VERSION ""

NS_ :

BS_:

BU_: PowertrainControlModule AtmosphericSensor SafetyRestraintSystem2 Aftertreatment_2_GasOutlet Aftertreatment_2_GasIntake DieselPartFilterControl Turbocharger SafetyRestraintSystem1 CabDisplay2 Aftertreatment_1_GasOutlet Aftertreatment_1_GasIntake OnBoardDataLogger OffBoardDiagnosticTool2 OffBoardDiagnosticTool1 FileServer ParkingBrakeController SeatController2 FanDriveController SteeringColumnUnit CommunicationUnitRadio CommunicationUnitSatellite CommunicationUnitCellular PropulsionBatteryCharger ChassisController2 ChassisController1 EngineValveControl AuxiliaryHeater2 AuxiliaryHeater1 ClutchUnit RampControl InformationSystem1 SuspensionSystemController2 OilSensor VehicleDynamicStability ExhaustEmissionController TransmissionDisplay2 TransmissionDisplay1 ClimateControl2 WaterPumpController RearAxleSteeringController LightingOperatorControl SeatController1 IgnitionController2 IgnitionController1 TirePressureController CabController2 CabController1 PneumaticSystemController SuspensionSystemController1 HydraulicPumpController EnduranceBrakingSystem RetarderExhaustEngine2 OnBoardDiagnosticUnit HeadwayController RetarderExhaustEngine1 CabDisplay1 ManagementComputer VirtualTerminal OffVehicleGateway PowerTakeOffFront HitchControl AuxiliaryValveControl BodyController TractorTrailerBridge1 StarterSystem ElectricalSystem VehicleSecurity VehicleNavigation AerodynamicControl ElectricalChargingSystem ClimateControl1 TripRecorder InstrumentCluster SuspensionDriveAxle2 SuspensionDriveAxle1 SuspensionSteerAxle SteeringController FuelSystem CruiseControl RetarderDriveline RetarderEngine BrakesDriveAxle2 BrakesDriveAxle1 BrakesSystemController BrakesSteerAxle AxleDrive2 AxleDrive1 AxleSteering PowerTakeOff ShiftConsoleSecondary ShiftConsolePrimary Transmission2 Transmission1 Engine2 Engine1

BO_ 2566842878 LFC1: 8 Vector__XXX
 SG_ EngTotalFuelUsed : 32|32@1+ (0.5,0) [0|2105540607.5] "L" Vector__XXX
 SG_ EngTripFuel : 0|32@1+ (0.5,0) [0|2105540607.5] "L" Vector__XXX

BO_ 2633883646 FWD: 8 Vector__XXX
 SG_ FrontWheelDriveActuatorStatus : 0|2@1+ (1,0) [0|3] "" Vector__XXX

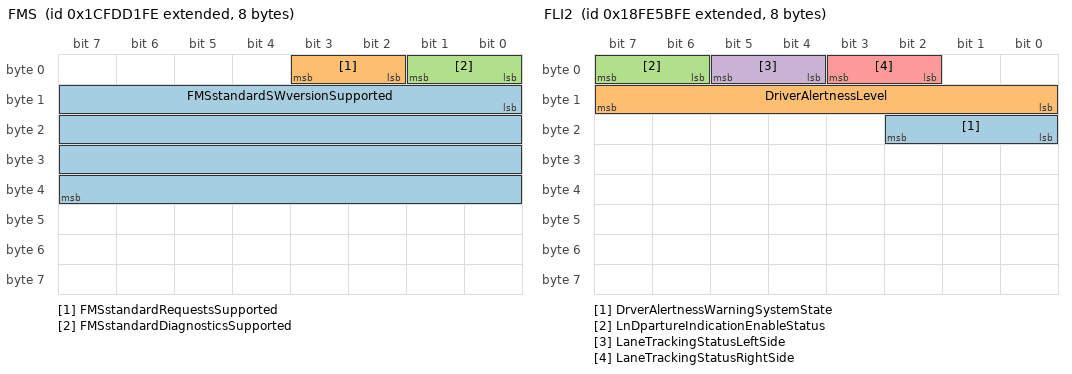
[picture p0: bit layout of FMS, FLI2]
BO_ 2633880062 FMS: 8 Vector__XXX
 SG_ FMSstandardSWversionSupported : 8|32@1+ (1,0) [0|255] "" Vector__XXX
 SG_ FMSstandardRequestsSupported : 2|2@1+ (1,0) [0|3] "" Vector__XXX
 SG_ FMSstandardDiagnosticsSupported : 0|2@1+ (1,0) [0|3] "" Vector__XXX

BO_ 2566806526 FLI2: 8 Vector__XXX
 SG_ DrverAlertnessWarningSystemState : 16|3@1+ (1,0) [0|7] "" Vector__XXX
 SG_ DriverAlertnessLevel : 8|8@1+ (0.4,0) [0|100] "%" Vector__XXX
 SG_ LnDpartureIndicationEnableStatus : 6|2@1+ (1,0) [0|3] "" Vector__XXX
 SG_ LaneTrackingStatusLeftSide : 4|2@1+ (1,0) [0|3] "" Vector__XXX
 SG_ LaneTrackingStatusRightSide : 2|2@1+ (1,0) [0|3] "" Vector__XXX

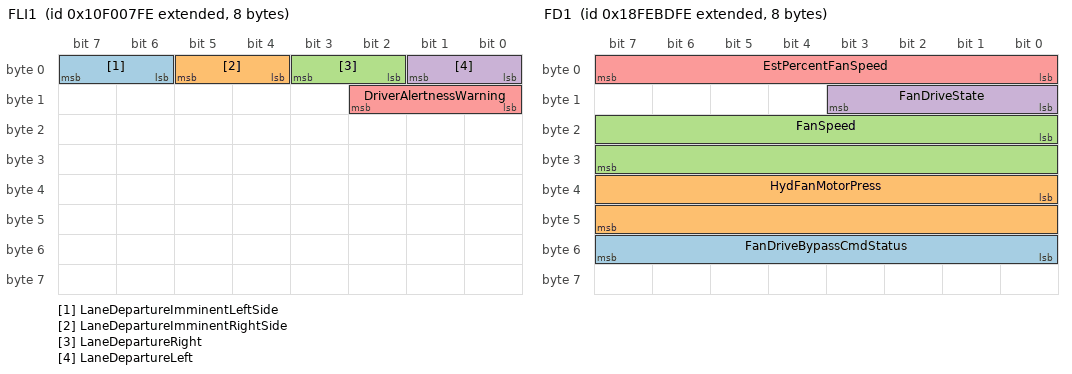
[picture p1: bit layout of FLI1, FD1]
BO_ 2431649790 FLI1: 8 Vector__XXX
 SG_ LaneDepartureImminentLeftSide : 6|2@1+ (1,0) [0|3] "" Vector__XXX
 SG_ LaneDepartureImminentRightSide : 4|2@1+ (1,0) [0|3] "" Vector__XXX
 SG_ LaneDepartureRight : 2|2@1+ (1,0) [0|3] "" Vector__XXX
 SG_ LaneDepartureLeft : 0|2@1+ (1,0) [0|3] "" Vector__XXX
 SG_ DriverAlertnessWarning : 8|3@1+ (1,0) [0|7] "" Vector__XXX

BO_ 2633929214 FL: 8 Vector__XXX
 SG_ EngFuelLeakage2 : 2|2@1+ (1,0) [0|3] "" Vector__XXX
 SG_ EngFuelLeakage1 : 0|2@1+ (1,0) [0|3] "" Vector__XXX

BO_ 2566831614 FD1: 8 Vector__XXX
 SG_ FanDriveBypassCmdStatus : 48|8@1+ (0.4,0) [0|100] "%" Vector__XXX
 SG_ HydFanMotorPress : 32|16@1+ (0.5,0) [0|32127.5] "kPa" Vector__XXX
 SG_ FanSpeed : 16|16@1+ (0.125,0) [0|8031.875] "rpm" Vector__XXX
 SG_ FanDriveState : 8|4@1+ (1,0) [0|15] "" Vector__XXX
 SG_ EstPercentFanSpeed : 0|8@1+ (0.4,0) [0|100] "%" Vector__XXX

BO_ 2566820094 ETH: 8 Vector__XXX
 SG_ EngTorqueLimit6AxleInput : 248|16@1+ (2,0) [0|128510] "Nm" Vector__XXX
 SG_ EngTorqueLimit5Switch : 232|16@1+ (1,0) [0|64255] "Nm" Vector__XXX
 SG_ EngTorqueLimit4Trans : 216|16@1+ (1,0) [0|64255] "Nm" Vector__XXX
 SG_ EngTorqueLimit3Trans : 200|16@1+ (1,0) [0|64255] "Nm" Vector__XXX
 SG_ TransGearRatio3 : 184|16@1+ (0.01,0) [0|642.55] "" Vector__XXX
 SG_ EngTorqueLimit2Trans : 168|16@1+ (1,0) [0|64255] "Nm" Vector__XXX
 SG_ TransGearRatio2 : 152|16@1+ (0.01,0) [0|642.55] "" Vector__XXX
 SG_ EngTorqueLimit1Trans : 136|16@1+ (1,0) [0|64255] "Nm" Vector__XXX
 SG_ TransGearRatio1 : 120|16@1+ (0.01,0) [0|642.55] "" Vector__XXX
 SG_ EngTorqueLimitFeature : 114|3@1+ (1,0) [0|7] "" Vector__XXX
 SG_ TorqueLimitingFeatureStatus : 112|2@1+ (1,0) [0|3] "" Vector__XXX
 SG_ CalibRecordDurationTime : 80|32@1+ (0.05,0) [0|210554060.75] "h" Vector__XXX
 SG_ CalibRecordStartYear : 72|8@1+ (1,1985) [1985|2235] "years" Vector__XXX
 SG_ CalibRecordStartDay : 64|8@1+ (0.25,0) [0.25|31.75] "days" Vector__XXX
 SG_ CalibRecordStartMonth : 56|8@1+ (1,0) [1|12] "months" Vector__XXX
 SG_ EngPeakTorque2 : 40|16@1+ (1,0) [0|64255] "Nm" Vector__XXX
 SG_ EngPeakTorque1 : 24|16@1+ (1,0) [0|64255] "Nm" Vector__XXX
 SG_ EngPower : 8|16@1+ (0.5,0) [0|32127.5] "kW" Vector__XXX
 SG_ NumberOfEngTorqueHistoryRecords : 0|8@1+ (1,0) [0|250] "records" Vector__XXX

BO_ 2364542206 ETC8: 8 Vector__XXX
 SG_ TransClutch_ConverterInputSpeed : 16|16@1+ (0.125,0) [0|8031.875] "rpm" Vector__XXX
 SG_ TransTorqueConverterRatio : 0|16@1+ (0.001,0) [0|64.255] "" Vector__XXX

BO_ 2566802174 ETC7: 8 Vector__XXX
 SG_ TransAutoNeutralSt : 50|2@1+ (1,0) [0|3] "" Vector__XXX
 SG_ TransWarningIndicator : 42|2@1+ (1,0) [0|3] "" Vector__XXX
 SG_ TrnsRverseGearShiftInhibitStatus : 40|2@1+ (1,0) [0|3] "" Vector__XXX
 SG_ TransMode8Indicator : 38|2@1+ (1,0) [0|3] "" Vector__XXX
 SG_ TransMode7Indicator : 36|2@1+ (1,0) [0|3] "" Vector__XXX
 SG_ TransMode6Indicator : 34|2@1+ (1,0) [0|3] "" Vector__XXX
 SG_ TransMode5Indicator : 32|2@1+ (1,0) [0|3] "" Vector__XXX
 SG_ TransRequestedGearFeedback : 24|8@1+ (1,-125) [-125|125] "" Vector__XXX
 SG_ TransMode1Indicator : 22|2@1+ (1,0) [0|3] "" Vector__XXX
 SG_ TransMode2Indicator : 20|2@1+ (1,0) [0|3] "" Vector__XXX
 SG_ TransMode3Indicator : 18|2@1+ (1,0) [0|3] "" Vector__XXX
 SG_ TransMode4Indicator : 16|2@1+ (1,0) [0|3] "" Vector__XXX
 SG_ TransShiftInhibitIndicator : 14|2@1+ (1,0) [0|3] "" Vector__XXX
 SG_ TransEngCrankEnable : 12|2@1+ (1,0) [0|3] "" Vector__XXX
 SG_ ActiveShiftConsoleIndicator : 10|2@1+ (1,0) [0|3] "" Vector__XXX
 SG_ TransReadyForBrakeRelease : 8|2@1+ (1,0) [0|3] "" Vector__XXX
 SG_ TrnsRqstedRangeDisplayFlashState : 6|2@1+ (1,0) [0|3] "" Vector__XXX
 SG_ TrnsRqstedRangeDisplayBlankState : 4|2@1+ (1,0) [0|3] "" Vector__XXX
 SG_ TransServiceIndicator : 2|2@1+ (1,0) [0|3] "" Vector__XXX
 SG_ TransAirSupplyPressIndicator : 48|2@1+ (1,0) [0|3] "" Vector__XXX
 SG_ TransMode10Indicator : 46|2@1+ (1,0) [0|3] "" Vector__XXX
 SG_ TransMode9Indicator : 44|2@1+ (1,0) [0|3] "" Vector__XXX
 SG_ TrnsCrrentRangeDisplayBlankState : 0|2@1+ (1,0) [0|3] "" Vector__XXX

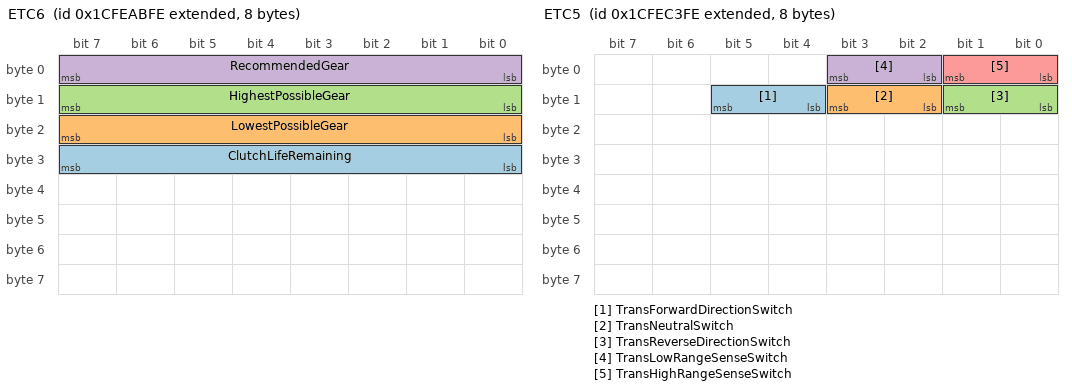
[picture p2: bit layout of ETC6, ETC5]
BO_ 2633935870 ETC6: 8 Vector__XXX
 SG_ ClutchLifeRemaining : 24|8@1+ (0.4,0) [0|100] "%" Vector__XXX
 SG_ LowestPossibleGear : 16|8@1+ (1,-125) [-125|125] "" Vector__XXX
 SG_ HighestPossibleGear : 8|8@1+ (1,-125) [-125|125] "" Vector__XXX
 SG_ RecommendedGear : 0|8@1+ (1,-125) [-125|125] "" Vector__XXX

BO_ 2633942014 ETC5: 8 Vector__XXX
 SG_ TransForwardDirectionSwitch : 12|2@1+ (1,0) [0|3] "" Vector__XXX
 SG_ TransNeutralSwitch : 10|2@1+ (1,0) [0|3] "" Vector__XXX
 SG_ TransReverseDirectionSwitch : 8|2@1+ (1,0) [0|3] "" Vector__XXX
 SG_ TransLowRangeSenseSwitch : 2|2@1+ (1,0) [0|3] "" Vector__XXX
 SG_ TransHighRangeSenseSwitch : 0|2@1+ (1,0) [0|3] "" Vector__XXX

BO_ 2633942526 ETC4: 8 Vector__XXX
 SG_ TransSynchronizerBrakeValue : 8|8@1+ (0.4,0) [0|100] "%" Vector__XXX
 SG_ TransSynchronizerClutchValue : 0|8@1+ (0.4,0) [0|100] "%" Vector__XXX

BO_ 2633943038 ETC3: 8 Vector__XXX
 SG_ TransInertiaBrakeActuator : 46|2@1+ (1,0) [0|3] "" Vector__XXX
 SG_ TransDefuelActuator : 44|2@1+ (1,0) [0|3] "" Vector__XXX
 SG_ TransLockupClutchActuator : 42|2@1+ (1,0) [0|3] "" Vector__XXX
 SG_ TransClutchActuator : 40|2@1+ (1,0) [0|3] "" Vector__XXX
 SG_ TransSplitterIndirectActuator : 38|2@1+ (1,0) [0|3] "" Vector__XXX
 SG_ TransSplitterDirectActuator : 36|2@1+ (1,0) [0|3] "" Vector__XXX
 SG_ TransRangeLowActuator : 34|2@1+ (1,0) [0|3] "" Vector__XXX
 SG_ TransRangeHighActuator : 32|2@1+ (1,0) [0|3] "" Vector__XXX
 SG_ TransShiftFingerGearActuator2 : 30|2@1+ (1,0) [0|3] "" Vector__XXX
 SG_ TransShiftFingerRailActuator2 : 28|2@1+ (1,0) [0|3] "" Vector__XXX
 SG_ TransShiftFingerGearActuator1 : 26|2@1+ (1,0) [0|3] "" Vector__XXX
 SG_ TransShiftFingerRailActuator1 : 24|2@1+ (1,0) [0|3] "" Vector__XXX
 SG_ TrnsShftFngerCenterRailIndicator : 20|2@1+ (1,0) [0|3] "" Vector__XXX
 SG_ TrnsShftFngerEngagementIndicator : 18|2@1+ (1,0) [0|3] "" Vector__XXX
 SG_ TransShiftFingerNeutralIndicator : 16|2@1+ (1,0) [0|3] "" Vector__XXX
 SG_ TransShiftFingerRailPos : 8|8@1+ (0.4,0) [0|100] "%" Vector__XXX
 SG_ TransShiftFingerGearPos : 0|8@1+ (0.4,0) [0|100] "%" Vector__XXX

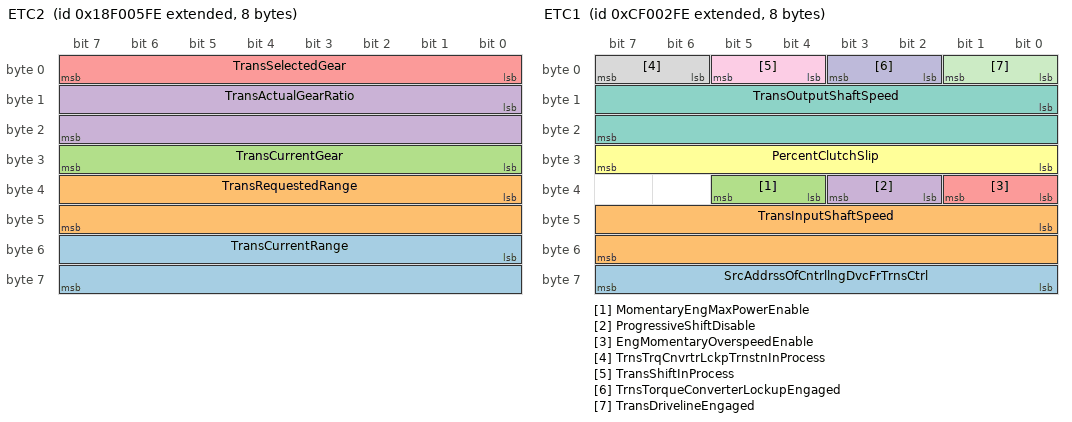
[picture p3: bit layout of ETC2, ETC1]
BO_ 2565867006 ETC2: 8 Vector__XXX
 SG_ TransCurrentRange : 48|16@1+ (1,0) [0|255] "" Vector__XXX
 SG_ TransRequestedRange : 32|16@1+ (1,0) [0|255] "" Vector__XXX
 SG_ TransCurrentGear : 24|8@1+ (1,-125) [-125|125] "" Vector__XXX
 SG_ TransActualGearRatio : 8|16@1+ (0.001,0) [0|64.255] "" Vector__XXX
 SG_ TransSelectedGear : 0|8@1+ (1,-125) [-125|125] "" Vector__XXX

BO_ 2364539646 ETC1: 8 Vector__XXX
 SG_ SrcAddrssOfCntrllngDvcFrTrnsCtrl : 56|8@1+ (1,0) [0|253] "" Vector__XXX
 SG_ TransInputShaftSpeed : 40|16@1+ (0.125,0) [0|8031.875] "rpm" Vector__XXX
 SG_ MomentaryEngMaxPowerEnable : 36|2@1+ (1,0) [0|3] "" Vector__XXX
 SG_ ProgressiveShiftDisable : 34|2@1+ (1,0) [0|3] "" Vector__XXX
 SG_ EngMomentaryOverspeedEnable : 32|2@1+ (1,0) [0|3] "" Vector__XXX
 SG_ PercentClutchSlip : 24|8@1+ (0.4,0) [0|100] "%" Vector__XXX
 SG_ TransOutputShaftSpeed : 8|16@1+ (0.125,0) [0|8031.875] "rpm" Vector__XXX
 SG_ TrnsTrqCnvrtrLckpTrnstnInProcess : 6|2@1+ (1,0) [0|3] "" Vector__XXX
 SG_ TransShiftInProcess : 4|2@1+ (1,0) [0|3] "" Vector__XXX
 SG_ TrnsTorqueConverterLockupEngaged : 2|2@1+ (1,0) [0|3] "" Vector__XXX
 SG_ TransDrivelineEngaged : 0|2@1+ (1,0) [0|3] "" Vector__XXX

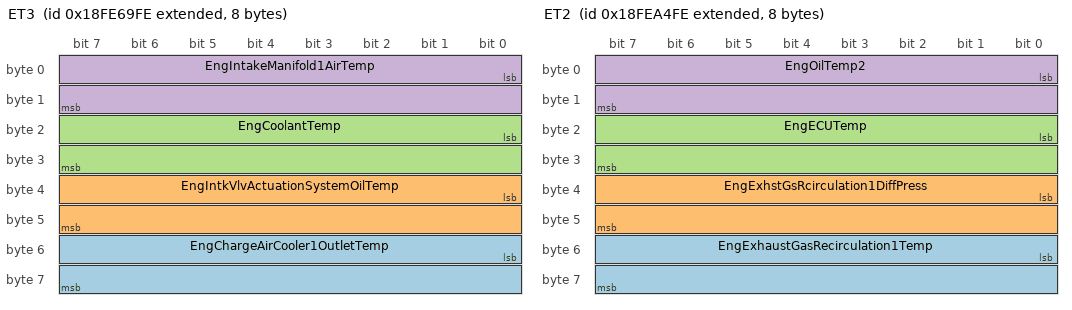
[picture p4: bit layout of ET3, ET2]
BO_ 2566810110 ET3: 8 Vector__XXX
 SG_ EngChargeAirCooler1OutletTemp : 48|16@1+ (0.03125,-273) [-273|1734.96875] "°C" Vector__XXX
 SG_ EngIntkVlvActuationSystemOilTemp : 32|16@1+ (0.03125,-273) [-273|1734.96875] "°C" Vector__XXX
 SG_ EngCoolantTemp : 16|16@1+ (0.03125,-273) [-273|1734.96875] "°C" Vector__XXX
 SG_ EngIntakeManifold1AirTemp : 0|16@1+ (0.03125,-273) [-273|1734.96875] "°C" Vector__XXX

BO_ 2566825214 ET2: 8 Vector__XXX
 SG_ EngExhaustGasRecirculation1Temp : 48|16@1+ (0.03125,-273) [-273|1734.96875] "°C" Vector__XXX
 SG_ EngExhstGsRcirculation1DiffPress : 32|16@1+ (0.0078125,-250) [-250|251.99] "kPa" Vector__XXX
 SG_ EngECUTemp : 16|16@1+ (0.03125,-273) [-273|1734.96875] "°C" Vector__XXX
 SG_ EngOilTemp2 : 0|16@1+ (0.03125,-273) [-273|1734.96875] "°C" Vector__XXX

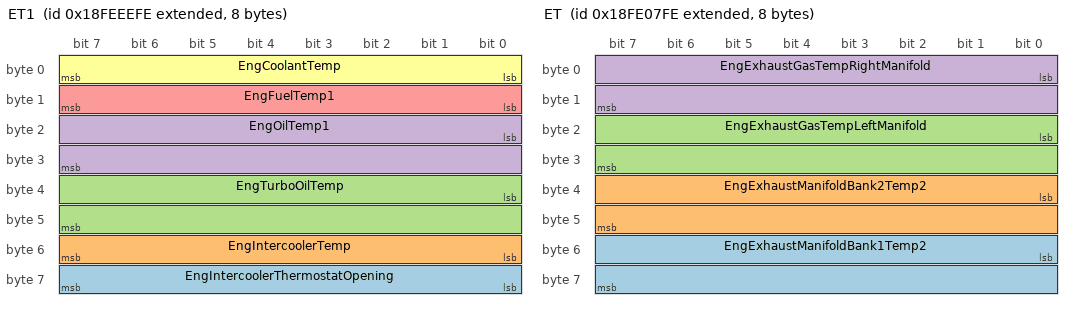
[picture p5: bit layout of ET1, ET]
BO_ 2566844158 ET1: 8 Vector__XXX
 SG_ EngIntercoolerThermostatOpening : 56|8@1+ (0.4,0) [0|100] "%" Vector__XXX
 SG_ EngIntercoolerTemp : 48|8@1+ (1,-40) [-40|210] "°C" Vector__XXX
 SG_ EngTurboOilTemp : 32|16@1+ (0.03125,-273) [-273|1734.96875] "°C" Vector__XXX
 SG_ EngOilTemp1 : 16|16@1+ (0.03125,-273) [-273|1734.96875] "°C" Vector__XXX
 SG_ EngFuelTemp1 : 8|8@1+ (1,-40) [-40|210] "°C" Vector__XXX
 SG_ EngCoolantTemp : 0|8@1+ (1,-40) [-40|210] "°C" Vector__XXX

BO_ 2566785022 ET: 8 Vector__XXX
 SG_ EngExhaustManifoldBank1Temp2 : 48|16@1+ (0.03125,-273) [-273|1734.96875] "°C" Vector__XXX
 SG_ EngExhaustManifoldBank2Temp2 : 32|16@1+ (0.03125,-273) [-273|1734.96875] "°C" Vector__XXX
 SG_ EngExhaustGasTempLeftManifold : 16|16@1+ (0.03125,-273) [-273|1734.96875] "°C" Vector__XXX
 SG_ EngExhaustGasTempRightManifold : 0|16@1+ (0.03125,-273) [-273|1734.96875] "°C" Vector__XXX

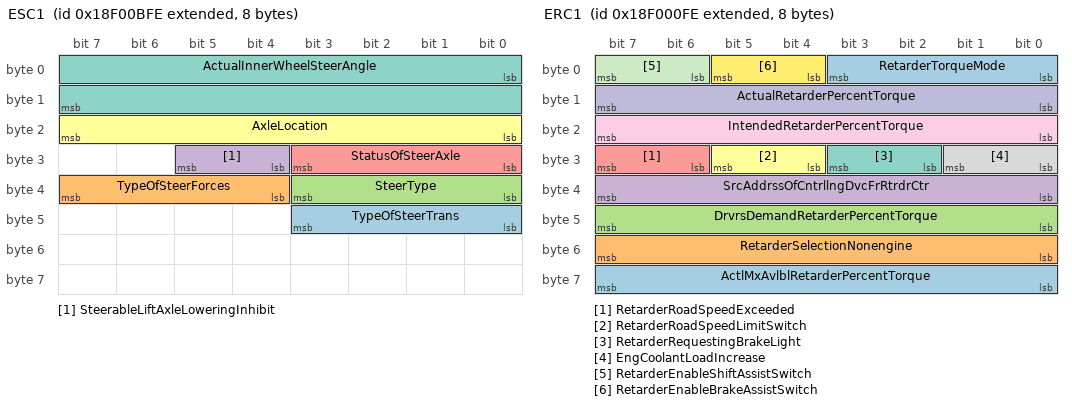
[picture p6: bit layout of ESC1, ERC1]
BO_ 2565868542 ESC1: 8 Vector__XXX
 SG_ TypeOfSteerTrans : 40|4@1+ (1,0) [0|15] "" Vector__XXX
 SG_ TypeOfSteerForces : 36|4@1+ (1,0) [0|15] "" Vector__XXX
 SG_ SteerType : 32|4@1+ (1,0) [0|15] "" Vector__XXX
 SG_ SteerableLiftAxleLoweringInhibit : 28|2@1+ (1,0) [0|3] "" Vector__XXX
 SG_ StatusOfSteerAxle : 24|4@1+ (1,0) [0|15] "" Vector__XXX
 SG_ AxleLocation : 16|8@1+ (1,0) [0|255] "" Vector__XXX
 SG_ ActualInnerWheelSteerAngle : 0|16@1+ (0.00390625,-125) [-125|125] "deg" Vector__XXX

BO_ 2633941758 ERC2: 8 Vector__XXX
 SG_ CrsCtrlRetarderActiveSpeedOffset : 8|16@1+ (0.00390625,-125) [0|125.996] "km/h" Vector__XXX
 SG_ TransOutputRetarder : 0|2@1+ (1,0) [0|3] "" Vector__XXX

BO_ 2565865726 ERC1: 8 Vector__XXX
 SG_ ActlMxAvlblRetarderPercentTorque : 56|8@1+ (1,-125) [-125|0] "%" Vector__XXX
 SG_ RetarderSelectionNonengine : 48|8@1+ (0.4,0) [0|100] "%" Vector__XXX
 SG_ DrvrsDemandRetarderPercentTorque : 40|8@1+ (1,-125) [-125|0] "%" Vector__XXX
 SG_ SrcAddrssOfCntrllngDvcFrRtrdrCtr : 32|8@1+ (1,0) [0|253] "" Vector__XXX
 SG_ RetarderRoadSpeedExceeded : 30|2@1+ (1,0) [0|3] "" Vector__XXX
 SG_ RetarderRoadSpeedLimitSwitch : 28|2@1+ (1,0) [0|3] "" Vector__XXX
 SG_ RetarderRequestingBrakeLight : 26|2@1+ (1,0) [0|3] "" Vector__XXX
 SG_ EngCoolantLoadIncrease : 24|2@1+ (1,0) [0|3] "" Vector__XXX
 SG_ IntendedRetarderPercentTorque : 16|8@1+ (1,-125) [-125|0] "%" Vector__XXX
 SG_ ActualRetarderPercentTorque : 8|8@1+ (1,-125) [-125|0] "%" Vector__XXX
 SG_ RetarderEnableShiftAssistSwitch : 6|2@1+ (1,0) [0|3] "" Vector__XXX
 SG_ RetarderEnableBrakeAssistSwitch : 4|2@1+ (1,0) [0|3] "" Vector__XXX
 SG_ RetarderTorqueMode : 0|4@1+ (1,0) [0|15] "" Vector__XXX

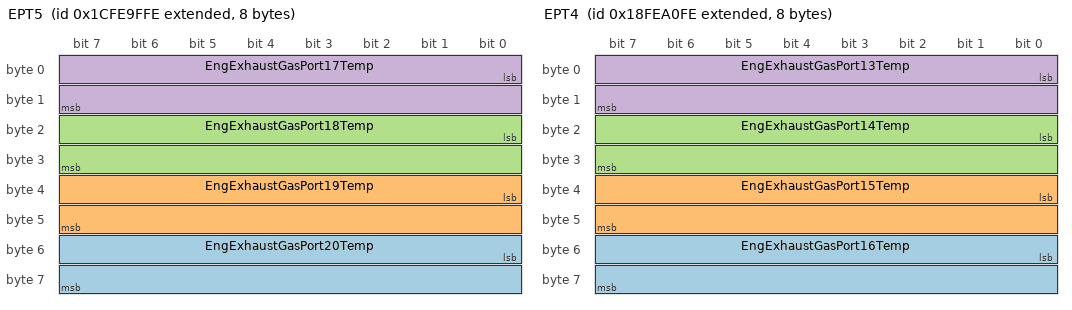
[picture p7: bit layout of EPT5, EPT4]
BO_ 2633932798 EPT5: 8 Vector__XXX
 SG_ EngExhaustGasPort20Temp : 48|16@1+ (0.03125,-273) [-273|1734.96875] "°C" Vector__XXX
 SG_ EngExhaustGasPort19Temp : 32|16@1+ (0.03125,-273) [-273|1734.96875] "°C" Vector__XXX
 SG_ EngExhaustGasPort18Temp : 16|16@1+ (0.03125,-273) [-273|1734.96875] "°C" Vector__XXX
 SG_ EngExhaustGasPort17Temp : 0|16@1+ (0.03125,-273) [-273|1734.96875] "°C" Vector__XXX

BO_ 2566824190 EPT4: 8 Vector__XXX
 SG_ EngExhaustGasPort16Temp : 48|16@1+ (0.03125,-273) [-273|1734.96875] "°C" Vector__XXX
 SG_ EngExhaustGasPort15Temp : 32|16@1+ (0.03125,-273) [-273|1734.96875] "°C" Vector__XXX
 SG_ EngExhaustGasPort14Temp : 16|16@1+ (0.03125,-273) [-273|1734.96875] "°C" Vector__XXX
 SG_ EngExhaustGasPort13Temp : 0|16@1+ (0.03125,-273) [-273|1734.96875] "°C" Vector__XXX

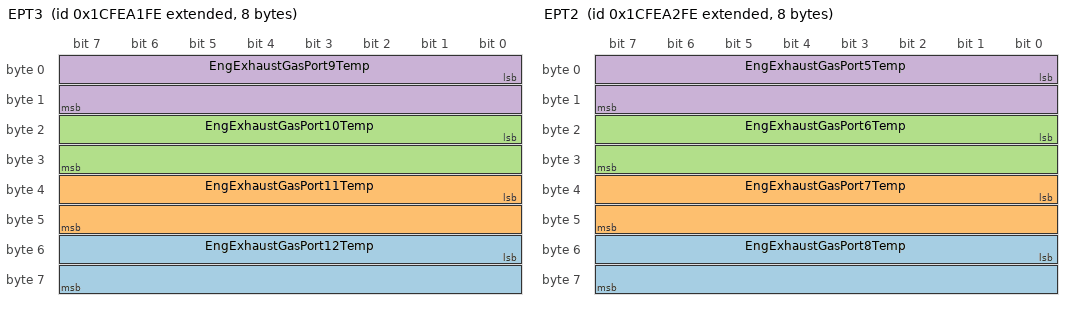
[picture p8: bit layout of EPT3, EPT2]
BO_ 2633933310 EPT3: 8 Vector__XXX
 SG_ EngExhaustGasPort12Temp : 48|16@1+ (0.03125,-273) [-273|1734.96875] "°C" Vector__XXX
 SG_ EngExhaustGasPort11Temp : 32|16@1+ (0.03125,-273) [-273|1734.96875] "°C" Vector__XXX
 SG_ EngExhaustGasPort10Temp : 16|16@1+ (0.03125,-273) [-273|1734.96875] "°C" Vector__XXX
 SG_ EngExhaustGasPort9Temp : 0|16@1+ (0.03125,-273) [-273|1734.96875] "°C" Vector__XXX

BO_ 2633933566 EPT2: 8 Vector__XXX
 SG_ EngExhaustGasPort8Temp : 48|16@1+ (0.03125,-273) [-273|1734.96875] "°C" Vector__XXX
 SG_ EngExhaustGasPort7Temp : 32|16@1+ (0.03125,-273) [-273|1734.96875] "°C" Vector__XXX
 SG_ EngExhaustGasPort6Temp : 16|16@1+ (0.03125,-273) [-273|1734.96875] "°C" Vector__XXX
 SG_ EngExhaustGasPort5Temp : 0|16@1+ (0.03125,-273) [-273|1734.96875] "°C" Vector__XXX

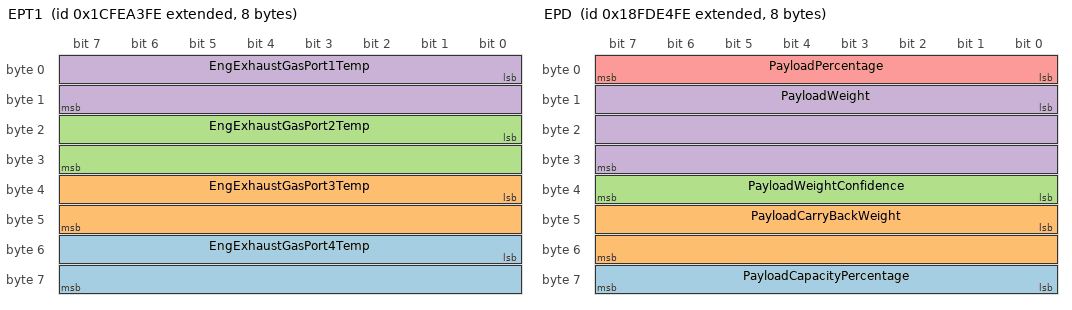
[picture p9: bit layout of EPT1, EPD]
BO_ 2633933822 EPT1: 8 Vector__XXX
 SG_ EngExhaustGasPort4Temp : 48|16@1+ (0.03125,-273) [-273|1734.96875] "°C" Vector__XXX
 SG_ EngExhaustGasPort3Temp : 32|16@1+ (0.03125,-273) [-273|1734.96875] "°C" Vector__XXX
 SG_ EngExhaustGasPort2Temp : 16|16@1+ (0.03125,-273) [-273|1734.96875] "°C" Vector__XXX
 SG_ EngExhaustGasPort1Temp : 0|16@1+ (0.03125,-273) [-273|1734.96875] "°C" Vector__XXX

BO_ 2566776062 EPD: 8 Vector__XXX
 SG_ PayloadCapacityPercentage : 56|8@1+ (1,0) [0|250] "%" Vector__XXX
 SG_ PayloadCarryBackWeight : 40|16@1+ (2,0) [0|128510] "kg" Vector__XXX
 SG_ PayloadWeightConfidence : 32|8@1+ (0.5,0) [0|100] "%" Vector__XXX
 SG_ PayloadWeight : 8|24@1+ (2,0) [0|32899070] "kg" Vector__XXX
 SG_ PayloadPercentage : 0|8@1+ (1,0) [0|250] "%" Vector__XXX

BO_ 2566771454 EP: 8 Vector__XXX
 SG_ DataMemoryUsage : 16|8@1+ (0.4,0) [0|100] "%" Vector__XXX
 SG_ KeepAliveBatteryConsumption : 0|16@1+ (1,0) [0|64255] "mAh" Vector__XXX

BO_ 2566775806 EOAC: 8 Vector__XXX
 SG_ TravelVelocityCtrlPos : 0|8@1+ (1,-125) [-125|125] "%" Vector__XXX

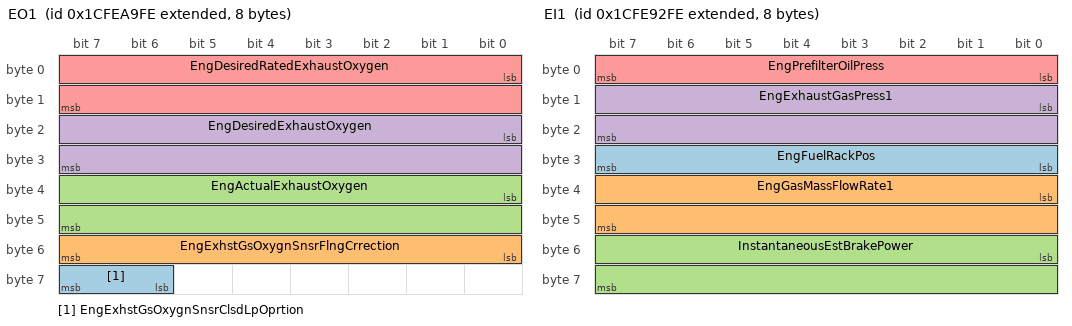
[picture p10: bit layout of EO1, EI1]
BO_ 2633935358 EO1: 8 Vector__XXX
 SG_ EngExhstGsOxygnSnsrClsdLpOprtion : 62|2@1+ (1,0) [0|3] "" Vector__XXX
 SG_ EngExhstGsOxygnSnsrFlngCrrection : 48|8@1+ (1,-125) [-125|125] "%" Vector__XXX
 SG_ EngActualExhaustOxygen : 32|16@1+ (0.0025,0) [0|160.6375] "%" Vector__XXX
 SG_ EngDesiredExhaustOxygen : 16|16@1+ (0.0025,0) [0|160.6375] "%" Vector__XXX
 SG_ EngDesiredRatedExhaustOxygen : 0|16@1+ (0.0025,0) [0|160.6375] "%" Vector__XXX

BO_ 2365447166 EJM3: 8 Vector__XXX
 SG_ Joystick3Button13PressedStatus : 62|2@1+ (1,0) [0|3] "" Vector__XXX
 SG_ Joystick3Button14PressedStatus : 60|2@1+ (1,0) [0|3] "" Vector__XXX
 SG_ Joystick3Button15PressedStatus : 58|2@1+ (1,0) [0|3] "" Vector__XXX
 SG_ Joystick3Button16PressedStatus : 56|2@1+ (1,0) [0|3] "" Vector__XXX
 SG_ Jystick3GripXAxisDetentPosStatus : 54|2@1+ (1,0) [0|3] "" Vector__XXX
 SG_ Jystick3GripYAxisDetentPosStatus : 52|2@1+ (1,0) [0|3] "" Vector__XXX
 SG_ Jystick3ThetaAxisDetentPosStatus : 50|2@1+ (1,0) [0|3] "" Vector__XXX
 SG_ Joystick3ThetaAxisPos : 38|10@1+ (0.1,0) [0|100] "%" Vector__XXX
 SG_ Jystck3ThtAxsClckwsPstvPosStatus : 36|2@1+ (1,0) [0|3] "" Vector__XXX
 SG_ Jystck3ThetaAxisNeutralPosStatus : 32|2@1+ (1,0) [0|3] "" Vector__XXX
 SG_ Joystick3GripYAxisPos : 22|10@1+ (0.1,0) [0|100] "%" Vector__XXX
 SG_ Jystck3GrpYAxsLvrFrwrdPstvPsStts : 20|2@1+ (1,0) [0|3] "" Vector__XXX
 SG_ Jystck3GrpYAxsLvrBckNgtvPsStatus : 18|2@1+ (1,0) [0|3] "" Vector__XXX
 SG_ Jystck3GripYAxisNeutralPosStatus : 16|2@1+ (1,0) [0|3] "" Vector__XXX
 SG_ Joystick3GripXAxisPos : 6|10@1+ (0.1,0) [0|100] "%" Vector__XXX
 SG_ Jystck3GrpXAxsLvrRghtPstvPsSttus : 4|2@1+ (1,0) [0|3] "" Vector__XXX
 SG_ Jystck3GrpXAxsLvrLftNgtvPsStatus : 2|2@1+ (1,0) [0|3] "" Vector__XXX
 SG_ Jystck3GripXAxisNeutralPosStatus : 0|2@1+ (1,0) [0|3] "" Vector__XXX
 SG_ Jystck3ThtAxsCntrClckwsNgtvPsStt : 34|2@1+ (1,0) [0|3] "" Vector__XXX

BO_ 2365446654 EJM2: 8 Vector__XXX
 SG_ Joystick2Button13PressedStatus : 62|2@1+ (1,0) [0|3] "" Vector__XXX
 SG_ Joystick2Button14PressedStatus : 60|2@1+ (1,0) [0|3] "" Vector__XXX
 SG_ Joystick2Button15PressedStatus : 58|2@1+ (1,0) [0|3] "" Vector__XXX
 SG_ Joystick2Button16PressedStatus : 56|2@1+ (1,0) [0|3] "" Vector__XXX
 SG_ Jystick2GripXAxisDetentPosStatus : 54|2@1+ (1,0) [0|3] "" Vector__XXX
 SG_ Jystick2GripYAxisDetentPosStatus : 52|2@1+ (1,0) [0|3] "" Vector__XXX
 SG_ Jystick2ThetaAxisDetentPosStatus : 50|2@1+ (1,0) [0|3] "" Vector__XXX
 SG_ Joystick2ThetaAxisPos : 38|10@1+ (0.1,0) [0|100] "%" Vector__XXX
 SG_ Jystck2ThtAxsClckwsPstvPosStatus : 36|2@1+ (1,0) [0|3] "" Vector__XXX
 SG_ Jystck2ThetaAxisNeutralPosStatus : 32|2@1+ (1,0) [0|3] "" Vector__XXX
 SG_ Joystick2GripYAxisPos : 22|10@1+ (0.1,0) [0|100] "%" Vector__XXX
 SG_ Jystck2GrpYAxsLvrFrwrdPstvPsStts : 20|2@1+ (1,0) [0|3] "" Vector__XXX
 SG_ Jystck2GrpYAxsLvrBckNgtvPsStatus : 18|2@1+ (1,0) [0|3] "" Vector__XXX
 SG_ Jystck2GripYAxisNeutralPosStatus : 16|2@1+ (1,0) [0|3] "" Vector__XXX
 SG_ Joystick2GripXAxisPos : 6|10@1+ (0.1,0) [0|100] "%" Vector__XXX
 SG_ Jystck2GrpXAxsLvrRghtPstvPsSttus : 4|2@1+ (1,0) [0|3] "" Vector__XXX
 SG_ Jystck2GrpXAxsLvrLftNgtvPsStatus : 2|2@1+ (1,0) [0|3] "" Vector__XXX
 SG_ Jystck2GripXAxisNeutralPosStatus : 0|2@1+ (1,0) [0|3] "" Vector__XXX
 SG_ Jystck2ThtAxsCntrClckwsNgtvPsStt : 34|2@1+ (1,0) [0|3] "" Vector__XXX

BO_ 2365446142 EJM1: 8 Vector__XXX
 SG_ Joystick1Button13PressedStatus : 62|2@1+ (1,0) [0|3] "" Vector__XXX
 SG_ Joystick1Button14PressedStatus : 60|2@1+ (1,0) [0|3] "" Vector__XXX
 SG_ Joystick1Button15PressedStatus : 58|2@1+ (1,0) [0|3] "" Vector__XXX
 SG_ Joystick1Button16PressedStatus : 56|2@1+ (1,0) [0|3] "" Vector__XXX
 SG_ Jystick1GripXAxisDetentPosStatus : 54|2@1+ (1,0) [0|3] "" Vector__XXX
 SG_ Jystick1GripYAxisDetentPosStatus : 52|2@1+ (1,0) [0|3] "" Vector__XXX
 SG_ Jystick1ThetaAxisDetentPosStatus : 50|2@1+ (1,0) [0|3] "" Vector__XXX
 SG_ Joystick1ThetaAxisPos : 38|10@1+ (0.1,0) [0|100] "%" Vector__XXX
 SG_ Jystck1ThtAxsClckwsPstvPosStatus : 36|2@1+ (1,0) [0|3] "" Vector__XXX
 SG_ Jystck1ThetaAxisNeutralPosStatus : 32|2@1+ (1,0) [0|3] "" Vector__XXX
 SG_ Joystick1GripYAxisPos : 22|10@1+ (0.1,0) [0|100] "%" Vector__XXX
 SG_ Jystck1GrpYAxsLvrFrwrdPstvPsStts : 20|2@1+ (1,0) [0|3] "" Vector__XXX
 SG_ Jystck1GrpYAxsLvrBckNgtvPsStatus : 18|2@1+ (1,0) [0|3] "" Vector__XXX
 SG_ Aftrtrtmnt1DslExhstFldPrprtsPrlm : 16|2@1+ (1,0) [0|3] "" Vector__XXX
 SG_ Joystick1GripXAxisPos : 6|10@1+ (0.1,0) [0|100] "%" Vector__XXX
 SG_ Jystck1GrpXAxsLvrRghtPstvPsSttus : 4|2@1+ (1,0) [0|3] "" Vector__XXX
 SG_ Jystck1GrpXAxsLvrLftNgtvPsStatus : 2|2@1+ (1,0) [0|3] "" Vector__XXX
 SG_ Jystck1GripXAxisNeutralPosStatus : 0|2@1+ (1,0) [0|3] "" Vector__XXX
 SG_ Jystck1ThtAxsCntrClckwsNgtvPsStt : 34|2@1+ (1,0) [0|3] "" Vector__XXX

BO_ 2633929470 EI1: 8 Vector__XXX
 SG_ EngFuelRackPos : 24|8@1+ (0.4,0) [0|100] "%" Vector__XXX
 SG_ EngGasMassFlowRate1 : 32|16@1+ (0.05,0) [0|3212.75] "kg/h" Vector__XXX
 SG_ InstantaneousEstBrakePower : 48|16@1+ (0.5,0) [0|32127.5] "kW" Vector__XXX
 SG_ EngExhaustGasPress1 : 8|16@1+ (0.0078125,-250) [-250|251.99] "kPa" Vector__XXX
 SG_ EngPrefilterOilPress : 0|8@1+ (4,0) [0|1000] "kPa" Vector__XXX

BO_ 2633937406 EH: 8 Vector__XXX
 SG_ TotalECURunTime : 32|32@1+ (0.05,0) [0|210554060.75] "h" Vector__XXX
 SG_ TotalECUDistance : 0|32@1+ (0.125,0) [0|526385151.875] "km" Vector__XXX

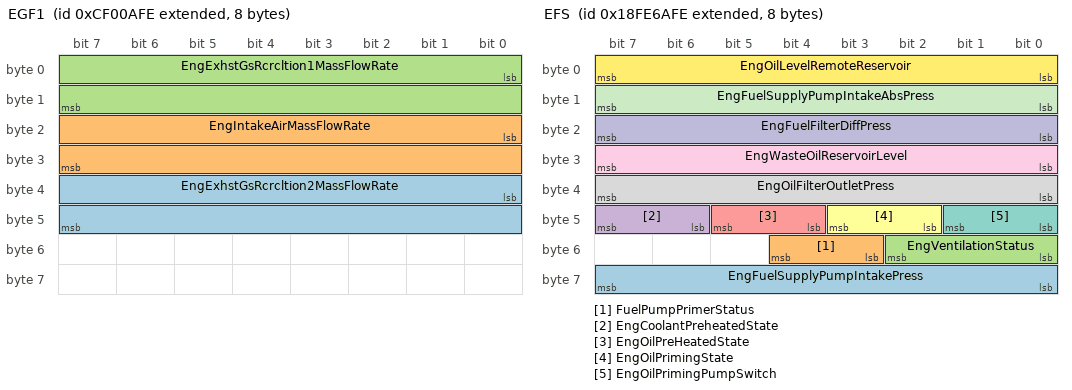
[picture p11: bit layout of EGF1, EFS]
BO_ 2364541694 EGF1: 8 Vector__XXX
 SG_ EngExhstGsRcrcltion2MassFlowRate : 32|16@1+ (0.05,0) [0|3212.75] "kg/h" Vector__XXX
 SG_ EngIntakeAirMassFlowRate : 16|16@1+ (0.05,0) [0|3212.75] "kg/h" Vector__XXX
 SG_ EngExhstGsRcrcltion1MassFlowRate : 0|16@1+ (0.05,0) [0|3212.75] "kg/h" Vector__XXX

BO_ 2566810366 EFS: 8 Vector__XXX
 SG_ EngFuelSupplyPumpIntakePress : 56|8@1+ (2,0) [0|500] "kPa" Vector__XXX
 SG_ FuelPumpPrimerStatus : 51|2@1+ (1,0) [0|3] "" Vector__XXX
 SG_ EngVentilationStatus : 48|3@1+ (1,0) [0|7] "" Vector__XXX
 SG_ EngCoolantPreheatedState : 46|2@1+ (1,0) [0|3] "" Vector__XXX
 SG_ EngOilPreHeatedState : 44|2@1+ (1,0) [0|3] "" Vector__XXX
 SG_ EngOilPrimingState : 42|2@1+ (1,0) [0|3] "" Vector__XXX
 SG_ EngOilPrimingPumpSwitch : 40|2@1+ (1,0) [0|3] "" Vector__XXX
 SG_ EngOilFilterOutletPress : 32|8@1+ (4,0) [0|1000] "kPa" Vector__XXX
 SG_ EngWasteOilReservoirLevel : 24|8@1+ (0.4,0) [0|100] "%" Vector__XXX
 SG_ EngFuelFilterDiffPress : 16|8@1+ (2,0) [0|500] "kPa" Vector__XXX
 SG_ EngFuelSupplyPumpIntakeAbsPress : 8|8@1+ (2,0) [0|500] "kPa" Vector__XXX
 SG_ EngOilLevelRemoteReservoir : 0|8@1+ (0.4,0) [0|100] "%" Vector__XXX

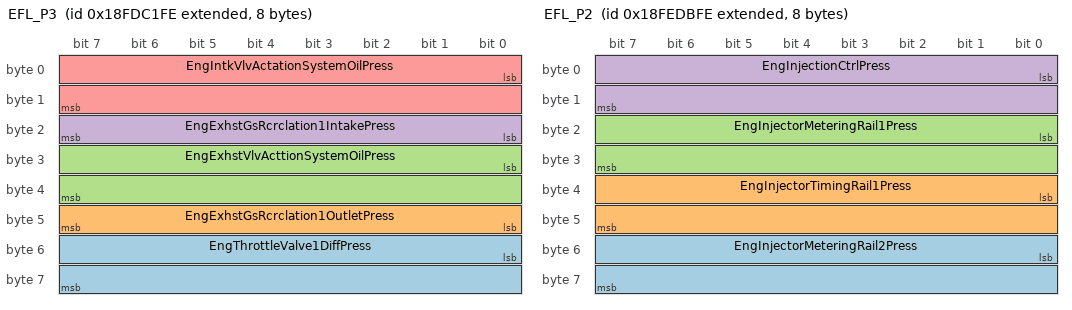
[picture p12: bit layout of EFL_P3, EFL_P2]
BO_ 2566767102 EFL_P3: 8 Vector__XXX
 SG_ EngThrottleValve1DiffPress : 48|16@1+ (0.1,0) [0|6425.5] "kPa" Vector__XXX
 SG_ EngExhstGsRcrclation1OutletPress : 40|8@1+ (2,0) [0|500] "kPa" Vector__XXX
 SG_ EngExhstVlvActtionSystemOilPress : 24|16@1+ (0.00390625,0) [0|250.996] "MPa" Vector__XXX
 SG_ EngExhstGsRcrclation1IntakePress : 16|8@1+ (2,0) [0|500] "kPa" Vector__XXX
 SG_ EngIntkVlvActationSystemOilPress : 0|16@1+ (0.00390625,0) [0|250.996] "MPa" Vector__XXX

BO_ 2566839294 EFL_P2: 8 Vector__XXX
 SG_ EngInjectorMeteringRail2Press : 48|16@1+ (0.00390625,0) [0|250.996] "MPa" Vector__XXX
 SG_ EngInjectorTimingRail1Press : 32|16@1+ (0.00390625,0) [0|250.996] "MPa" Vector__XXX
 SG_ EngInjectorMeteringRail1Press : 16|16@1+ (0.00390625,0) [0|250.996] "MPa" Vector__XXX
 SG_ EngInjectionCtrlPress : 0|16@1+ (0.00390625,0) [0|250.996] "MPa" Vector__XXX

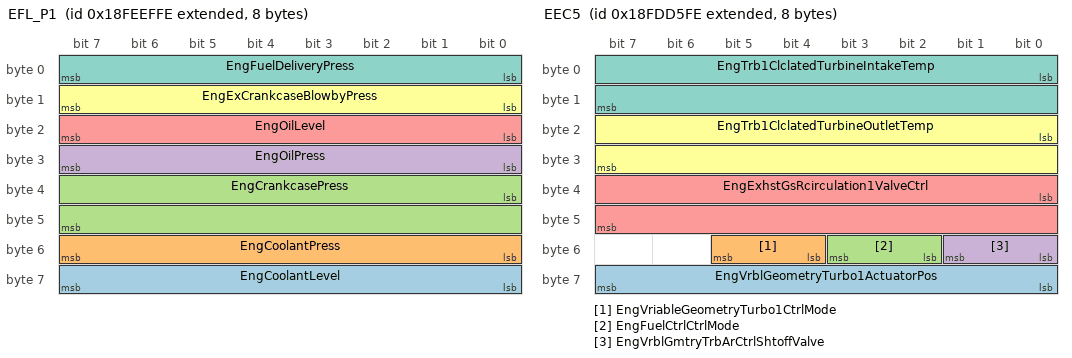
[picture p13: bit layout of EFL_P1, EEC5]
BO_ 2566844414 EFL_P1: 8 Vector__XXX
 SG_ EngCoolantLevel : 56|8@1+ (0.4,0) [0|100] "%" Vector__XXX
 SG_ EngCoolantPress : 48|8@1+ (2,0) [0|500] "kPa" Vector__XXX
 SG_ EngCrankcasePress : 32|16@1+ (0.0078125,-250) [-250|251.99] "kPa" Vector__XXX
 SG_ EngOilPress : 24|8@1+ (4,0) [0|1000] "kPa" Vector__XXX
 SG_ EngOilLevel : 16|8@1+ (0.4,0) [0|100] "%" Vector__XXX
 SG_ EngExCrankcaseBlowbyPress : 8|8@1+ (0.05,0) [0|12.5] "kPa" Vector__XXX
 SG_ EngFuelDeliveryPress : 0|8@1+ (4,0) [0|1000] "kPa" Vector__XXX

BO_ 2633929726 EES: 8 Vector__XXX
 SG_ SafetyWireStatus : 16|2@1+ (1,0) [0|3] "" Vector__XXX
 SG_ ElectricalLoad : 0|16@1+ (0.5,0) [0|32127.5] "kW" Vector__XXX

BO_ 2566772222 EEC5: 8 Vector__XXX
 SG_ EngVrblGeometryTurbo1ActuatorPos : 56|8@1+ (0.4,0) [0|100] "%" Vector__XXX
 SG_ EngVriableGeometryTurbo1CtrlMode : 52|2@1+ (1,0) [0|3] "" Vector__XXX
 SG_ EngFuelCtrlCtrlMode : 50|2@1+ (1,0) [0|3] "" Vector__XXX
 SG_ EngVrblGmtryTrbArCtrlShtoffValve : 48|2@1+ (1,0) [0|3] "" Vector__XXX
 SG_ EngExhstGsRcirculation1ValveCtrl : 32|16@1+ (0.0025,0) [0|100] "%" Vector__XXX
 SG_ EngTrb1ClclatedTurbineOutletTemp : 16|16@1+ (0.03125,-273) [-273|1734.96875] "°C" Vector__XXX
 SG_ EngTrb1ClclatedTurbineIntakeTemp : 0|16@1+ (0.03125,-273) [-273|1734.96875] "°C" Vector__XXX

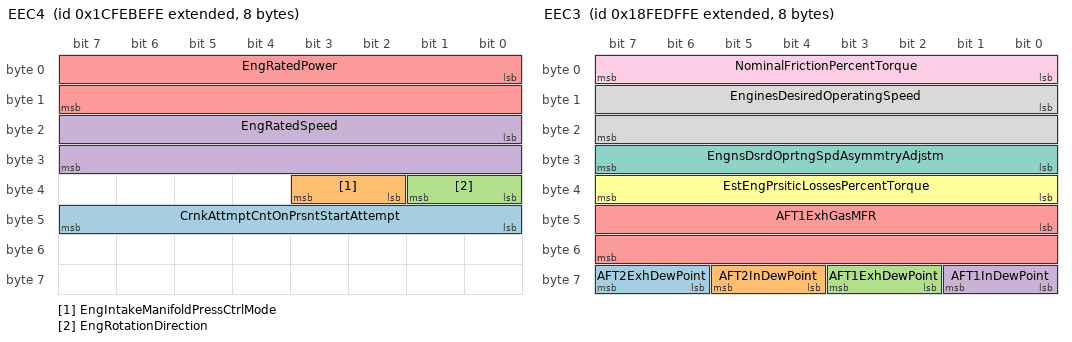
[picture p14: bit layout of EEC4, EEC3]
BO_ 2633940734 EEC4: 8 Vector__XXX
 SG_ CrnkAttmptCntOnPrsntStartAttempt : 40|8@1+ (1,0) [0|250] "" Vector__XXX
 SG_ EngIntakeManifoldPressCtrlMode : 34|2@1+ (1,0) [0|3] "" Vector__XXX
 SG_ EngRotationDirection : 32|2@1+ (1,0) [0|3] "" Vector__XXX
 SG_ EngRatedSpeed : 16|16@1+ (0.125,0) [0|8031.875] "rpm" Vector__XXX
 SG_ EngRatedPower : 0|16@1+ (0.5,0) [0|32127.5] "kW" Vector__XXX

BO_ 2566840318 EEC3: 8 Vector__XXX
 SG_ AFT2ExhDewPoint : 62|2@1+ (1,0) [0|3] "" Vector__XXX
 SG_ AFT2InDewPoint : 60|2@1+ (1,0) [0|3] "" Vector__XXX
 SG_ AFT1ExhDewPoint : 58|2@1+ (1,0) [0|3] "" Vector__XXX
 SG_ AFT1InDewPoint : 56|2@1+ (1,0) [0|3] "" Vector__XXX
 SG_ AFT1ExhGasMFR : 40|16@1+ (0.2,0) [0|12851] "kg/h" Vector__XXX
 SG_ EstEngPrsiticLossesPercentTorque : 32|8@1+ (1,-125) [0|125] "%" Vector__XXX
 SG_ EngnsDsrdOprtngSpdAsymmtryAdjstm : 24|8@1+ (1,0) [0|250] "" Vector__XXX
 SG_ EnginesDesiredOperatingSpeed : 8|16@1+ (0.125,0) [0|8031.875] "rpm" Vector__XXX
 SG_ NominalFrictionPercentTorque : 0|8@1+ (1,-125) [-125|125] "%" Vector__XXX

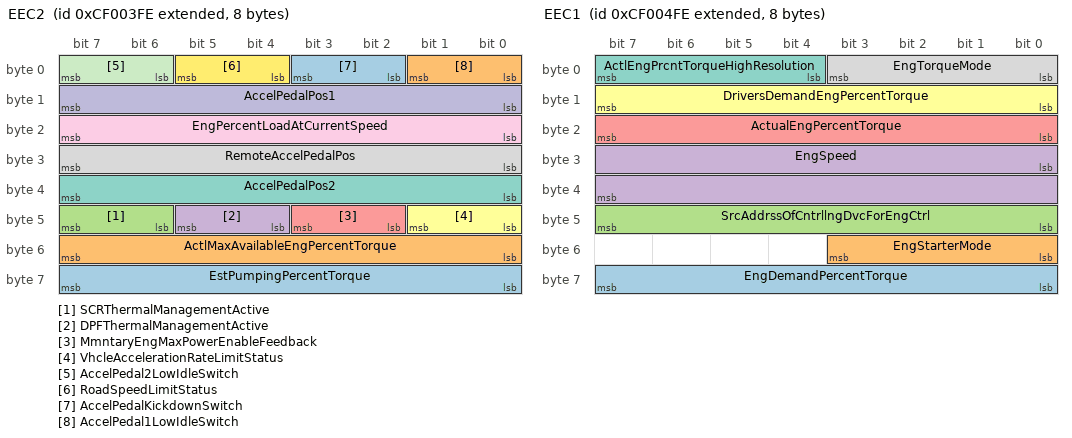
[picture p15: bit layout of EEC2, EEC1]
BO_ 2364539902 EEC2: 8 Vector__XXX
 SG_ EstPumpingPercentTorque : 56|8@1+ (1,-125) [-125|125] "%" Vector__XXX
 SG_ ActlMaxAvailableEngPercentTorque : 48|8@1+ (0.4,0) [0|100] "%" Vector__XXX
 SG_ SCRThermalManagementActive : 46|2@1+ (1,0) [0|3] "" Vector__XXX
 SG_ DPFThermalManagementActive : 44|2@1+ (1,0) [0|3] "" Vector__XXX
 SG_ MmntaryEngMaxPowerEnableFeedback : 42|2@1+ (1,0) [0|3] "" Vector__XXX
 SG_ VhcleAccelerationRateLimitStatus : 40|2@1+ (1,0) [0|3] "" Vector__XXX
 SG_ AccelPedalPos2 : 32|8@1+ (0.4,0) [0|100] "%" Vector__XXX
 SG_ RemoteAccelPedalPos : 24|8@1+ (0.4,0) [0|100] "%" Vector__XXX
 SG_ EngPercentLoadAtCurrentSpeed : 16|8@1+ (1,0) [0|125] "%" Vector__XXX
 SG_ AccelPedalPos1 : 8|8@1+ (0.4,0) [0|100] "%" Vector__XXX
 SG_ AccelPedal2LowIdleSwitch : 6|2@1+ (1,0) [0|3] "" Vector__XXX
 SG_ RoadSpeedLimitStatus : 4|2@1+ (1,0) [0|3] "" Vector__XXX
 SG_ AccelPedalKickdownSwitch : 2|2@1+ (1,0) [0|3] "" Vector__XXX
 SG_ AccelPedal1LowIdleSwitch : 0|2@1+ (1,0) [0|3] "" Vector__XXX

BO_ 2364540158 EEC1: 8 Vector__XXX
 SG_ EngDemandPercentTorque : 56|8@1+ (1,-125) [-125|125] "%" Vector__XXX
 SG_ EngStarterMode : 48|4@1+ (1,0) [0|15] "" Vector__XXX
 SG_ SrcAddrssOfCntrllngDvcForEngCtrl : 40|8@1+ (1,0) [0|253] "" Vector__XXX
 SG_ EngSpeed : 24|16@1+ (0.125,0) [0|8031.875] "rpm" Vector__XXX
 SG_ ActualEngPercentTorque : 16|8@1+ (1,-125) [0|125] "%" Vector__XXX
 SG_ DriversDemandEngPercentTorque : 8|8@1+ (1,-125) [0|125] "%" Vector__XXX
 SG_ ActlEngPrcntTorqueHighResolution : 4|4@1+ (0.125,0) [0|0.875] "%" Vector__XXX
 SG_ EngTorqueMode : 0|4@1+ (1,0) [0|15] "" Vector__XXX

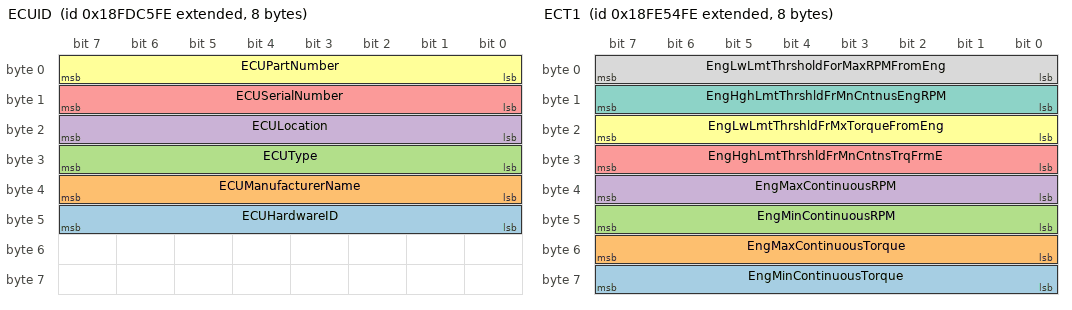
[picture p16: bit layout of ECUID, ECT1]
BO_ 2566768126 ECUID: 8 Vector__XXX
 SG_ ECUHardwareID : 40|8@1+ (1,0) [0|255] "" Vector__XXX
 SG_ ECUManufacturerName : 32|8@1+ (1,0) [0|255] "" Vector__XXX
 SG_ ECUType : 24|8@1+ (1,0) [0|255] "" Vector__XXX
 SG_ ECULocation : 16|8@1+ (1,0) [0|255] "" Vector__XXX
 SG_ ECUSerialNumber : 8|8@1+ (1,0) [0|255] "" Vector__XXX
 SG_ ECUPartNumber : 0|8@1+ (1,0) [0|255] "" Vector__XXX

BO_ 2566804734 ECT1: 8 Vector__XXX
 SG_ EngMinContinuousTorque : 56|8@1+ (1,-125) [-125|125] "%" Vector__XXX
 SG_ EngMaxContinuousTorque : 48|8@1+ (1,-125) [-125|125] "%" Vector__XXX
 SG_ EngMinContinuousRPM : 40|8@1+ (32,0) [0|8000] "rpm" Vector__XXX
 SG_ EngMaxContinuousRPM : 32|8@1+ (32,0) [0|8000] "rpm" Vector__XXX
 SG_ EngHghLmtThrshldFrMnCntnsTrqFrmE : 24|8@1+ (1,-125) [-125|125] "%" Vector__XXX
 SG_ EngLwLmtThrshldFrMxTorqueFromEng : 16|8@1+ (1,-125) [-125|125] "%" Vector__XXX
 SG_ EngHghLmtThrshldFrMnCntnusEngRPM : 8|8@1+ (32,0) [0|8000] "rpm" Vector__XXX
 SG_ EngLwLmtThrsholdForMaxRPMFromEng : 0|8@1+ (32,0) [0|8000] "rpm" Vector__XXX

BO_ 2566841342 EC1: 39 Vector__XXX
 SG_ SupportTSC1CtrlPurposeGroup4 : 304|8@1+ (1,0) [0|255] "" Vector__XXX
 SG_ SupportTSC1CtrlPurposeGroup3 : 296|8@1+ (1,0) [0|255] "" Vector__XXX
 SG_ SupportTSC1CtrlPurposeGroup2 : 288|8@1+ (1,0) [0|255] "" Vector__XXX
 SG_ SupportTSC1CtrlPurposeGroup1 : 280|8@1+ (1,0) [0|255] "" Vector__XXX
 SG_ SupportVariableRateTSC1Message : 272|8@1+ (1,0) [0|255] "" Vector__XXX
 SG_ EngDefaultTorqueLimit : 256|16@1+ (1,0) [0|64255] "Nm" Vector__XXX
 SG_ EngMomentOfInertia : 240|16@1+ (0.004,0) [0|257.02] "kg•m²" Vector__XXX
 SG_ EngExRngRqstdSpdCtrlRngUpprLimit : 224|16@1+ (0.125,0) [0|8031.875] "rpm" Vector__XXX
 SG_ EngRqstdTrqueCtrlRangeUpperLimit : 216|8@1+ (1,-125) [0|125] "%" Vector__XXX
 SG_ EngRqstdTrqueCtrlRangeLowerLimit : 208|8@1+ (1,-125) [0|125] "%" Vector__XXX
 SG_ EngRqstdSpeedCtrlRangeUpperLimit : 200|8@1+ (10,0) [0|2500] "rpm" Vector__XXX
 SG_ EngRqstdSpeedCtrlRangeLowerLimit : 192|8@1+ (10,0) [0|2500] "rpm" Vector__XXX
 SG_ EngMaxMomentaryOverrideTimeLimit : 184|8@1+ (0.1,0) [0|25] "s" Vector__XXX
 SG_ EngMxMmentaryOverrideSpeedPoint7 : 168|16@1+ (0.125,0) [0|8031.875] "rpm" Vector__XXX
 SG_ EngReferenceTorque : 152|16@1+ (1,0) [0|64255] "Nm" Vector__XXX
 SG_ EngGain : 136|16@1+ (0.00078125,0) [0|50.19] "%/rpm" Vector__XXX
 SG_ EngSpeedAtHighIdlePoint6 : 120|16@1+ (0.125,0) [0|8031.875] "rpm" Vector__XXX
 SG_ EngPercentTorqueAtPoint5 : 112|8@1+ (1,-125) [0|125] "%" Vector__XXX
 SG_ EngSpeedAtPoint5 : 96|16@1+ (0.125,0) [0|8031.875] "rpm" Vector__XXX
 SG_ EngPercentTorqueAtPoint4 : 88|8@1+ (1,-125) [0|125] "%" Vector__XXX
 SG_ EngSpeedAtPoint4 : 72|16@1+ (0.125,0) [0|8031.875] "rpm" Vector__XXX
 SG_ EngPercentTorqueAtPoint3 : 64|8@1+ (1,-125) [0|125] "%" Vector__XXX
 SG_ EngSpeedAtPoint3 : 48|16@1+ (0.125,0) [0|8031.875] "rpm" Vector__XXX
 SG_ EngPercentTorqueAtPoint2 : 40|8@1+ (1,-125) [0|125] "%" Vector__XXX
 SG_ EngSpeedAtPoint2 : 24|16@1+ (0.125,0) [0|8031.875] "rpm" Vector__XXX
 SG_ EngPercentTorqueAtIdlePoint1 : 16|8@1+ (1,-125) [0|125] "%" Vector__XXX
 SG_ EngSpeedAtIdlePoint1 : 0|16@1+ (0.125,0) [0|8031.875] "rpm" Vector__XXX

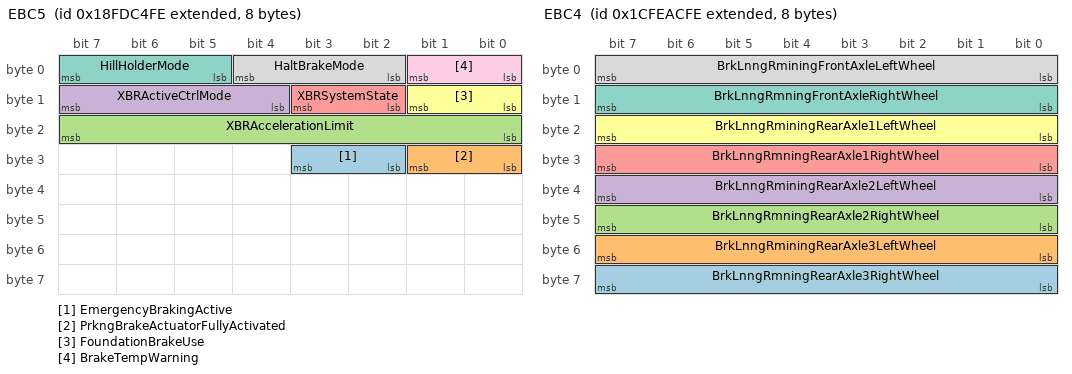
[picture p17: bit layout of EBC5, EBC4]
BO_ 2566767870 EBC5: 8 Vector__XXX
 SG_ EmergencyBrakingActive : 26|2@1+ (1,0) [0|3] "" Vector__XXX
 SG_ PrkngBrakeActuatorFullyActivated : 24|2@1+ (1,0) [0|3] "" Vector__XXX
 SG_ XBRAccelerationLimit : 16|8@1+ (0.1,-12.5) [-10|10] "m/s²" Vector__XXX
 SG_ XBRActiveCtrlMode : 12|4@1+ (1,0) [0|15] "" Vector__XXX
 SG_ XBRSystemState : 10|2@1+ (1,0) [0|3] "" Vector__XXX
 SG_ FoundationBrakeUse : 8|2@1+ (1,0) [0|3] "" Vector__XXX
 SG_ HillHolderMode : 5|3@1+ (1,0) [0|7] "" Vector__XXX
 SG_ HaltBrakeMode : 2|3@1+ (1,0) [0|7] "" Vector__XXX
 SG_ BrakeTempWarning : 0|2@1+ (1,0) [0|3] "" Vector__XXX

BO_ 2633936126 EBC4: 8 Vector__XXX
 SG_ BrkLnngRmningRearAxle3RightWheel : 56|8@1+ (0.4,0) [0|100] "%" Vector__XXX
 SG_ BrkLnngRminingRearAxle3LeftWheel : 48|8@1+ (0.4,0) [0|100] "%" Vector__XXX
 SG_ BrkLnngRmningRearAxle2RightWheel : 40|8@1+ (0.4,0) [0|100] "%" Vector__XXX
 SG_ BrkLnngRminingRearAxle2LeftWheel : 32|8@1+ (0.4,0) [0|100] "%" Vector__XXX
 SG_ BrkLnngRmningRearAxle1RightWheel : 24|8@1+ (0.4,0) [0|100] "%" Vector__XXX
 SG_ BrkLnngRminingRearAxle1LeftWheel : 16|8@1+ (0.4,0) [0|100] "%" Vector__XXX
 SG_ BrkLnngRmningFrontAxleRightWheel : 8|8@1+ (0.4,0) [0|100] "%" Vector__XXX
 SG_ BrkLnngRminingFrontAxleLeftWheel : 0|8@1+ (0.4,0) [0|100] "%" Vector__XXX

CM_ BO_ 2566842878 "Fuel Consumption (Liquid) 1
Engine fuel consumption accumulators.  See PGN 64777 for alternate resolution.";
CM_ SG_ 2566842878 EngTotalFuelUsed "Accumulated amount of fuel used during vehicle operation.  See SPN 5054 for alternate resolution.";
CM_ SG_ 2566842878 EngTripFuel "Fuel consumed during all or part of a journey.  See SPN 5053 for alternate resolution.";
CM_ BO_ 2633883646 "Front Wheel Drive Status
Front wheel drive ECU information";
CM_ SG_ 2633883646 FrontWheelDriveActuatorStatus "Feedback on the front wheel drive actuator.

00 Front Wheel Drive Actuator not engaged
01 Front Wheel Drive Actuator engaged
10 Error
11 Not Available";
CM_ BO_ 2633880062 "FMS-standard Interface Identity/Capabilities
Information which specifies the capabilities of the Fleet Management System (FMS) - standard interface device. This PGN typically is sourced from the network interconnect FMS - standard interface device.";
CM_ SG_ 2633880062 FMSstandardSWversionSupported "Information that identifies which issue level of the FMS-standard document the software included in the FMS gateway supports. Four bytes, representing xx.yy type revision level identification.
Information to be ASCII equivalent of the numeric ...";
CM_ SG_ 2633880062 FMSstandardRequestsSupported "Status signal which indicates if the FMS Vehicle Interface (FMS Gateway) will respond to requests from the FMS device for the PGNs listed in the FMS Interface Specification.
This mode is to support FMS  gateway devices that only operate in a ...";
CM_ SG_ 2633880062 FMSstandardDiagnosticsSupported "Status signal which indicates if the FMS Vehicle Interface (FMS Gateway) supports the handling of diagnostic messages from the vehicle network onto the FMS network.
The FMS gateway does NOT support the re-broadcast of diagnostics messages present ...";
CM_ BO_ 2566806526 "Forward Lane Image 2";
CM_ SG_ 2566806526 DrverAlertnessWarningSystemState "Indicates the various system state in the driver alertness warning system. This signal can be used independent of the technology and ECU used to estimate the driver alertness condition.
000 = System installed but disabled
001 = Initializing
010 = ...";
CM_ SG_ 2566806526 DriverAlertnessLevel "Indicates the alertness level of the driver measured by the driver alertness warning system. 100 % means driver is fully attentive. This signal can be used independent of the technology and ECU used to estimate the driver alertness condition.";
CM_ SG_ 2566806526 LnDpartureIndicationEnableStatus "Indicates whether lane departure indication is active.

00 Lane Departure indication disabled
01 Lane Departure Indication enabled 
10 Reserved
11 Not Used";
CM_ SG_ 2566806526 LaneTrackingStatusLeftSide "Indicates whether the left side is tracking lane.

00 Not Tracking Left side
01 Tracking Left side
10 Reserved
11 Don't care/Take no action";
CM_ SG_ 2566806526 LaneTrackingStatusRightSide "Indicates whether right side is tracking lane.

00 Not Tracking Right side
01 Tracking Right side
10 Reserved
11 Don't Care/take no action";
CM_ BO_ 2431649790 "Forward Lane Image 1";
CM_ SG_ 2431649790 LaneDepartureImminentLeftSide "Indicates departure imminent on left side of lane.

00 Not imminent
01 Imminent
10 Reserved
11 Not used";
CM_ SG_ 2431649790 LaneDepartureImminentRightSide "Indicates departure imminent on right side of lane.

00 Not imminent
01 Imminent
10 Reserved
11 Not Used";
CM_ SG_ 2431649790 LaneDepartureRight "Indicates that the middle of vehicle departs the lane on the right side. The parameter indicates that the vehicle is changing the lane to the right.
00   Middle of the vehicle does not depart the lane to the right side
01   Middle of the vehicle ...";
CM_ SG_ 2431649790 LaneDepartureLeft "Indicates that the middle of vehicle departs the lane on the left side. The parameter indicates that the vehicle is changing the lane to the left.
00   Middle of the vehicle does not depart the lane to the left side
01   Middle of the vehicle ...";
CM_ SG_ 2431649790 DriverAlertnessWarning "Indicates when a distracted driving condition is detected. This signal can be used independent of the technology and ECU used to estimate the distracted driver condition.
000 = No distracted driving condition detected
001 = Level 1 - Mild ...";
CM_ BO_ 2633929214 "Fuel Leakage";
CM_ SG_ 2633929214 EngFuelLeakage2 "Status signal which indicates fuel leakage in the fuel rail of the engine. Location can be either before or after the fuel pump.  

00 - no leakage detected
01 - leakage detected
10 - Error
11 - Not available";
CM_ SG_ 2633929214 EngFuelLeakage1 "Status signal which indicates fuel leakage in the fuel rail of the engine. Location can be either before or after the fuel pump.  

00 - no leakage detected
01 - leakage detected
10 - Error
11 - Not available";
CM_ BO_ 2566831614 "Fan Drive #1
This parameter group transfers status and measured information for an engine coolant fan.  This PGN is used for the primary fan if there are more than one fan in the syste.  PGN 64817 may be used for a second fan.";
CM_ SG_ 2566831614 FanDriveBypassCmdStatus "Status of the Fan Drive Bypass Command as being commanded by the ECU.  The fan drive bypass diverts pump pressure away from the hydraulic motor to maintain the fan drive pressure.  0% is defined as no bypass (i.e. diverting no fan drive pressure) ...";
CM_ SG_ 2566831614 HydFanMotorPress "The hydraulic pressure used to drive the fan system, sensed before the hydraulic fan motor.";
CM_ SG_ 2566831614 FanSpeed "The speed of the fan associated with engine coolant system.";
CM_ SG_ 2566831614 FanDriveState "This parameter is used to indicate the current state or mode of operation by the fan drive.
0000 Fan off
0001 Engine system-General
0010 Excessive engine air temperature
0011 Excessive engine oil temperature
0100 Excessive engine coolant ...";
CM_ SG_ 2566831614 EstPercentFanSpeed "Estimated fan speed as a ratio of the fan drive (current speed) to the fully engaged fan drive (maximum fan speed).  A two state fan (off/on) will use 0% and 100% respectively.  A three state fan (off/intermediate/on) will use 0%, 50% and 100% ...";
CM_ BO_ 2566820094 "Engine Torque History
NOTE - The torque history PGN is variable in length and may contain up to 125 torque history records.  Each torque history record MUST BE 38 bytes in length.  Any unused bytes must be 0xFF.
The last six bytes of each record ...";
CM_ SG_ 2566820094 EngTorqueLimit6AxleInput "Limit applied to the engine output torque based on the maximum allowable axle input torque.  Axle input torque is calculated as the current engine torque output multiplied by the transmission gear ratio.";
CM_ SG_ 2566820094 EngTorqueLimit5Switch "Limit applied to the engine output torque based on activation of an ECU switch input.";
CM_ SG_ 2566820094 EngTorqueLimit4Trans "Limit applied to the engine output torque during vehicle operation in transmission gear ratios numerically less than or equal to transmission gear ratio 3 (see SPN 1259).";
CM_ SG_ 2566820094 EngTorqueLimit3Trans "Limit applied to the engine output torque during vehicle operation in transmission gear ratios numerically less than or equal to transmission gear ratio 2 (see SPN 1257) and numerically greater than transmission gear ratio 3 (see.SPN 1259).  For ...";
CM_ SG_ 2566820094 TransGearRatio3 "Gear ratio value stored in the ECU that is used to define a range of transmission gears for which a limit is applied to the engine output torque.  Transmission gear ratio 3 should be the numerically highest transmission gear ratio breakpoint less ...";
CM_ SG_ 2566820094 EngTorqueLimit2Trans "Limit applied to the engine output torque during vehicle operation in transmission gear ratios numerically less than or equal to transmission gear ratio 1 (see SPN 1255) and numerically greater than transmission gear ratio 2 (see.SPN 1257).  For ...";
CM_ SG_ 2566820094 TransGearRatio2 "Gear ratio value stored in the ECU that is used to define a range of transmission gears for which a limit is applied to the engine output torque.  Transmission gear ratio 2 should be the numerically highest transmission gear ratio breakpoint less ...";
CM_ SG_ 2566820094 EngTorqueLimit1Trans "Limit applied to the engine output torque during vehicle operation in transmission gear ratios numerically greater than transmission gear ratio 1 (see SPN 1255).";
CM_ SG_ 2566820094 TransGearRatio1 "Gear ratio value stored in the ECU that is used to define a range of transmission gears for which a limit is applied to the engine output torque.  Transmission gear ratio 1 should be the numerically highest transmission gear ratio breakpoint that ...";
CM_ SG_ 2566820094 EngTorqueLimitFeature "Torque limit rating described in the current record.
000 Reserved
001 Highest torque rating
010 First torque rating
011 Previous torque rating (rating prior to the current rating)
100 Current torque rating
101-110 Reserved
111 Not available
 ...";
CM_ SG_ 2566820094 TorqueLimitingFeatureStatus "Status of an ECU feature which limits the torque output of the engine. 

00 - Disabled
01 - Enabled
10 - Error
11 - Not available";
CM_ SG_ 2566820094 CalibRecordDurationTime "Duration in hours for which the engine operated in the conditions captured in the current record.";
CM_ SG_ 2566820094 CalibRecordStartYear "Calendar year timestamp when an ECU record was established.

NOTE - A value of 0 for the year identifies the year 1985; a value of 1 identifies 1986; etc.";
CM_ SG_ 2566820094 CalibRecordStartDay "Calendar day timestamp when an ECU record was established.

NOTE - A value of 0 for the date is null.  The values 1, 2, 3, and 4 are used to identify the first day of the month; 5, 6, 7, and 8 identify the second day of the month; etc.";
CM_ SG_ 2566820094 CalibRecordStartMonth "Calendar month timestamp when an ECU record was established.

NOTE - A value of 0 for the month is null.  The value 1 identifies January; 2 identifies February; etc.";
CM_ SG_ 2566820094 EngPeakTorque2 "Maximum torque output of the current ECU calibration when the engine operates on torque curve 2.  For calibrations that support two torque curves, this parameter shall be assigned the value of the higher curve.  For calibrations that support only ...";
CM_ SG_ 2566820094 EngPeakTorque1 "Maximum torque output of the current ECU calibration when the engine operates on torque curve 1.  For calibrations that support two torque curves, this parameter shall be assigned the value of the lower curve.  For calibrations that support only one ...";
CM_ SG_ 2566820094 EngPower "Advertised engine power capability.  Advertised power is what a customer will find on a sales sheet for an engine with a certain calibration.";
CM_ SG_ 2566820094 NumberOfEngTorqueHistoryRecords "Number of torque history records contained in the engine torque history PGN.  A value of 0 is broadcast if no torque history records are stored in the ECU.";
CM_ BO_ 2364542206 "Electronic Transmission Controller #8
Electronic Transmission Controller #8";
CM_ SG_ 2364542206 TransClutch_ConverterInputSpeed "Rotational velocity of the input to a transmission's master clutch or torque converter. In most cases the rotational velocity will be the same as engine flywheel speed unless there is an intermediate device, such as a power divider, between the ...";
CM_ SG_ 2364542206 TransTorqueConverterRatio "Ratio of the transmissions torque converter output torque to torque converter input torque at current speed.
The ratio of 1.000 ( 03 E8 hex ) indicates torque converter lockup.
If the ratio is less than 1 and the ratio can not be properly ...";
CM_ BO_ 2566802174 "Electronic Transmission Controller 7
Transmission status information from the transmission controller to network.";
CM_ SG_ 2566802174 TransAutoNeutralSt "Indicates the transmission response to a Neutral request from SPN 7695 [Transmission Auto-Neutral (Manual Return) Request] or other vehicle input configured for Auto-Neutral (Manual Return) functionality. The applicability of the states and state ...";
CM_ SG_ 2566802174 TransWarningIndicator "Signal from transmission indicating that some aspect of its operation is not functioning correctly, and as a result, transmission operation may be altered or restricted.  The indicator is typically a lamp.  Distinctions in meaning between the ...";
CM_ SG_ 2566802174 TrnsRverseGearShiftInhibitStatus "Reflects the status of transmission reverse inhibit activity in response to requests via SPN 4242 - Transmission Reverse Gear Shift Inhibit Request.  Typically broadcast by the transmission controller.
00 = Reverse gear shifts are currently allowed
 ...";
CM_ SG_ 2566802174 TransMode8Indicator "This state signal is the transmission's indication that it is operating under transmission mode 8 (SPN 4249) as commanded via the TC1 message (PGN 256).  The definition of the transmission mode is left to the discretion of the transmission ...";
CM_ SG_ 2566802174 TransMode7Indicator "This state signal is the transmission's indication that it is operating under transmission mode 7 (SPN 4248) as commanded via the TC1 message (PGN 256).  The definition of the transmission mode is left to the discretion of the transmission ...";
CM_ SG_ 2566802174 TransMode6Indicator "This state signal is the transmission's indication that it is operating under transmission mode 6 (SPN 4247) as commanded via the TC1 message (PGN 256).  The definition of the transmission mode is left to the discretion of the transmission ...";
CM_ SG_ 2566802174 TransMode5Indicator "This state signal is the transmission's indication that it is operating under transmission mode 5 (SPN 4246) as commanded via the TC1 message (PGN 256).  The definition of the transmission mode is left to the discretion of the transmission ...";
CM_ SG_ 2566802174 TransRequestedGearFeedback "Feedback of the SPN 525 Transmission Requested Gear input as received from the shift selector, ABS or engine via PGN 256, Transmission Control 1 (TC1) or other transmission selector input.  Scaling, values and parameter specific indicators are ...";
CM_ SG_ 2566802174 TransMode1Indicator "This state signal is the transmission's indication that it is operating under transmission mode 1 (SPN 1852) as commanded via the TC1 message (PGN 256).  The definition of the transmission mode is left to the discretion of the transmission ...";
CM_ SG_ 2566802174 TransMode2Indicator "This state signal is the transmission's indication that it is operating under transmission mode 2 (SPN 1853) as commanded via the TC1 message (PGN 256).  The definition of the transmission mode is left to the discretion of the transmission ...";
CM_ SG_ 2566802174 TransMode3Indicator "This state signal is the transmission's indication that it is operating under transmission mode 3 (SPN 1854) as commanded via the TC1 message (PGN 256).  The definition of the transmission mode is left to the discretion of the transmission ...";
CM_ SG_ 2566802174 TransMode4Indicator "This state signal is the transmission's indication that it is operating under transmission mode 4 (SPN 1855) as commanded via the TC1 message (PGN 256).  The definition of the transmission mode is left to the discretion of the transmission ...";
CM_ SG_ 2566802174 TransShiftInhibitIndicator "State signal indicating a transmission request for the Shift Inhibit Indicator to be active or inactive. The shift inhibit indicator can be of lamp or text form, located on (but not limited to) the shift console, instrument cluster, or cab display ...";
CM_ SG_ 2566802174 TransEngCrankEnable "State signal from the transmission indicating if the transmission's status is such that engine cranking is allowed (i.e.  at a minimum, transmission is in neutral and the driveline is disengaged).  As sender of this information, the transmission is ...";
CM_ SG_ 2566802174 ActiveShiftConsoleIndicator "Signal from transmission control unit indicating which shift console (primary or secondary) it currently considers as the active shift selector input.
00        Primary shift console is active
01        Secondary shift console is active
10 ...";
CM_ SG_ 2566802174 TransReadyForBrakeRelease "This parameter indicates that enough torque / motive force is available at the transmission output shaft to release all the brakes without a risk of unintentional movement in the opposite direction.
00 - Transmission Not Ready for Brake Release
01 ...";
CM_ SG_ 2566802174 TrnsRqstedRangeDisplayFlashState "State signal indicating a transmission request for the display of the Transmission Requested Range parameter (SPN 162) to flash or not to flash. The ‘Transmission Requested Range Display Flash State' indicator can be utilized by (but not limited to) ...";
CM_ SG_ 2566802174 TrnsRqstedRangeDisplayBlankState "State signal indicating a transmission request for the display of the Transmission Requested Range parameter (SPN162) to be blanked or not blanked.  The ‘Transmission Requested Range Display Blank State' indicator can be utilized by (but not limited ...";
CM_ SG_ 2566802174 TransServiceIndicator "Signal from transmission indicating that some aspect of the gearbox requires servicing, such as the oil, filter, clutch(es) or other component.
00  Transmission Service Indicator is off
01  Transmission Service Indicator is on continuously
10 ...";
CM_ SG_ 2566802174 TransAirSupplyPressIndicator "Indicates whether transmission air supply is sufficient
000   Normal Pressure Range - The transmission supply air pressure is within the normal operational range.
001   Low pressure - The transmission supply air pressure is within a range that may ...";
CM_ SG_ 2566802174 TransMode10Indicator "Indicates that the transmission is operating under transmission mode 10 (SPN 6570) as commanded via the TC2 message (PGN 3328). The definition of the transmission mode is left to the discretion of the transmission manufacturer.
00 Transmission Mode ...";
CM_ SG_ 2566802174 TransMode9Indicator "Indicates that the transmission is operating under transmission mode 9 (SPN 6569) as commanded via the TC2 message (PGN 3328). The definition of the transmission mode is left to the discretion of the transmission manufacturer.
00 Transmission Mode ...";
CM_ SG_ 2566802174 TrnsCrrentRangeDisplayBlankState "State signal indicating a transmission request for the display of the Transmission Current Range parameter (SPN 163) to be blanked or not blanked.  The 'Transmission Current Range Display Blank State' indicator can be utilized by (but not limited ...";
CM_ BO_ 2633935870 "Electronic Transmission Controller 6";
CM_ SG_ 2633935870 ClutchLifeRemaining "Signal which indicates the actual clutch life remaining in percent. One hundred percent means the clutch is brand new and zero percent means the clutch is at the end of its life.";
CM_ SG_ 2633935870 LowestPossibleGear "The transmission calculates this gear continuously.  Together with the highest possible gear (see SPN 1115), it enables a management computer to know the exact range of available gears.";
CM_ SG_ 2633935870 HighestPossibleGear "The transmission calculates this gear continuously.  Together with the lowest possible gear (see  SPN 1114), it enables a management computer to know the exact range of available gears.";
CM_ SG_ 2633935870 RecommendedGear "The transmission calculates this gear continuously.  In dangerous situations this gear may be selected to gain back vehicle control.";
CM_ BO_ 2633942014 "Electronic Transmission Controller 5";
CM_ SG_ 2633942014 TransForwardDirectionSwitch "Identifies the status of the switch that indicates forward direction.

00 - Off
01 - On
10 - Error
11 - Not available";
CM_ SG_ 2633942014 TransNeutralSwitch "Identifies the status of the switch that indicates neutral.

00 - Off
01 - On
10 - Error
11 - Not available";
CM_ SG_ 2633942014 TransReverseDirectionSwitch "Identifies the status of the switch that indicates reverse direction.

00 - Off
01 - On
10 - Error
11 - Not available";
CM_ SG_ 2633942014 TransLowRangeSenseSwitch "Identifies the status of the switch that represents low range.

00 - Off
01 - On
10 - Error
11 - Not available";
CM_ SG_ 2633942014 TransHighRangeSenseSwitch "Identifies the status of the switch that represents high range.

00 - Off
01 - On
10 - Error
11 - Not available";
CM_ BO_ 2633942526 "Electronic Transmission Controller 4";
CM_ SG_ 2633942526 TransSynchronizerBrakeValue "The current modulated value for the air supply to the synchronizer brake.";
CM_ SG_ 2633942526 TransSynchronizerClutchValue "The current modulated value for the air supply to the synchronizer clutch.";
CM_ BO_ 2633943038 "Electronic Transmission Controller 3";
CM_ SG_ 2633943038 TransInertiaBrakeActuator "Identifies the status of the actuator that controls the inertia brake.

00 - Off
01 - On
10 - Error
11 - Not available";
CM_ SG_ 2633943038 TransDefuelActuator "Identifies the status of the actuator that controls the engine defuel mechanism.

00 - Off
01 - On
10 - Error
11 - Not available";
CM_ SG_ 2633943038 TransLockupClutchActuator "Identifies the status of the actuator that controls the torque converter lockup clutch.

00 - Off
01 - On
10 - Error
11 - Not available";
CM_ SG_ 2633943038 TransClutchActuator "Identifies the status of the actuator that controls the clutch.

00 - Off
01 - On
10 - Error
11 - Not available";
CM_ SG_ 2633943038 TransSplitterIndirectActuator "Identifies the status of the splitter indirect actuator in the auxiliary unit.

00 - Off
01 - On
10 - Error
11 - Not available";
CM_ SG_ 2633943038 TransSplitterDirectActuator "Identifies the status of the splitter direct actuator in the auxiliary unit.

00 - Off
01 - On
10 - Error
11 - Not available";
CM_ SG_ 2633943038 TransRangeLowActuator "Identifies the status of the range low actuator in the auxiliary unit.

00 - Off
01 - On
10 - Error
11 - Not available";
CM_ SG_ 2633943038 TransRangeHighActuator "Identifies the status of the range high actuator in the auxiliary unit.

00 -Off
01 -On
10 - Error
11 - Not available";
CM_ SG_ 2633943038 TransShiftFingerGearActuator2 "Identifies the status of the actuator that moves the shift finger identified as gear actuator #2.

00 - Off
01 - On
10 - Error
11 - Not available";
CM_ SG_ 2633943038 TransShiftFingerRailActuator2 "Identifies the status of the actuator that moves the shift finger identified as rail actuator #2.

00 - Off
01 - On
10 - Error
11 - Not available";
CM_ SG_ 2633943038 TransShiftFingerGearActuator1 "Identifies the status of the actuator that moves the shift finger identified as gear actuator #1.

00 - Off
01 - On
10 - Error
11 - Not available";
CM_ SG_ 2633943038 TransShiftFingerRailActuator1 "Identifies the status of the actuator that moves the shift finger identified as rail actuator #1.

00 - Off
01 - On
10 - Error
11 - Not available";
CM_ SG_ 2633943038 TrnsShftFngerCenterRailIndicator "Identifies the status of the shift finger in the center rail position.

00 - Off
01 - On
10 - Error
11 - Not available";
CM_ SG_ 2633943038 TrnsShftFngerEngagementIndicator "Identifies the status of the shift finger in the engagement position.

00 - Off
01 - On
10 - Error
11 - Not available";
CM_ SG_ 2633943038 TransShiftFingerNeutralIndicator "Indicates the status of the shift finger in the neutral position.

00 - Off
01 - On
10 - Error
11 - Not available";
CM_ SG_ 2633943038 TransShiftFingerRailPos "The current position of the shift finger in the rail direction.";
CM_ SG_ 2633943038 TransShiftFingerGearPos "The current position of the shift finger in the gear direction.";
CM_ BO_ 2565867006 "Electronic Transmission Controller 2";
CM_ SG_ 2565867006 TransCurrentRange "Range currently being commanded by the transmission control system. Characters may include P, Rx, Rx-1...R2, R1, R, Nx, Nx-1...N2, N1, N, D, D1, D2..., Dx, L, L1, L2..., Lx-1, 1, 2, 3,... If only one displayed character is required, the second ...";
CM_ SG_ 2565867006 TransRequestedRange "Range selected by the operator.  Characters may include P, Rx, Rx-1...R2, R1, R, Nx, Nx-1...N2, N1, N, D, D1, D2..., Dx, L, L1, L2..., Lx-1, 1, 2, 3,...  If only one displayed character is required, the second character shall be used and the first ...";
CM_ SG_ 2565867006 TransCurrentGear "The gear currently engaged in the transmission or the last gear engaged while the transmission is in the process of shifting to the new or selected gear.  Transitions toward a destination gear will not be indicated.  Once the selected gear has been ...";
CM_ SG_ 2565867006 TransActualGearRatio "Actual ratio of input shaft speed to output shaft speed.";
CM_ SG_ 2565867006 TransSelectedGear "The gear that the transmission will attempt to achieve during the current shift if a shift is in progress, or the next shift if one is pending (i.e., waiting for torque reduction to initiate the shift).";
CM_ BO_ 2364539646 "Electronic Transmission Controller 1
Electronic Transmission Controller #1
Note:
Single input shaft transmissions should use SPN 161 (Transmission Input Shaft Speed).
Multiple input shaft transmissions should use SPN 5960 and 5961 (DCT Input ...";
CM_ SG_ 2364539646 SrcAddrssOfCntrllngDvcFrTrnsCtrl "The source address of the SAE J1939 device currently controlling the transmission. Its value may be the source address of the ECU transmitting the message (which means that no external SAE J1939 message is providing the active command) or the source ...";
CM_ SG_ 2364539646 TransInputShaftSpeed "Rotational velocity of the primary shaft transferring power into the transmission.  When a torque converter is present, it is the output of the torque converter.
Note:
Single input shaft transmissions should use SPN 161 (Transmission Input Shaft ...";
CM_ SG_ 2364539646 MomentaryEngMaxPowerEnable "Momentarily Requesting highest torque map from the engine control

00 not requesting maximum power available
01 momentarily requesting maximum power available
10 fault
11 not available";
CM_ SG_ 2364539646 ProgressiveShiftDisable "Command signal used to indicate that progressive shifting by the engine should be disallowed.

00 Progressive shift is not disabled
01 Progressive shift is disabled
10 Reserved
11 Take no action";
CM_ SG_ 2364539646 EngMomentaryOverspeedEnable "Command signal used to indicate that the engine speed may be boosted up to the maximum engine overspeed value to accommodate transmission downshifts.  The maximum time for overspeed is limited by the time defined in the engine configuration message ...";
CM_ SG_ 2364539646 PercentClutchSlip "Parameter which represents the ratio of input shaft speed to current engine speed (in percent).

Percent Clutch Slip = ((Engine rpm - Input shaft rpm)/(Engine rpm)) x 100";
CM_ SG_ 2364539646 TransOutputShaftSpeed "Calculated speed of the transmission output shaft.";
CM_ SG_ 2364539646 TrnsTrqCnvrtrLckpTrnstnInProcess "State signal indicating whether or not the transmission torque converter lock up clutch is transitioning between being applied and being released.  The broadcast value should be set to 01 as soon as an apply or release of the lockup clutch is ...";
CM_ SG_ 2364539646 TransShiftInProcess "Indicates that the transmission is in process of shifting from the current gear to the selected gear. This state is generally ACTIVE during the entire time that the transmission controls the vehicle during a shift. This includes any transmission ...";
CM_ SG_ 2364539646 TrnsTorqueConverterLockupEngaged "State signal which indicates whether the torque converter lockup is engaged.

00 Torque converter lockup disengaged
01 Torque converter lockup engaged
10 Error
11 Not available";
CM_ SG_ 2364539646 TransDrivelineEngaged "Driveline engaged indicates the transmission controlled portion of the driveline is engaged sufficiently to allow a transfer of torque through the transmission.  Driveline engaged is ACTIVE whenever the transmission is in gear and the clutch (if ...";
CM_ BO_ 2566810110 "Engine Temperature 3
This parameter group is used to transmit high resolution engine temperatures for control purposes.";
CM_ SG_ 2566810110 EngChargeAirCooler1OutletTemp "Temperature of combustion air after it exits from the Charge Air Cooler 1 but before any mixing of recirculated exhaust gas.";
CM_ SG_ 2566810110 EngIntkVlvActuationSystemOilTemp "The temperature of the oil in the hydraulic system that powers the intake valve actuation system.";
CM_ SG_ 2566810110 EngCoolantTemp "Temperature of liquid found in engine cooling system. The higher resolution is required for control purposes.";
CM_ SG_ 2566810110 EngIntakeManifold1AirTemp "Temperature of pre-combustion air found in intake manifold of engine air supply system. The higher resolution is required for control purposes.";
CM_ BO_ 2566825214 "Engine Temperature 2";
CM_ SG_ 2566825214 EngExhaustGasRecirculation1Temp "Temperature of Recirculated Exhaust Gas.  This should not be used for Exhaust Gas Recirculation Mixer Intake Temperature.  See SPN 5020.";
CM_ SG_ 2566825214 EngExhstGsRcirculation1DiffPress "Differential pressure across the Exhaust Gas Recirculation (EGR) system";
CM_ SG_ 2566825214 EngECUTemp "Temperature of the engine electronic control unit.";
CM_ SG_ 2566825214 EngOilTemp2 "Temperature of the engine lubricant.

Note:  If there is only one engine oil temperature measurement, SPN 175 should be used. 

See also SPNs 175 and 5925 for additional engine oil temperature measurements.";
CM_ BO_ 2566844158 "Engine Temperature 1";
CM_ SG_ 2566844158 EngIntercoolerThermostatOpening "The current position of the thermostat used to regulate the temperature of the engine charge air cooler.  A value of 0% represents the thermostat being completely closed and 100% represents the thermostat being completely open.";
CM_ SG_ 2566844158 EngIntercoolerTemp "Temperature of liquid found in the intercooler located after the turbocharger.";
CM_ SG_ 2566844158 EngTurboOilTemp "Temperature of the turbocharger lubricant.";
CM_ SG_ 2566844158 EngOilTemp1 "Temperature of the engine lubricant.
Note:  If there is only one engine oil temperature measurement, this SPN should be used.  This is the SPN that is typically displayed on an on-highway truck instrument cluster.
See also SPNs 1135 and 5925 for ...";
CM_ SG_ 2566844158 EngFuelTemp1 "Temperature of fuel (or gas) of the first fuel type. See SPN 3468 for a second temperature measurement of the first fuel type.";
CM_ SG_ 2566844158 EngCoolantTemp "Temperature of liquid found in engine cooling system.";
CM_ BO_ 2566785022 "Exhaust Temperature";
CM_ SG_ 2566785022 EngExhaustManifoldBank1Temp2 "Temperature of combustion byproducts measured by a second sensor in engine bank 1 (left bank) exhaust manifold. This should be used for the sensor toward the rear of the engine on the bank 1 manifold.";
CM_ SG_ 2566785022 EngExhaustManifoldBank2Temp2 "Temperature of combustion byproducts measured by a second sensor in engine bank 2 (right bank) exhaust manifold. This should be used for the sensor toward the rear of the engine on the bank 2 manifold.";
CM_ SG_ 2566785022 EngExhaustGasTempLeftManifold "Temperature of combustion byproducts measured in engine bank 1 (left bank) exhaust manifold.  Single manifold engines should use exhaust temperature (SPN 173).";
CM_ SG_ 2566785022 EngExhaustGasTempRightManifold "Temperature of combustion byproducts measured in engine bank 2 (right bank) exhaust manifold.  Single manifold engines should use exhaust temperature (SPN 173).";
CM_ BO_ 2565868542 "Electronic Steering Control
PGN which indicates the actual angle and the status of a steerable axle";
CM_ SG_ 2565868542 TypeOfSteerTrans "Type of Steering Transmission (Ref. ECE Regulation 79 paragraph 2.6)
0000             Purely mechanical steering transmission
0001             Purely hydraulic steering transmission
0010             Purely electric steering transmission
0011 ...";
CM_ SG_ 2565868542 TypeOfSteerForces "Type of Steering Forces (Ref. ECE Regulation 79 paragraph 2.5)
0000             Manual steering equipment
0001             Power assisted steering equipment
0010             Full power steering equipment
0011             Self tracking steering ...";
CM_ SG_ 2565868542 SteerType "Indicates the different types of steering systems (ref. ECE Regulation 79 paragraph 2.5)
0000             Main steering system
0001             Auxiliary steering equipment
0010-1110   Reserved for Assignment by SAE
1111             Not ...";
CM_ SG_ 2565868542 SteerableLiftAxleLoweringInhibit "A signal which indicates if lowering of lifted axle is allowed or inhibited.

00      Lowering allowed
01      Lowering inhibited
10      Reserved
11      Not available";
CM_ SG_ 2565868542 StatusOfSteerAxle "A signal which indicates different states of the steering axle
0000               Axle steering not active (adhesion steering)
0001               Axle steering active
0010               Axle centered
0011               Axle centered, because of ...";
CM_ SG_ 2565868542 AxleLocation "To identify to which of several similar devices (such as tires or fuel tanks) the information applies.
The low order 4 bits represent a position number, counting left to right when facing in the direction of normal vehicle travel (forward).
The ...";
CM_ SG_ 2565868542 ActualInnerWheelSteerAngle "Signal which indicates the actual inner wheel steering angle.  The steering angle is the angle of wheel turn relative to the vehicle x-axis (yaw angle of inner wheel). See Figure SPN2927_A for explanation of positive and negative angles.  This ...";
CM_ BO_ 2633941758 "Electronic Retarder Controller 2
This message will be transmitted by several types of retarding devices such as engine compression release brakes, exhaust system restriction brakes, and driveline retarders using hydraulic, electric, or mechanical ...";
CM_ SG_ 2633941758 CrsCtrlRetarderActiveSpeedOffset "The additional speed above the operator selected cruise control set speed at which the retarder will activate when cruise control is active.";
CM_ SG_ 2633941758 TransOutputRetarder "Identifies the status of the transmission output retarder.

00 - Off
01 - On
10 - Error
11 - Not available";
CM_ BO_ 2565865726 "Electronic Retarder Controller 1
NOTE- This message will be transmitted by several types of retarding devices such as engine compression release brakes, exhaust system restriction brakes, and driveline retarders using hydraulic, electric, or ...";
CM_ SG_ 2565865726 ActlMxAvlblRetarderPercentTorque "This is the maximum amount of torque that the retarder can immediately deliver.   It is the same as the maximum torque shown in the Retarder's Configuration message, but allows for a much faster rate of change than could be communicated by reissuing ...";
CM_ SG_ 2565865726 RetarderSelectionNonengine "The 'Retarder Selection, non-engine' is the position of the driver's selector for retarders that are not part of the engine system, expressed as percent and determined by the ratio of current position to the maximum possible position. The physical ...";
CM_ SG_ 2565865726 DrvrsDemandRetarderPercentTorque "The Drivers demand retarder - percent torque is the maximum torque selected by the driver when one or more modes  are selected by the driver, such as hand lever, switch, constant torque, constant velocity, etc.";
CM_ SG_ 2565865726 SrcAddrssOfCntrllngDvcFrRtrdrCtr "The source address of the SAE J1939 device currently controlling the retarder.  It is used to expand the torque mode parameter (see SPN 899) in cases where control is in response to an ECU that is not listed in Table SPN899_A.  Its value may be the ...";
CM_ SG_ 2565865726 RetarderRoadSpeedExceeded "Retarder Road Speed Exceeded Status:

00   Road speed is below threshold 
01   Road speed is above threshold and retarder is allowed to be activated
10   Reserved
11   Don't care/Take no action";
CM_ SG_ 2565865726 RetarderRoadSpeedLimitSwitch "Retarder road speed limit switch states:
00   Road speed limiting by retarder is disabled
01   Road speed limiting by retarder is enabled.  The road speed that the retarder will limit will be determined when the switch transitions from 00 to 01
 ...";
CM_ SG_ 2565865726 RetarderRequestingBrakeLight "Indicates that whether the retarder is requesting that the brake lights are illuminated.
00 - Retarder is not requesting that the brake lights are illuminated
01 - Retarder is requesting that the brake lights are illuminated
10 - Reserved
11 - ...";
CM_ SG_ 2565865726 EngCoolantLoadIncrease "Status of an event, external to the engine, that may increase the nominal temperature of the engine coolant liquid.

00 - No coolant load increase
01 - Coolant load increase possible
10 - Error
11 - Not available";
CM_ SG_ 2565865726 IntendedRetarderPercentTorque "Braking torque of retarder that the retarder is currently trying to achieve.  This value takes into account all static limitations, but not the limitations due to the dynamic behavior of the retarder.  This value, if unchanged over a certain time, ...";
CM_ SG_ 2565865726 ActualRetarderPercentTorque "Actual braking torque of the retarder as a percent of retarder configuration reference torque SPN 556.

Note:  Refer to section 5.2.1 in SAE J1939-71.";
CM_ SG_ 2565865726 RetarderEnableShiftAssistSwitch "Switch signal which indicates whether the operator wishes the retarder to be enabled for transmission shift assist.  The retarder does not check this switch, nor does the enabling of this switch engage the retarder.  When this switch is 'enabled,' ...";
CM_ SG_ 2565865726 RetarderEnableBrakeAssistSwitch "Switch signal which indicates whether the operator wishes the retarder to be enabled for vehicle braking assist. The retarder does not check this switch, nor does the enabling of this switch engage the retarder. When this switch is 'enabled,' the ...";
CM_ SG_ 2565865726 RetarderTorqueMode "State signal which indicates which retarder torque mode is currently generating, limiting, or controlling the torque.  Note that the modes are not in prioritized order. Not all modes may be relevant for a given device.  Some devices may not ...";
CM_ BO_ 2633932798 "Exhaust Port Temperature 5";
CM_ SG_ 2633932798 EngExhaustGasPort20Temp "Temperature at the cylinder exhaust port of the engine.";
CM_ SG_ 2633932798 EngExhaustGasPort19Temp "Temperature at the cylinder exhaust port of the engine.";
CM_ SG_ 2633932798 EngExhaustGasPort18Temp "Temperature at the cylinder exhaust port of the engine.";
CM_ SG_ 2633932798 EngExhaustGasPort17Temp "Temperature at the cylinder exhaust port of the engine.";
CM_ BO_ 2566824190 "Exhaust Port Temperature 4";
CM_ SG_ 2566824190 EngExhaustGasPort16Temp "Temperature at the cylinder exhaust port of the engine.";
CM_ SG_ 2566824190 EngExhaustGasPort15Temp "Temperature at the cylinder exhaust port of the engine.";
CM_ SG_ 2566824190 EngExhaustGasPort14Temp "Temperature at the cylinder exhaust port of the engine.";
CM_ SG_ 2566824190 EngExhaustGasPort13Temp "Temperature at the cylinder exhaust port of the engine.";
CM_ BO_ 2633933310 "Exhaust Port Temperature 3";
CM_ SG_ 2633933310 EngExhaustGasPort12Temp "Temperature at the cylinder exhaust port of the engine.";
CM_ SG_ 2633933310 EngExhaustGasPort11Temp "Temperature at the cylinder exhaust port of the engine.";
CM_ SG_ 2633933310 EngExhaustGasPort10Temp "Temperature at the cylinder exhaust port of the engine.";
CM_ SG_ 2633933310 EngExhaustGasPort9Temp "Temperature at the cylinder exhaust port of the engine.";
CM_ BO_ 2633933566 "Exhaust Port Temperature 2";
CM_ SG_ 2633933566 EngExhaustGasPort8Temp "Temperature at the cylinder exhaust port of the engine.";
CM_ SG_ 2633933566 EngExhaustGasPort7Temp "Temperature at the cylinder exhaust port of the engine.";
CM_ SG_ 2633933566 EngExhaustGasPort6Temp "Temperature at the cylinder exhaust port of the engine.";
CM_ SG_ 2633933566 EngExhaustGasPort5Temp "Temperature at the cylinder exhaust port of the engine.";
CM_ BO_ 2633933822 "Exhaust Port Temperature 1";
CM_ SG_ 2633933822 EngExhaustGasPort4Temp "Temperature at the cylinder exhaust port of the engine.";
CM_ SG_ 2633933822 EngExhaustGasPort3Temp "Temperature at the cylinder exhaust port of the engine.";
CM_ SG_ 2633933822 EngExhaustGasPort2Temp "Temperature at the cylinder exhaust port of the engine.";
CM_ SG_ 2633933822 EngExhaustGasPort1Temp "Temperature at the cylinder exhaust port of the engine.";
CM_ BO_ 2566776062 "Equipment Performance Data
Parameters related to the performance characteristics of equipment";
CM_ SG_ 2566776062 PayloadCapacityPercentage "The current equipment payload plus the weight of any after-factory modifications reported as a percentage of the equipment's maximum payload capacity. The equipment's maximum payload capacity is the maximum capacity of the equipment before the added ...";
CM_ SG_ 2566776062 PayloadCarryBackWeight "The payload weight left on the machine after the last payload dump event.";
CM_ SG_ 2566776062 PayloadWeightConfidence "The level of confidence of the real time payload weight measurement (SPN 6851). Higher confidence values indicate greater probability the real time payload weight is the actual weight and providing feedback on the potential for improving system ...";
CM_ SG_ 2566776062 PayloadWeight "The current payload weight carried by the machine.";
CM_ SG_ 2566776062 PayloadPercentage "The current payload of the equipment, reported as a percentage of the equipment's rated payload limit.";
CM_ BO_ 2566771454 "ECU Performance
Message used to transfer ECU performance parameters.";
CM_ SG_ 2566771454 DataMemoryUsage "The used storage capacity of the data buffer memory internal to an ECU, such as a data logger.";
CM_ SG_ 2566771454 KeepAliveBatteryConsumption "The capacity consumed from the direct battery connection since the key was last turned off.  This value is maintained and does not accumulate while the key switch is on.  The value is reset to 0 when the key switch is turned to the off position.";
CM_ BO_ 2566775806 "Equipment Operation and Control
Parameters related to the operation and controls for equipment";
CM_ SG_ 2566775806 TravelVelocityCtrlPos "The position of the travel velocity control component reported as a percentage of the control's full displacement in each direction respectively.  Positive position values indicate forward travel direction;  negative position values indicate ...";
CM_ BO_ 2633935358 "Exhaust Oxygen 1";
CM_ SG_ 2633935358 EngExhstGsOxygnSnsrClsdLpOprtion "Indicates whether the engine is using the exhaust oxygen sensor to control the air/fuel ratio.
00 Engine not using the exhaust oxygen sensor (open loop)
01 Engine using the exhaust oxygen sensor for a closed loop operation
10 Reserved
11 Don't ...";
CM_ SG_ 2633935358 EngExhstGsOxygnSnsrFlngCrrection "The amount of fueling change required by the system based on the measured exhaust oxygen value compared to the maximum fueling change permitted by the system, expressed as percentages.";
CM_ SG_ 2633935358 EngActualExhaustOxygen "The actual amount of oxygen in the exhaust represented as a percentage by volume with respect to the total volume of exhaust gases leaving the engine.";
CM_ SG_ 2633935358 EngDesiredExhaustOxygen "The desired amount of oxygen in the exhaust represented as a percentage by volume with respect to the total volume of exhaust gases leaving the engine.";
CM_ SG_ 2633935358 EngDesiredRatedExhaustOxygen "The desired amount of oxygen in the exhaust at rated conditions represented as a percentage by volume with respect to the total volume of exhaust gases leaving the engine.";
CM_ BO_ 2365447166 "Extended Joystick Message 3
Used to transfer information about the measured status of three additional axes of a joystick and switches of the joystick grip or handle.  The joystick axial motion information is available in the Basic Joystick ...";
CM_ SG_ 2365447166 Joystick3Button13PressedStatus "Reports when the joystick button has been pressed.

00 Button not pressed
01 Button pressed
10 Error Indicator
11 Not Available";
CM_ SG_ 2365447166 Joystick3Button14PressedStatus "Reports when the joystick button has been pressed.

00 Button not pressed
01 Button pressed
10 Error Indicator
11 Not Available";
CM_ SG_ 2365447166 Joystick3Button15PressedStatus "Reports when the joystick button has been pressed.

00 Button not pressed
01 Button pressed
10 Error Indicator
11 Not Available";
CM_ SG_ 2365447166 Joystick3Button16PressedStatus "Reports when the joystick button has been pressed.

00 Button not pressed
01 Button pressed
10 Error Indicator
11 Not Available";
CM_ SG_ 2365447166 Jystick3GripXAxisDetentPosStatus "Reports when the current joystick grip position is in the detent position for that axis of travel.

00 Not in the Detent Position
01 In the Detent Position
10 Error Indicator
11 Not Available";
CM_ SG_ 2365447166 Jystick3GripYAxisDetentPosStatus "Reports when the current joystick grip position is in the detent position for that axis of travel.

00 Not in the Detent Position
01 In the Detent Position
10 Error Indicator
11 Not Available";
CM_ SG_ 2365447166 Jystick3ThetaAxisDetentPosStatus "Reports when the current joystick position is in the detent position for that axis of travel.

00 Not in the Detent Position
01 In the Detent Position
10 Error Indicator
11 Not Available";
CM_ SG_ 2365447166 Joystick3ThetaAxisPos "The position of the joystick in the relative motion of travel from the neutral position.  Position value of 0 is Neutral and position value 1000 (100%) is the end of linear zone.  Value of 1022 indicates an error has occurred.";
CM_ SG_ 2365447166 Jystck3ThtAxsClckwsPstvPosStatus "Reports when the current joystick position is on the positive travel side (forward, right, clockwise, up) relative to the neutral position for that axis of travel.
00 Not on Positive side of Neutral
01 On positive side of Neutral
10 Error ...";
CM_ SG_ 2365447166 Jystck3ThetaAxisNeutralPosStatus "Reports when the current joystick position is in the neutral position for that axis of travel.  The neutral position measurement must be determined from some mechanism other than the axis position measurement device.
00 Not in Neutral Position
01 ...";
CM_ SG_ 2365447166 Joystick3GripYAxisPos "The position of the joystick grip in the relative motion of travel from the neutral position.  Position value of 0 is Neutral and position value 1000 (100%) is the end of linear zone.  Value of 1022 indicates an error has occurred.";
CM_ SG_ 2365447166 Jystck3GrpYAxsLvrFrwrdPstvPsStts "Reports when the current joystick grip position is on the positive travel side (forward, right, clockwise, up) relative to the neutral position for that axis of travel.
00 Not on Positive side of Neutral
01 On positive side of Neutral
10 Error ...";
CM_ SG_ 2365447166 Jystck3GrpYAxsLvrBckNgtvPsStatus "Reports when the current joystick grip position is on the negative travel side (back, left, counterclockwise, down) relative to the neutral position for that axis of travel.
00 Not on negative side of Neutral
01 On negative side of Neutral
10 ...";
CM_ SG_ 2365447166 Jystck3GripYAxisNeutralPosStatus "Reports when the current joystick grip position is in the neutral position for that axis of travel.  The neutral position measurement must be determined from some mechanism other than the axis position measurement device.
00 Not in Neutral Position
 ...";
CM_ SG_ 2365447166 Joystick3GripXAxisPos "The position of the joystick grip in the relative motion of travel from the neutral position.  Position value of 0 is Neutral and position value 1000 (100%) is the end of linear zone.  Value of 1022 indicates an error has occurred.";
CM_ SG_ 2365447166 Jystck3GrpXAxsLvrRghtPstvPsSttus "Reports when the current joystick grip position is on the positive travel side (forward, right, clockwise, up) relative to the neutral position for that axis of travel.
00 Not on Positive side of Neutral
01 On positive side of Neutral
10 Error ...";
CM_ SG_ 2365447166 Jystck3GrpXAxsLvrLftNgtvPsStatus "Reports when the current joystick grip position is on the negative travel side (back, left, counterclockwise, down) relative to the neutral position for that axis of travel.
00 Not on negative side of Neutral
01 On negative side of Neutral
10 ...";
CM_ SG_ 2365447166 Jystck3GripXAxisNeutralPosStatus "Reports when the current joystick grip position is in the neutral position for that axis of travel.  The neutral position measurement must be determined from some mechanism other than the axis position measurement device.
00 Not on negative side of ...";
CM_ SG_ 2365447166 Jystck3ThtAxsCntrClckwsNgtvPsStt "Reports when the current joystick position is on the negative travel side (back, left, counterclockwise, down) relative to the neutral position for that axis of travel.
00 Not on negative side of Neutral
01 On negative side of Neutral
10 Error ...";
CM_ BO_ 2365446654 "Extended Joystick Message 2
Used to transfer information about the measured status of three additional axes of a joystick and switches of the joystick grip or handle.  The joystick axial motion information is available in the Basic Joystick ...";
CM_ SG_ 2365446654 Joystick2Button13PressedStatus "Reports when the joystick button has been pressed.

00 Button not pressed
01 Button pressed
10 Error Indicator
11 Not Available";
CM_ SG_ 2365446654 Joystick2Button14PressedStatus "Reports when the joystick button has been pressed.

00 Button not pressed
01 Button pressed
10 Error Indicator
11 Not Available";
CM_ SG_ 2365446654 Joystick2Button15PressedStatus "Reports when the joystick button has been pressed.

00 Button not pressed
01 Button pressed
10 Error Indicator
11 Not Available";
CM_ SG_ 2365446654 Joystick2Button16PressedStatus "Reports when the joystick button has been pressed.

00 Button not pressed
01 Button pressed
10 Error Indicator
11 Not Available";
CM_ SG_ 2365446654 Jystick2GripXAxisDetentPosStatus "Reports when the current joystick grip position is in the detent position for that axis of travel.

00 Not in the Detent Position
01 In the Detent Position
10 Error Indicator
11 Not Available";
CM_ SG_ 2365446654 Jystick2GripYAxisDetentPosStatus "Reports when the current joystick grip position is in the detent position for that axis of travel.

00 Not in the Detent Position
01 In the Detent Position
10 Error Indicator
11 Not Available";
CM_ SG_ 2365446654 Jystick2ThetaAxisDetentPosStatus "Reports when the current joystick position is in the detent position for that axis of travel.

00 Not in the Detent Position
01 In the Detent Position
10 Error Indicator
11 Not Available";
CM_ SG_ 2365446654 Joystick2ThetaAxisPos "The position of the joystick in the relative motion of travel from the neutral position.  Position value of 0 is Neutral and position value 1000 (100%) is the end of linear zone.  Value of 1022 indicates an error has occurred.";
CM_ SG_ 2365446654 Jystck2ThtAxsClckwsPstvPosStatus "Reports when the current joystick position is on the positive travel side (forward, right, clockwise, up) relative to the neutral position for that axis of travel.
00 Not on Positive side of Neutral
01 On positive side of Neutral
10 Error ...";
CM_ SG_ 2365446654 Jystck2ThetaAxisNeutralPosStatus "Reports when the current joystick position is in the neutral position for that axis of travel.  The neutral position measurement must be determined from some mechanism other than the axis position measurement device.
00 Not in Neutral Position
01 ...";
CM_ SG_ 2365446654 Joystick2GripYAxisPos "The position of the joystick grip in the relative motion of travel from the neutral position.  Position value of 0 is Neutral and position value 1000 (100%) is the end of linear zone.  Value of 1022 indicates an error has occurred.";
CM_ SG_ 2365446654 Jystck2GrpYAxsLvrFrwrdPstvPsStts "Reports when the current joystick grip position is on the positive travel side (forward, right, clockwise, up) relative to the neutral position for that axis of travel.
00 Not on Positive side of Neutral
01 On positive side of Neutral
10 Error ...";
CM_ SG_ 2365446654 Jystck2GrpYAxsLvrBckNgtvPsStatus "Reports when the current joystick grip position is on the negative travel side (back, left, counterclockwise, down) relative to the neutral position for that axis of travel.
00 Not on negative side of Neutral
01 On negative side of Neutral
10 ...";
CM_ SG_ 2365446654 Jystck2GripYAxisNeutralPosStatus "Reports when the current joystick grip position is in the neutral position for that axis of travel.  The neutral position measurement must be determined from some mechanism other than the axis position measurement device.
00 Not in Neutral Position
 ...";
CM_ SG_ 2365446654 Joystick2GripXAxisPos "The position of the joystick grip in the relative motion of travel from the neutral position.  Position value of 0 is Neutral and position value 1000 (100%) is the end of linear zone.  Value of 1022 indicates an error has occurred.";
CM_ SG_ 2365446654 Jystck2GrpXAxsLvrRghtPstvPsSttus "Reports when the current joystick grip position is on the positive travel side (forward, right, clockwise, up) relative to the neutral position for that axis of travel.
00 Not on Positive side of Neutral
01 On positive side of Neutral
10 Error ...";
CM_ SG_ 2365446654 Jystck2GrpXAxsLvrLftNgtvPsStatus "Reports when the current joystick grip position is on the negative travel side (back, left, counterclockwise, down) relative to the neutral position for that axis of travel.
00 Not on negative side of Neutral
01 On negative side of Neutral
10 ...";
CM_ SG_ 2365446654 Jystck2GripXAxisNeutralPosStatus "Reports when the current joystick grip position is in the neutral position for that axis of travel.  The neutral position measurement must be determined from some mechanism other than the axis position measurement device.
00 Not on negative side of ...";
CM_ SG_ 2365446654 Jystck2ThtAxsCntrClckwsNgtvPsStt "Reports when the current joystick position is on the negative travel side (back, left, counterclockwise, down) relative to the neutral position for that axis of travel.
00 Not on negative side of Neutral
01 On negative side of Neutral
10 Error ...";
CM_ BO_ 2365446142 "Extended Joystick Message 1
Used to transfer information about the measured status of three additional axes of a joystick and switches of the joystick grip or handle.  The joystick axial motion information is available in the Basic Joystick ...";
CM_ SG_ 2365446142 Joystick1Button13PressedStatus "Reports when the joystick button has been pressed.

00 Button not pressed
01 Button pressed
10 Error Indicator
11 Not Available";
CM_ SG_ 2365446142 Joystick1Button14PressedStatus "Reports when the joystick button has been pressed.

00 Button not pressed
01 Button pressed
10 Error Indicator
11 Not Available";
CM_ SG_ 2365446142 Joystick1Button15PressedStatus "Reports when the joystick button has been pressed.

00 Button not pressed
01 Button pressed
10 Error Indicator
11 Not Available";
CM_ SG_ 2365446142 Joystick1Button16PressedStatus "Reports when the joystick button has been pressed.

00 Button not pressed
01 Button pressed
10 Error Indicator
11 Not Available";
CM_ SG_ 2365446142 Jystick1GripXAxisDetentPosStatus "Reports when the current joystick grip position is in the detent position for that axis of travel.

00 Not in the Detent Position
01 In the Detent Position
10 Error Indicator
11 Not Available";
CM_ SG_ 2365446142 Jystick1GripYAxisDetentPosStatus "Reports when the current joystick grip position is in the detent position for that axis of travel.

00 Not in the Detent Position
01 In the Detent Position
10 Error Indicator
11 Not Available";
CM_ SG_ 2365446142 Jystick1ThetaAxisDetentPosStatus "Reports when the current joystick position is in the detent position for that axis of travel.

00 Not in the Detent Position
01 In the Detent Position
10 Error Indicator
11 Not Available";
CM_ SG_ 2365446142 Joystick1ThetaAxisPos "The position of the joystick in the relative motion of travel from the neutral position.  Position value of 0 is Neutral and position value 1000 (100%) is the end of linear zone.  Value of 1022 indicates an error has occurred.";
CM_ SG_ 2365446142 Jystck1ThtAxsClckwsPstvPosStatus "Reports when the current joystick position is on the positive travel side (forward, right, clockwise, up) relative to the neutral position for that axis of travel.
00 Not on Positive side of Neutral
01 On positive side of Neutral
10 Error ...";
CM_ SG_ 2365446142 Jystck1ThetaAxisNeutralPosStatus "Reports when the current joystick position is in the neutral position for that axis of travel.  The neutral position measurement must be determined from some mechanism other than the axis position measurement device.
00 Not in Neutral Position
01 ...";
CM_ SG_ 2365446142 Joystick1GripYAxisPos "The position of the joystick grip in the relative motion of travel from the neutral position.  Position value of 0 is Neutral and position value 1000 (100%) is the end of linear zone.  Value of 1022 indicates an error has occurred.";
CM_ SG_ 2365446142 Jystck1GrpYAxsLvrFrwrdPstvPsStts "Reports when the current joystick grip position is on the positive travel side (forward, right, clockwise, up) relative to the neutral position for that axis of travel.
00 Not on Positive side of Neutral
01 On positive side of Neutral
10 Error ...";
CM_ SG_ 2365446142 Jystck1GrpYAxsLvrBckNgtvPsStatus "Reports when the current joystick grip position is on the negative travel side (back, left, counterclockwise, down) relative to the neutral position for that axis of travel.
00 Not on negative side of Neutral
01 On negative side of Neutral
10 ...";
CM_ SG_ 2365446142 Aftrtrtmnt1DslExhstFldPrprtsPrlm "Reports when the current joystick grip position is in the neutral position for that axis of travel.  The neutral position measurement must be determined from some mechanism other than the axis position measurement device.
00 Not in Neutral Position
 ...";
CM_ SG_ 2365446142 Joystick1GripXAxisPos "The position of the joystick grip in the relative motion of travel from the neutral position.  Position value of 0 is Neutral and position value 1000 (100%) is the end of linear zone.  Value of 1022 indicates an error has occurred.";
CM_ SG_ 2365446142 Jystck1GrpXAxsLvrRghtPstvPsSttus "Reports when the current joystick grip position is on the positive travel side (forward, right, clockwise, up) relative to the neutral position for that axis of travel.
00 Not on Positive side of Neutral
01 On positive side of Neutral
10 Error ...";
CM_ SG_ 2365446142 Jystck1GrpXAxsLvrLftNgtvPsStatus "Reports when the current joystick grip position is on the negative travel side (back, left, counterclockwise, down) relative to the neutral position for that axis of travel.
00 Not on negative side of Neutral
01 On negative side of Neutral
10 ...";
CM_ SG_ 2365446142 Jystck1GripXAxisNeutralPosStatus "Reports when the current joystick grip position is in the neutral position for that axis of travel.  The neutral position measurement must be determined from some mechanism other than the axis position measurement device.
00 Not in Neutral Position
 ...";
CM_ SG_ 2365446142 Jystck1ThtAxsCntrClckwsNgtvPsStt "Reports when the current joystick position is on the negative travel side (back, left, counterclockwise, down) relative to the neutral position for that axis of travel.
00 Not on negative side of Neutral
01 On negative side of Neutral
10 Error ...";
CM_ BO_ 2633929470 "Engine Information 1";
CM_ SG_ 2633929470 EngFuelRackPos "Measured position of the engine fuel rack.  A value of 0% rack represents no fueling and a value of 100% rack represents maximum fueling.";
CM_ SG_ 2633929470 EngGasMassFlowRate1 "Gas mass flow rate delivered to an engine through its first fuel control system.  See SPN 3467 for the second fuel control system.";
CM_ SG_ 2633929470 InstantaneousEstBrakePower "Estimate of the power developed by the engine.";
CM_ SG_ 2633929470 EngExhaustGasPress1 "Gage pressure of the exhaust gases as measured at the turbine intake of the turbocharger. This SPN to be used for inline engines or exhaust bank 1 of multiple bank engines.  See SPN 5749 for exhaust bank 2 and See SPN 6384 for alternate range and ...";
CM_ SG_ 2633929470 EngPrefilterOilPress "Gage pressure of the engine oil before the oil reaches the oil filter.   See SPN 7470 for alternate resolution.";
CM_ BO_ 2633937406 "ECU History";
CM_ SG_ 2633937406 TotalECURunTime "Total time accumulated over the life of the ECU, from ignition switch ON to ignition switch OFF.  When the ECU is replaced this value shall be reset.";
CM_ SG_ 2633937406 TotalECUDistance "Total distance accumulated over the life of the ECU.  When the ECU is replaced this value shall be reset.";
CM_ BO_ 2364541694 "Engine Gas Flow Rate
Flow rates of Air and mixed gasses into the engine cylinders.";
CM_ SG_ 2364541694 EngExhstGsRcrcltion2MassFlowRate "Flow rate of gas through the second EGR system. Flow rate of the exhaust gas being recirculated from the 2nd EGR system into combustion air.";
CM_ SG_ 2364541694 EngIntakeAirMassFlowRate "Mass flow rate of fresh air entering the engine air intake, before any EGR mixer, if used.  Flow rate of fresh air conducted to the engine cylinders to support combustion.";
CM_ SG_ 2364541694 EngExhstGsRcrcltion1MassFlowRate "Flow rate of gas through the EGR system. Flow rate of the exhaust gas being recirculated into the combustion air.";
CM_ BO_ 2566810366 "Engine Fuel/Lube Systems";
CM_ SG_ 2566810366 EngFuelSupplyPumpIntakePress "Gage pressure of fuel at the fuel supply pump intake.  See Figures SPN16_A & SPN16_B.

See also SPN 1381.";
CM_ SG_ 2566810366 FuelPumpPrimerStatus "Parameter used to transmit the actual status of the fuel priming system.  The fuel priming system is a system that purges air in the fuel lines and may assist fuel delivery to a second pump at lower speeds.
00 - Off
01 - On
10 - Error
11 - ...";
CM_ SG_ 2566810366 EngVentilationStatus "Engine ventilation control states.
000 = Sufficiently vented (all combustible gases have been evacuated from intake and exhaust systems)
001 = Ventilation needed (combustible gases may be present in intake and exhaust systems)
010 = Ventilation ...";
CM_ SG_ 2566810366 EngCoolantPreheatedState "Indicates whether the engine coolant is pre-heated sufficiently for starting purposes.
00 = Not sufficiently pre-heated
01 = Sufficiently pre-heated
10 = Unable to determine  engine coolant pre-heated sufficiently
11 = Not available or not ...";
CM_ SG_ 2566810366 EngOilPreHeatedState "Indicates whether the engine oil pre-heated sufficiently for starting purposes.

00 = Not sufficiently pre-heated
01 = Sufficiently pre-heated
10 = Unable to determine if engine oil is pre-heated sufficiently
11 = Not available or not installed";
CM_ SG_ 2566810366 EngOilPrimingState "Determination of whether or not the engine is (or has recently been) sufficiently lubricated for starting purposes.
00 = Not sufficiently lubricated
01 = Sufficiently lubricated
10 = Unable to determine if sufficiently lubricated
11 = Not ...";
CM_ SG_ 2566810366 EngOilPrimingPumpSwitch "Switch input for activating the engine oil priming pump.

00 = Off
01 = On
10 = Error
11 = Not available or not installed";
CM_ SG_ 2566810366 EngOilFilterOutletPress "Oil pressure (gage) measured just downstream of oil filter.Used in conjunction with SPN1208 (pre-filter oil pressure) to determine oil filter health.";
CM_ SG_ 2566810366 EngWasteOilReservoirLevel "Level of crankcase blowby emulsion collected by a container.  Normalized to percent, 0% represents completely empty and 100% represents completely full.";
CM_ SG_ 2566810366 EngFuelFilterDiffPress "Differential pressure measured across the fuel filter located between the fuel tank and the supply pump.  See Figures SPN16_A and SPN16_B.";
CM_ SG_ 2566810366 EngFuelSupplyPumpIntakeAbsPress "Absolute pressure of fuel at the fuel supply pump intake.  See Figures SPN16_A & SPN16_B.  See SPN 7472 for alternate resolution.";
CM_ SG_ 2566810366 EngOilLevelRemoteReservoir "Ratio of current volume of engine oil in a remote reservoir to the maximum required volume.  If a single switch (on/off) is used, 20% and 100% respectively will be used where 100% means no oil needs to be added and 20% means oil needs to be added ...";
CM_ BO_ 2566767102 "Engine Fluid Level/Pressure 3
3rd PGN which identifies parameters that are either measuring various pressures within the engine or identifying engine fluid levels";
CM_ SG_ 2566767102 EngThrottleValve1DiffPress "The differential pressure between the intake and outlet of the throttle valve 1 (SPN 51).  The differential pressure is measured from the intake with respect to the outlet of the throttle valve.";
CM_ SG_ 2566767102 EngExhstGsRcrclation1OutletPress "EGR outlet pressure is measured immediately after the EGR valve.";
CM_ SG_ 2566767102 EngExhstVlvActtionSystemOilPress "The absolute pressure of the oil in the hydraulic system that powers the engine exhaust valve actuation system";
CM_ SG_ 2566767102 EngExhstGsRcrclation1IntakePress "EGR intake gage pressure is measured after the EGR cooler and before the EGR valve.";
CM_ SG_ 2566767102 EngIntkVlvActationSystemOilPress "The gage pressure of the oil in the hydraulic system that powers the engine intake valve actuation system";
CM_ BO_ 2566839294 "Engine Fluid Level/Pressure 2
2nd PGN which identifies parameters that are either measuring various pressures within the engine or identifying engine fluid levels";
CM_ SG_ 2566839294 EngInjectorMeteringRail2Press "The gage pressure of fuel in the metering rail #2 as delivered from the supply pump to the injector metering intake.  See Figure SPN16_A for fuel system related parameters.  Although the figure does not show rail #2 it does show the relationship of ...";
CM_ SG_ 2566839294 EngInjectorTimingRail1Press "The gage pressure of fuel in the timing rail delivered from the supply pump to the injector timing intake.";
CM_ SG_ 2566839294 EngInjectorMeteringRail1Press "The gage pressure of fuel in the primary, or first, metering rail as delivered from the supply pump to the injector metering intake.";
CM_ SG_ 2566839294 EngInjectionCtrlPress "The gage pressure of the engine oil in the hydraulic accumulator that powers an intensifier used for fuel injection.";
CM_ BO_ 2566844414 "Engine Fluid Level/Pressure 1
PGN which identifies parameters that are either measuring various pressures within the engine or identifying engine fluid levels";
CM_ SG_ 2566844414 EngCoolantLevel "Ratio of volume of liquid found in engine cooling system to total cooling system volume.  Typical monitoring location is in the coolant expansion tank.";
CM_ SG_ 2566844414 EngCoolantPress "Gage pressure of liquid found in engine cooling system.

See SPN 20 for alternate range and resolution.";
CM_ SG_ 2566844414 EngCrankcasePress "First instance of the gage pressure inside engine crankcase.";
CM_ SG_ 2566844414 EngOilPress "Gage pressure of oil in engine lubrication system as provided by oil pump.  See SPN 7468 for alternate resolution.";
CM_ SG_ 2566844414 EngOilLevel "Ratio of current volume of engine sump oil to maximum required volume.";
CM_ SG_ 2566844414 EngExCrankcaseBlowbyPress "Differential crankcase blow-by pressure as measured through a tube with a venturi. 

(SPN 1264 is not to be used - obsolete)";
CM_ SG_ 2566844414 EngFuelDeliveryPress "Gage pressure of fuel in system as delivered from supply pump to the injection pump.  See SPN 7469 for alternate resolution.

See also SPN 5578 for Fuel Delivery Absolute Pressure.";
CM_ BO_ 2633929726 "Engine Electrical System/Module Information";
CM_ SG_ 2633929726 SafetyWireStatus "Status signal which indicates that the safety wire has been activated.  When the safety wire is activated, the engine will not operate.  This is used for maintenance purposes.
00 - Safety wire has not been activated
01 - Safety wire has been ...";
CM_ SG_ 2633929726 ElectricalLoad "Electrical power delivered by the engine to the electrical system connected to the generator.";
CM_ BO_ 2566772222 "Electronic Engine Controller 5
Engine related parameters";
CM_ SG_ 2566772222 EngVrblGeometryTurbo1ActuatorPos "Sensor that measures the position of the variable geometry turbocharger actuator.  A  position of 0% indicates the actuator is in the position creating the smallest geometry turbocharger. A position of 100% represents the largest geometry ...";
CM_ SG_ 2566772222 EngVriableGeometryTurbo1CtrlMode "Indicates if the variable geometry turbocharger control status is either open loop or closed loop.

00 open loop
01 closed loop
10 SAE reserved
11 not available";
CM_ SG_ 2566772222 EngFuelCtrlCtrlMode "Indicates whether the Engine Fuel Control System is in open loop or closed loop.

00     Open loop
01     Closed loop
10     SAE reserved
11     Not available";
CM_ SG_ 2566772222 EngVrblGmtryTrbArCtrlShtoffValve "Isolates vehicle brake air from the Variable Geometry Turbocharger (VGT) system when engine is not running.  This valve prevents vehicle air from bleeding off through the VGT Control Valve when engine is not in use.  Primary vehicle air system from ...";
CM_ SG_ 2566772222 EngExhstGsRcirculation1ValveCtrl "Desired percentage of maximum Exhaust Gas Recirculation (EGR) valve 1 opening.  0% means valve is closed. 100% means maximum valve opening (full gas flow).";
CM_ SG_ 2566772222 EngTrb1ClclatedTurbineOutletTemp "Calculated value of turbocharger compressor outlet air temperature.  Temperature of air exiting the turbocharger compressor and before entering charge air cooler.  The estimate is based on turbo speed and measured turbocharger compressor intake ...";
CM_ SG_ 2566772222 EngTrb1ClclatedTurbineIntakeTemp "Calculated value of turbine intake temperature based on engine operating conditions, such as intake manifold temperature, charge fuel ratio, injection timing, and engine speed.  Use SPN 1180 for actual measured intake temperature.";
CM_ BO_ 2633940734 "Electronic Engine Controller 4";
CM_ SG_ 2633940734 CrnkAttmptCntOnPrsntStartAttempt "Reports the number of cranking cycles undergone during the present start attempt.
Note:  This is intended to be used in conjunction with Maximum Crank Attempts per Start Attempt, in order to give a FMI 0 diagnostic on this parameter when the count ...";
CM_ SG_ 2633940734 EngIntakeManifoldPressCtrlMode "Indicates that the Boost Pressure Closed Loop Control status either open loop or closed loop.

00  Open loop 
01  Closed loop 
10  SAE reserved
11  Not available";
CM_ SG_ 2633940734 EngRotationDirection "Direction of engine rotation, as reported by the engine.  Direction convention as viewed by an observer standing at the rear of the engine, viewing the flywheel.
00 - CounterClockWise (CCW)
01 - ClockWise (CW)
10 - Unknown  (Rotation Direction ...";
CM_ SG_ 2633940734 EngRatedSpeed "The maximum governed rotational velocity of the engine crankshaft under full load conditions.  Note that the engine speed at point 2 (SPN 528) is equal to rated engine speed only in the case when the engine has not been derated.  Please also ...";
CM_ SG_ 2633940734 EngRatedPower "Net brake power that the engine will deliver continuously, specified for a given application at a rated speed.";
CM_ BO_ 2566840318 "Electronic Engine Controller 3";
CM_ SG_ 2566840318 AFT2ExhDewPoint "Indicates that the temperature on the exhaust side of the aftertreatment has exceeded the dew point, as estimated by the ECU in exhaust bank 2.

00 - Not exceeded the dew point
01 - Exceeded the dew point
10 - Error
11 - Not available";
CM_ SG_ 2566840318 AFT2InDewPoint "Indicates that the temperature on the intake side of the aftertreatment system has exceeded the dew point, as estimated by the ECU in exhaust bank 2.

00 - Not exceeded the dew point
01 - Exceeded the dew point
10 - Error
11 - Not available";
CM_ SG_ 2566840318 AFT1ExhDewPoint "Indicates that the temperature on the exhaust side of the aftertreatment has exceeded the dew point, as estimated by the ECU in exhaust bank 1.

00 - Not exceeded the dew point
01 - Exceeded the dew point
10 - Error
11 - Not available";
CM_ SG_ 2566840318 AFT1InDewPoint "Indicates that the temperature on the intake side of the aftertreatment system has exceeded the dew point, as estimated by the ECU in exhaust bank 1.

00 - Not exceeded the dew point
01 - Exceeded the dew point
10 - Error
11 - Not available";
CM_ SG_ 2566840318 AFT1ExhGasMFR "Measured/calculated exhaust gas mass upstream of the aftertreatment system in exhaust bank 1 and 2.";
CM_ SG_ 2566840318 EstEngPrsiticLossesPercentTorque "The calculated torque that indicates the estimated amount of torque loss due to engine parasitics, such as cooling fan, air compressor, air conditioning, etc. It is expressed as a percent of Engine Reference Torque.
If there are multiple devices on ...";
CM_ SG_ 2566840318 EngnsDsrdOprtngSpdAsymmtryAdjstm "This byte is utilized in transmission gear selection routines and indicates the engine's preference of lower versus higher engine speeds should its desired speed not be achievable.  This is a scaled ratio such that 125 represents an equal preference ...";
CM_ SG_ 2566840318 EnginesDesiredOperatingSpeed "An indication by the engine of the optimal operating speed of the engine for the current existing conditions.  These conditions may include the torque generated to accommodate powertrain demands from the operator (via the accelerator pedal), cruise ...";
CM_ SG_ 2566840318 NominalFrictionPercentTorque "The calculated torque that indicates the amount of torque required by the basic engine itself added by the loss torque of accessories. It contains the frictional and thermodynamic loss of the engine itself, pumping torque loss (SPN 5398), and the ...";
CM_ BO_ 2364539902 "Electronic Engine Controller 2
Identifies electronic engine control related parameters.";
CM_ SG_ 2364539902 EstPumpingPercentTorque "The calculated torque that indicates the estimated amount of torque loss due to the engine air handling system. The value transmitted in this parameter is included in SPN 514 (Nominal Friction - Percent Torque).  The data is transmitted as a percent ...";
CM_ SG_ 2364539902 ActlMaxAvailableEngPercentTorque "This is the maximum amount of torque that the engine can immediately deliver as a percentage of the reference engine torque (SPN 544).  The Actual Maximum Available Engine - Percent Torque shall take into consideration all engine torque derates ...";
CM_ SG_ 2364539902 SCRThermalManagementActive "Indicates that the exhaust temperatures have been elevated for regeneration of the SCR aftertreatment system or in preparation of regeneration of the SCR aftertreatment system.
00 - SCR Thermal Management is not active
01 - SCR Thermal Management ...";
CM_ SG_ 2364539902 DPFThermalManagementActive "Indicates that the exhaust temperatures have been elevated for regeneration of the diesel particulate filter aftertreatment system or in preparation of regeneration of the diesel particulate aftertreatment system.
00 - DPF Thermal Management is not ...";
CM_ SG_ 2364539902 MmntaryEngMaxPowerEnableFeedback "Momentarily requesting Engine Maximum Power Enable - feature support feedback

00 disabled
01 supported 
10 reserved
11 don't care";
CM_ SG_ 2364539902 VhcleAccelerationRateLimitStatus "Status (active or not active) of the system used to limit maximum forward vehicle acceleration.
00     Limit not active
01     Limit active
10     Reserved
11     Not available
NOTE:  The effects of emission control limits, such as engine ...";
CM_ SG_ 2364539902 AccelPedalPos2 "The ratio of actual position of the second analog engine speed/torque request input device (such as an accelerator pedal or throttle lever) to the maximum position of the input device.  This parameter is intended for secondary accelerator control in ...";
CM_ SG_ 2364539902 RemoteAccelPedalPos "The ratio of actual position of the remote analog engine speed/torque request input device (such as an accelerator pedal or throttle lever) to the maximum position of the input device.
For example, in on-highway vehicles this could be an ...";
CM_ SG_ 2364539902 EngPercentLoadAtCurrentSpeed "The ratio of actual engine percent torque (indicated) to maximum indicated torque available at the current engine speed, clipped to zero torque during engine braking.";
CM_ SG_ 2364539902 AccelPedalPos1 "The ratio of actual position of the analog engine speed/torque request input device (such as an accelerator pedal or throttle lever) to the maximum position of the input device.  This parameter is intended for the primary accelerator control in an ...";
CM_ SG_ 2364539902 AccelPedal2LowIdleSwitch "Switch signal which indicates the state of the accelerator pedal 2 low idle switch.  The low idle switch is defined in SAE J1843.
00    Accelerator pedal 2 not in low idle condition
01    Accelerator pedal 2 in low idle condition
10    Error
11 ...";
CM_ SG_ 2364539902 RoadSpeedLimitStatus "Status (active or not active) of the system used to limit maximum vehicle velocity.
00 - Active
01 - Not Active
10 - Error
11 - Not available
NOTE - While somewhat inconsistent with other J1939 status parameters, the states defining 00 = active ...";
CM_ SG_ 2364539902 AccelPedalKickdownSwitch "Switch signal which indicates whether the accelerator pedal kickdown switch is opened or closed.  The kickdown switch is defined in SAE J1843.

00 - Kickdown passive
01 - Kickdown active
10 - Error
11 - Not available";
CM_ SG_ 2364539902 AccelPedal1LowIdleSwitch "Switch signal which indicates the state of the accelerator pedal 1 low idle switch.  The low idle switch is defined in SAE Recommended Practice J1843.
00 - Accelerator pedal 1 not in low idle condition
01 - Accelerator pedal 1 in low idle ...";
CM_ BO_ 2364540158 "Electronic Engine Controller 1
Engine related parameters";
CM_ SG_ 2364540158 EngDemandPercentTorque "The requested torque output of the engine by all dynamic internal inputs, including smoke control, noise control and low and high speed governing.";
CM_ SG_ 2364540158 EngStarterMode "There are several phases in a starting action and different reasons why a start cannot take place.
0000 start not requested
0001 starter active, gear not engaged
0010 starter active, gear engaged
0011 start finished; starter not active after ...";
CM_ SG_ 2364540158 SrcAddrssOfCntrllngDvcForEngCtrl "The source address of the SAE J1939 device currently controlling the engine.  It is used to expand the torque mode parameter (see SPN 899) in cases where control is in response to an ECU that is not listed in Table SPN899_A.  Its value may be the ...";
CM_ SG_ 2364540158 EngSpeed "Actual engine speed which is calculated over a minimum crankshaft angle of 720 degrees divided by the number of cylinders.";
CM_ SG_ 2364540158 ActualEngPercentTorque "The calculated output torque of the engine.  The data is transmitted in indicated torque as a percent of reference engine torque (see the engine configuration message, PGN 65251).  The engine percent torque value will not be less than zero and it ...";
CM_ SG_ 2364540158 DriversDemandEngPercentTorque "The requested torque output of the engine by the driver. It is based on input from the following requestors external to the powertrain: operator (via the accelerator pedal), cruise control and/or road speed limit governor. Dynamic commands from ...";
CM_ SG_ 2364540158 ActlEngPrcntTorqueHighResolution "This parameter displays an additional torque in percent of the reference engine torque.
When the MSB is set to 1, this parameter is not available.  When the MSB is set to 0, bits 1 to 3 indicate the desired torque with resolution of 0.125%/bit  ...";
CM_ SG_ 2364540158 EngTorqueMode "State signal which indicates which engine torque mode is currently generating, limiting, or controlling the torque.  Note that the modes are not in prioritized order. Not all modes may be relevant for a given device.  Some devices may not implement ...";
CM_ BO_ 2566768126 "ECU Identification Information
Message for reporting identification and information about the physical ECU and its hardware, such as the ECU's part number, serial number, build date, etc.  Information about the software within the ECU should be ...";
CM_ SG_ 2566768126 ECUHardwareID "The ECU Hardware ID provides information to identify a specific ECU hardware version.
As an example, on a CAN network, this parameter can be used to uniquely identify the hardware version that is relevant for the interface of the ECU to the CAN ...";
CM_ SG_ 2566768126 ECUManufacturerName "The name of the manufacturer of the physical ECU.

This name may be different than the manufacturer identified by the Manufacturer Code (SPN 2838) and listed in table B10 of J1939.";
CM_ SG_ 2566768126 ECUType "The type of ECU.  One example of a use of the ECU type could be for classifying ECU capabilities, such as I/O.";
CM_ SG_ 2566768126 ECULocation "The location of the ECU within a network.";
CM_ SG_ 2566768126 ECUSerialNumber "The serial number of the physical ECU.";
CM_ SG_ 2566768126 ECUPartNumber "The part number of the physical ECU.";
CM_ BO_ 2566804734 "Engine Continuous Torque & Speed Limit";
CM_ SG_ 2566804734 EngMinContinuousTorque "Applied limit for minimum continuous engine torque";
CM_ SG_ 2566804734 EngMaxContinuousTorque "Applied limit for maximum continuous engine torque.";
CM_ SG_ 2566804734 EngMinContinuousRPM "Applied limit for minimum continuous engine RPM";
CM_ SG_ 2566804734 EngMaxContinuousRPM "Applied limit for maximum continuous engine RPM";
CM_ SG_ 2566804734 EngHghLmtThrshldFrMnCntnsTrqFrmE "Maximum allowable value for minimum continuous torque from engine";
CM_ SG_ 2566804734 EngLwLmtThrshldFrMxTorqueFromEng "Minimum allowable value for maximum continuous torque from engine";
CM_ SG_ 2566804734 EngHghLmtThrshldFrMnCntnusEngRPM "Maximum allowable value for minimum continuous RPM from engine";
CM_ SG_ 2566804734 EngLwLmtThrsholdForMaxRPMFromEng "Minimum allowable value for maximum continuous RPM from engine";
CM_ BO_ 2566841342 "Engine Configuration 1
This map describes the stationary behavior of the engine and the speed dependent available indicated torque.  This map should reflect the effect of changes due to barometric pressure, engine temperature, and any other ...";
CM_ SG_ 2566841342 SupportTSC1CtrlPurposeGroup4 "This parameter indicates which TSC1 control purposes are supported in group 4 of 4. One bit is used to convey the support of each Control Purpose. A value of 0 equals supported and a value of 1 equals not supported. This bit logic is used to allow ...";
CM_ SG_ 2566841342 SupportTSC1CtrlPurposeGroup3 "This parameter indicates which TSC1 control purposes are supported in group 3 of 4. One bit is used to convey the support of each Control Purpose. A value of 0 equals supported and a value of 1 equals not supported. This bit logic is used to allow ...";
CM_ SG_ 2566841342 SupportTSC1CtrlPurposeGroup2 "This parameter indicates which TSC1 control purposes are supported in group 2 of 4. One bit is used to convey the support of each Control Purpose. A value of 0 equals supported and a value of 1 equals not supported. This bit logic is used to allow ...";
CM_ SG_ 2566841342 SupportTSC1CtrlPurposeGroup1 "This parameter indicates which TSC1 control purposes are supported in group 1 of 4. One bit is used to convey the support of each Control Purpose. A value of 0 equals supported and a value of 1 equals not supported. This bit logic is used to allow ...";
CM_ SG_ 2566841342 SupportVariableRateTSC1Message "This parameter indicates which TSC1 transmission rates are supported by the engine ECU in addition to the required 10ms transmission rate for temporary powertrain control purposes.
Bit Position      Transmission Rate
1                      1000 ms ...";
CM_ SG_ 2566841342 EngDefaultTorqueLimit "Companion parameter to Transmission Torque Limit (SPN 1845).  This 'echo' parameter provides confirmation to the transmission that the engine has received and will invoke the requested Transmission Torque Limit in the event that J1939 communication ...";
CM_ SG_ 2566841342 EngMomentOfInertia "Moment of inertia for the engine, including items driven full-time by the engine such as fuel, oil and cooling pumps.  The inertia from the following items are not included: flywheel, alternator, compressor, fan, and other engine-driven accessories.";
CM_ SG_ 2566841342 EngExRngRqstdSpdCtrlRngUpprLimit "The maximum engine speed regardless of load that the engine will allow when operating in a speed control/limit mode, excluding any maximum momentary engine override speed, if supported.
When the limit is higher than 2500 RPM the 'Requested Speed ...";
CM_ SG_ 2566841342 EngRqstdTrqueCtrlRangeUpperLimit "The maximum engine torque that the engine will allow when operating in a torque control/limit mode.";
CM_ SG_ 2566841342 EngRqstdTrqueCtrlRangeLowerLimit "The minimum engine torque that the engine will allow when operating in a torque control/limit mode.";
CM_ SG_ 2566841342 EngRqstdSpeedCtrlRangeUpperLimit "The maximum engine speed regardless of load that the engine will allow when operating in a speed control/limit mode, excluding any maximum momentary engine override speed, if supported.";
CM_ SG_ 2566841342 EngRqstdSpeedCtrlRangeLowerLimit "The minimum engine speed that the engine will allow when operating in a speed control/limit mode.";
CM_ SG_ 2566841342 EngMaxMomentaryOverrideTimeLimit "The maximum time limit allowed to override the engine's high idle speed.";
CM_ SG_ 2566841342 EngMxMmentaryOverrideSpeedPoint7 "The maximum engine speed above high idle allowed by the engine control during a momentary high idle override.  This duration of the override is limited by the maximum momentary override time limit, SPN 534.";
CM_ SG_ 2566841342 EngReferenceTorque "This parameter is the 100% reference value for all defined indicated engine torque parameters.  It is only defined once and doesn't change if a different engine torque map becomes valid.";
CM_ SG_ 2566841342 EngGain "The endspeed governor is defined as a linear line with the following equations (Capital letters mean physical values, small letters mean normalized values).  Refer to Figures PGN65251_A and PGN65251_B.
The gain KP/kp is defined as a positive value ...";
CM_ SG_ 2566841342 EngSpeedAtHighIdlePoint6 "Engine speed of high idle (point 6) of the engine torque map (see PGN 65251 and supporting document).  In engine configuration mode 3 (see Figure PGN65251_C), point 6 is not defined by the engine torque map but by the governor characteristic and the ...";
CM_ SG_ 2566841342 EngPercentTorqueAtPoint5 "The torque limit that indicates the available engine torque which can be provided by the engine at point 3, 4, and 5 of the engine map (see PGN 65251 and supporting documents).  It is required that one of these points indicate the peak torque point ...";
CM_ SG_ 2566841342 EngSpeedAtPoint5 "Engine speed of point 3, 4, and 5 of the engine torque map (see PGN 65251 and supporting document).  It is recommended that one of these points indicate the peak torque point for the current engine torque map.  Points 3, 4, and 5 are optional and ...";
CM_ SG_ 2566841342 EngPercentTorqueAtPoint4 "The torque limit that indicates the available engine torque which can be provided by the engine at point 3, 4, and 5 of the engine map (see PGN 65251 and supporting documents).  It is required that one of these points indicate the peak torque point ...";
CM_ SG_ 2566841342 EngSpeedAtPoint4 "Engine speed of point 3, 4, and 5 of the engine torque map (see PGN 65251 and supporting document).  It is recommended that one of these points indicate the peak torque point for the current engine torque map.  Points 3, 4, and 5 are optional and ...";
CM_ SG_ 2566841342 EngPercentTorqueAtPoint3 "The torque limit that indicates the available engine torque which can be provided by the engine at point 3, 4, and 5 of the engine map (see PGN 65251 and supporting documents)..  It is required that one of these points indicate the peak torque point ...";
CM_ SG_ 2566841342 EngSpeedAtPoint3 "Engine speed of point 3, 4, and 5 of the engine torque map (see PGN 65251 and supporting document).  It is recommended that one of these points indicate the peak torque point for the current engine torque map.  Points 3, 4, and 5 are optional and ...";
CM_ SG_ 2566841342 EngPercentTorqueAtPoint2 "The torque limit that indicates the available engine torque which can be provided by the engine at point 2 of the engine map (see PGN 65251 and supporting documents).  In engine configuration mode 1 and 3 (see Table PGN65251_A see PGN 65251), point ...";
CM_ SG_ 2566841342 EngSpeedAtPoint2 "Engine speed of point 2 of the engine torque map (see PGN 65251 and supporting document).  In engine configuration mode 1 and 3, point 2 is defined as the kick-in point from which torque is reduced to zero.  In mode 2 (see Table PGN65251_A), there ...";
CM_ SG_ 2566841342 EngPercentTorqueAtIdlePoint1 "The torque limit that indicates the available engine torque which can be provided by the engine at idle speed.  This parameter may be influenced by engine temperature (after power up) and other stationary changes (calibration offsets, sensor ...";
CM_ SG_ 2566841342 EngSpeedAtIdlePoint1 "Stationary low idle speed of engine which includes influences due to engine temperature (after power up) and other stationary changes (calibration offsets, sensor failures, etc).  This parameter is point 1 of the engine configuration map (see PGN ...";
CM_ BO_ 2566767870 "Electronic Brake Controller 5
Used for information on brake control.";
CM_ SG_ 2566767870 EmergencyBrakingActive "Signal which indicates an emergency braking situation (ref. ECE Regulation 13 paragraph 5.2.1.31) with high  deceleration values.  This signal can be used to activate the hazard lights (ref ECE Regulation 48 paragraph 6.23) to
indicate other road ...";
CM_ SG_ 2566767870 PrkngBrakeActuatorFullyActivated "Signal which indicates when the parking brake actuator is fully activated.  (see also SPN 70 and 619).

00 - Parking Brake Actuator not fully activated
01 - Parking Brake Actuator fully activated
10 - Error
11 - Not available";
CM_ SG_ 2566767870 XBRAccelerationLimit "The brake system may temporarily or generally limit the maximum brake performance available for external systems. A temporary limit may be nessary due to high brake temperature; a general limit may be defined by the vehicle manufacturer, e.g. a ...";
CM_ SG_ 2566767870 XBRActiveCtrlMode "This parameter indicates which XBR Control Mode is executed by the brake system.
0000                No brake demand being executed (default mode)
0001                Driver's brake demand being executed, no external brake demand
0010 ...";
CM_ SG_ 2566767870 XBRSystemState "This parameter indicates which external brake control is allowed.
00 - Any external brake demand will be accepted (brake system fully operational)
01 - Only external brake demand of highest XBR Priority (00) will be accepted  (e.g. because the ...";
CM_ SG_ 2566767870 FoundationBrakeUse "This parameter indicates if the brake system presently uses the foundation brakes.

00   Foundation brakes not in use
01   Foundation brakes in use
10   Reserved
11   Not available";
CM_ SG_ 2566767870 HillHolderMode "Signal which indicates the current mode of the hill holder function.
000            Inactive
001            Active
010            Active, but will change to inactive in a short time.  (This mode may be used to warn the driver)
011 ...";
CM_ SG_ 2566767870 HaltBrakeMode "Signal which indicates the current mode of the halt brake function.
000            Inactive
001            Active
010            Active, but not functioning properly.  (This mode may be used to warn the driver)
011 - 101  Not defined
110 ...";
CM_ SG_ 2566767870 BrakeTempWarning "This parameter indicates if the temperature in the service brakes exceeds a certain value. It can be used for a warning information for the driver. The temperature warning value is vehicle manufacturer specific.
00 Not Active
01 Active
10 ...";
CM_ BO_ 2633936126 "Wheel Brake Lining Remaining Information";
CM_ SG_ 2633936126 BrkLnngRmningRearAxle3RightWheel "The percentage of brake lining which can still be measured for the right wheel on the rear axle #3.  100% represents new brake linings, 0% represents totally worn brake linings.";
CM_ SG_ 2633936126 BrkLnngRminingRearAxle3LeftWheel "The percentage of brake lining which can still be measured for the left wheel on the rear axle #3.  100% represents new brake linings, 0% represents totally worn brake linings.";
CM_ SG_ 2633936126 BrkLnngRmningRearAxle2RightWheel "The percentage of brake lining which can still be measured for the right wheel on the rear axle #2.  100% represents new brake linings, 0% represents totally worn brake linings.";
CM_ SG_ 2633936126 BrkLnngRminingRearAxle2LeftWheel "The percentage of brake lining which can still be measured for the left wheel on the rear axle #2.  100% represents new brake linings, 0% represents totally worn brake linings.";
CM_ SG_ 2633936126 BrkLnngRmningRearAxle1RightWheel "The percentage of brake lining which can still be measured for the right wheel on the rear axle #1.  100% represents new brake linings, 0% represents totally worn brake linings.";
CM_ SG_ 2633936126 BrkLnngRminingRearAxle1LeftWheel "The percentage of brake lining which can still be measured for the left wheel on the rear axle #1.  100% represents new brake linings, 0% represents totally worn brake linings.";
CM_ SG_ 2633936126 BrkLnngRmningFrontAxleRightWheel "The percentage of brake lining which can still be measured for the right wheel on the front axle.  100% represents new brake linings, 0% represents totally worn brake linings.";
CM_ SG_ 2633936126 BrkLnngRminingFrontAxleLeftWheel "The percentage of brake lining which can still be measured for the left wheel on the front axle.  100% represents new brake linings, 0% represents totally worn brake linings.";
BA_DEF_ SG_  "SigType" ENUM  "Default","Range","RangeSigned","ASCII","Discrete","Control","ReferencePGN","DTC","StringDelimiter","StringLength","StringLengthControl","MessageCounter","MessageChecksum";
BA_DEF_ SG_  "GenSigStartValue" INT 0 2147483647;
BA_DEF_ SG_  "GenSigSendType" ENUM  "Cyclic","OnWrite","OnWriteWithRepetition","OnChange","OnChangeWithRepetition","IfActive","IfActiveWithRepetition","NoSigSendType";
BA_DEF_ SG_  "GenSigILSupport" ENUM  "No","Yes";
BA_DEF_ SG_  "GenSigEVName" STRING ;
BA_DEF_ SG_  "SPN" INT 0 524287;
BA_DEF_ BO_  "TpJ1939VarDlc" ENUM  "No","Yes";
BA_DEF_ BO_  "GenMsgStartDelayTime" INT 0 100000;
BA_DEF_ BO_  "GenMsgILSupport" ENUM  "No","Yes";
BA_DEF_ BO_  "GenMsgDelayTime" INT 0 1000;
BA_DEF_ BO_  "GenMsgRequestable" INT 0 1;
BA_DEF_ BO_  "GenMsgSendType" ENUM  "cyclic","NotUsed","NotUsed","NotUsed","NotUsed","NotUsed","NotUsed","IfActive","noMsgSendType";
BA_DEF_ BO_  "VFrameFormat" ENUM  "StandardCAN","ExtendedCAN","reserved","J1939PG";
BA_DEF_ BO_  "GenMsgCycleTime" INT 0 3600000;
BA_DEF_ BO_  "SendOnChange" ENUM  "No","Yes";
BA_DEF_ SG_  "SystemSignalLongSymbol" STRING ;
BA_DEF_DEF_  "SigType" "Default";
BA_DEF_DEF_  "GenSigStartValue" 0;
BA_DEF_DEF_  "GenSigSendType" "NoSigSendType";
BA_DEF_DEF_  "GenSigILSupport" "Yes";
BA_DEF_DEF_  "GenSigEVName" "Env@Nodename_@Signame";
BA_DEF_DEF_  "SPN" 0;
BA_DEF_DEF_  "TpJ1939VarDlc" "No";
BA_DEF_DEF_  "GenMsgStartDelayTime" 0;
BA_DEF_DEF_  "GenMsgILSupport" "Yes";
BA_DEF_DEF_  "GenMsgDelayTime" 0;
BA_DEF_DEF_  "GenMsgRequestable" 1;
BA_DEF_DEF_  "GenMsgSendType" "noMsgSendType";
BA_DEF_DEF_  "VFrameFormat" "J1939PG";
BA_DEF_DEF_  "GenMsgCycleTime" 0;
BA_DEF_DEF_  "SendOnChange" "No";
BA_DEF_DEF_  "SystemSignalLongSymbol" "";
BA_ "GenMsgSendType" BO_ 2633883646 0;
BA_ "GenMsgCycleTime" BO_ 2633883646 5000;
BA_ "GenMsgSendType" BO_ 2633880062 0;
BA_ "GenMsgCycleTime" BO_ 2633880062 10000;
BA_ "GenMsgSendType" BO_ 2566806526 0;
BA_ "GenMsgCycleTime" BO_ 2566806526 100;
BA_ "GenMsgCycleTime" BO_ 2431649790 50;
BA_ "GenMsgSendType" BO_ 2633929214 0;
BA_ "GenMsgCycleTime" BO_ 2633929214 1000;
BA_ "GenMsgSendType" BO_ 2566831614 0;
BA_ "GenMsgCycleTime" BO_ 2566831614 1000;
BA_ "GenMsgSendType" BO_ 2364542206 0;
BA_ "GenMsgCycleTime" BO_ 2364542206 20;
BA_ "GenMsgSendType" BO_ 2566802174 0;
BA_ "GenMsgCycleTime" BO_ 2566802174 100;
BA_ "GenMsgSendType" BO_ 2565867006 0;
BA_ "GenMsgCycleTime" BO_ 2565867006 100;
BA_ "GenMsgSendType" BO_ 2364539646 0;
BA_ "GenMsgCycleTime" BO_ 2364539646 10;
BA_ "GenMsgSendType" BO_ 2566810110 0;
BA_ "GenMsgCycleTime" BO_ 2566810110 1000;
BA_ "GenMsgSendType" BO_ 2566825214 0;
BA_ "GenMsgCycleTime" BO_ 2566825214 1000;
BA_ "GenMsgSendType" BO_ 2566844158 0;
BA_ "GenMsgCycleTime" BO_ 2566844158 1000;
BA_ "GenMsgSendType" BO_ 2566785022 0;
BA_ "GenMsgCycleTime" BO_ 2566785022 5000;
BA_ "GenMsgSendType" BO_ 2565868542 0;
BA_ "GenMsgCycleTime" BO_ 2565868542 20;
BA_ "GenMsgDelayTime" BO_ 2633941758 100;
BA_ "GenMsgSendType" BO_ 2633941758 0;
BA_ "GenMsgCycleTime" BO_ 2633941758 1000;
BA_ "GenMsgSendType" BO_ 2565865726 0;
BA_ "GenMsgCycleTime" BO_ 2565865726 100;
BA_ "GenMsgSendType" BO_ 2633932798 0;
BA_ "GenMsgCycleTime" BO_ 2633932798 1000;
BA_ "GenMsgSendType" BO_ 2566824190 0;
BA_ "GenMsgCycleTime" BO_ 2566824190 1000;
BA_ "GenMsgSendType" BO_ 2633933310 0;
BA_ "GenMsgCycleTime" BO_ 2633933310 1000;
BA_ "GenMsgSendType" BO_ 2633933566 0;
BA_ "GenMsgCycleTime" BO_ 2633933566 1000;
BA_ "GenMsgSendType" BO_ 2633933822 0;
BA_ "GenMsgCycleTime" BO_ 2633933822 1000;
BA_ "GenMsgSendType" BO_ 2566776062 0;
BA_ "GenMsgCycleTime" BO_ 2566776062 500;
BA_ "GenMsgSendType" BO_ 2566775806 0;
BA_ "GenMsgCycleTime" BO_ 2566775806 250;
BA_ "GenMsgDelayTime" BO_ 2365447166 20;
BA_ "GenMsgSendType" BO_ 2365447166 0;
BA_ "GenMsgCycleTime" BO_ 2365447166 100;
BA_ "GenMsgDelayTime" BO_ 2365446654 20;
BA_ "GenMsgSendType" BO_ 2365446654 0;
BA_ "GenMsgCycleTime" BO_ 2365446654 100;
BA_ "GenMsgDelayTime" BO_ 2365446142 20;
BA_ "GenMsgSendType" BO_ 2365446142 0;
BA_ "GenMsgCycleTime" BO_ 2365446142 100;
BA_ "GenMsgSendType" BO_ 2633929470 0;
BA_ "GenMsgCycleTime" BO_ 2633929470 100;
BA_ "GenMsgSendType" BO_ 2364541694 0;
BA_ "GenMsgCycleTime" BO_ 2364541694 50;
BA_ "GenMsgSendType" BO_ 2566810366 0;
BA_ "GenMsgCycleTime" BO_ 2566810366 5000;
BA_ "GenMsgSendType" BO_ 2566767102 0;
BA_ "GenMsgCycleTime" BO_ 2566767102 500;
BA_ "GenMsgSendType" BO_ 2566839294 0;
BA_ "GenMsgCycleTime" BO_ 2566839294 5000;
BA_ "GenMsgSendType" BO_ 2566844414 0;
BA_ "GenMsgCycleTime" BO_ 2566844414 5000;
BA_ "GenMsgSendType" BO_ 2633929726 0;
BA_ "GenMsgCycleTime" BO_ 2633929726 100;
BA_ "GenMsgSendType" BO_ 2566840318 0;
BA_ "GenMsgCycleTime" BO_ 2566840318 250;
BA_ "GenMsgSendType" BO_ 2364539902 0;
BA_ "GenMsgCycleTime" BO_ 2364539902 50;
BA_ "GenMsgCycleTime" BO_ 2364540158 50;
BA_ "GenMsgSendType" BO_ 2364540158 0;
BA_ "TpJ1939VarDlc" BO_ 2566768126 1;
BA_ "GenMsgSendType" BO_ 2566804734 0;
BA_ "GenMsgCycleTime" BO_ 2566804734 5000;
BA_ "GenMsgDelayTime" BO_ 2566841342 500;
BA_ "GenMsgSendType" BO_ 2566841342 0;
BA_ "GenMsgCycleTime" BO_ 2566841342 5000;
BA_ "GenMsgSendType" BO_ 2566767870 0;
BA_ "GenMsgCycleTime" BO_ 2566767870 100;
BA_ "SigType" SG_ 2566842878 EngTotalFuelUsed 1;
BA_ "SPN" SG_ 2566842878 EngTotalFuelUsed 250;
BA_ "SigType" SG_ 2566842878 EngTripFuel 1;
BA_ "SPN" SG_ 2566842878 EngTripFuel 182;
BA_ "SigType" SG_ 2633883646 FrontWheelDriveActuatorStatus 4;
BA_ "SPN" SG_ 2633883646 FrontWheelDriveActuatorStatus 2612;
BA_ "SigType" SG_ 2633880062 FMSstandardSWversionSupported 1;
BA_ "SPN" SG_ 2633880062 FMSstandardSWversionSupported 2806;
BA_ "SigType" SG_ 2633880062 FMSstandardRequestsSupported 5;
BA_ "SPN" SG_ 2633880062 FMSstandardRequestsSupported 2805;
BA_ "SigType" SG_ 2633880062 FMSstandardDiagnosticsSupported 5;
BA_ "SPN" SG_ 2633880062 FMSstandardDiagnosticsSupported 2804;
BA_ "SPN" SG_ 2566806526 DrverAlertnessWarningSystemState 7475;
BA_ "SigType" SG_ 2566806526 DriverAlertnessLevel 1;
BA_ "SPN" SG_ 2566806526 DriverAlertnessLevel 7474;
BA_ "SigType" SG_ 2566806526 LnDpartureIndicationEnableStatus 5;
BA_ "SPN" SG_ 2566806526 LnDpartureIndicationEnableStatus 1702;
BA_ "SigType" SG_ 2566806526 LaneTrackingStatusLeftSide 5;
BA_ "SPN" SG_ 2566806526 LaneTrackingStatusLeftSide 1710;
BA_ "SigType" SG_ 2566806526 LaneTrackingStatusRightSide 5;
BA_ "SPN" SG_ 2566806526 LaneTrackingStatusRightSide 1711;
BA_ "SigType" SG_ 2431649790 LaneDepartureImminentLeftSide 5;
BA_ "SPN" SG_ 2431649790 LaneDepartureImminentLeftSide 1700;
BA_ "SigType" SG_ 2431649790 LaneDepartureImminentRightSide 5;
BA_ "SPN" SG_ 2431649790 LaneDepartureImminentRightSide 1701;
BA_ "SigType" SG_ 2431649790 LaneDepartureRight 5;
BA_ "SPN" SG_ 2431649790 LaneDepartureRight 3566;
BA_ "SigType" SG_ 2431649790 LaneDepartureLeft 5;
BA_ "SPN" SG_ 2431649790 LaneDepartureLeft 3565;
BA_ "SPN" SG_ 2431649790 DriverAlertnessWarning 7473;
BA_ "SigType" SG_ 2633929214 EngFuelLeakage2 5;
BA_ "SPN" SG_ 2633929214 EngFuelLeakage2 1240;
BA_ "SigType" SG_ 2633929214 EngFuelLeakage1 5;
BA_ "SPN" SG_ 2633929214 EngFuelLeakage1 1239;
BA_ "SigType" SG_ 2566831614 FanDriveBypassCmdStatus 1;
BA_ "SPN" SG_ 2566831614 FanDriveBypassCmdStatus 4212;
BA_ "SigType" SG_ 2566831614 HydFanMotorPress 1;
BA_ "SPN" SG_ 2566831614 HydFanMotorPress 4211;
BA_ "SigType" SG_ 2566831614 FanSpeed 1;
BA_ "SPN" SG_ 2566831614 FanSpeed 1639;
BA_ "SPN" SG_ 2566831614 FanDriveState 977;
BA_ "SigType" SG_ 2566831614 EstPercentFanSpeed 1;
BA_ "SPN" SG_ 2566831614 EstPercentFanSpeed 975;
BA_ "SigType" SG_ 2566820094 EngTorqueLimit6AxleInput 1;
BA_ "SPN" SG_ 2566820094 EngTorqueLimit6AxleInput 1263;
BA_ "SigType" SG_ 2566820094 EngTorqueLimit5Switch 1;
BA_ "SPN" SG_ 2566820094 EngTorqueLimit5Switch 1262;
BA_ "SigType" SG_ 2566820094 EngTorqueLimit4Trans 1;
BA_ "SPN" SG_ 2566820094 EngTorqueLimit4Trans 1261;
BA_ "SigType" SG_ 2566820094 EngTorqueLimit3Trans 1;
BA_ "SPN" SG_ 2566820094 EngTorqueLimit3Trans 1260;
BA_ "SigType" SG_ 2566820094 TransGearRatio3 1;
BA_ "SPN" SG_ 2566820094 TransGearRatio3 1259;
BA_ "SigType" SG_ 2566820094 EngTorqueLimit2Trans 1;
BA_ "SPN" SG_ 2566820094 EngTorqueLimit2Trans 1258;
BA_ "SigType" SG_ 2566820094 TransGearRatio2 1;
BA_ "SPN" SG_ 2566820094 TransGearRatio2 1257;
BA_ "SigType" SG_ 2566820094 EngTorqueLimit1Trans 1;
BA_ "SPN" SG_ 2566820094 EngTorqueLimit1Trans 1256;
BA_ "SigType" SG_ 2566820094 TransGearRatio1 1;
BA_ "SPN" SG_ 2566820094 TransGearRatio1 1255;
BA_ "SPN" SG_ 2566820094 EngTorqueLimitFeature 1632;
BA_ "SigType" SG_ 2566820094 TorqueLimitingFeatureStatus 5;
BA_ "SPN" SG_ 2566820094 TorqueLimitingFeatureStatus 1254;
BA_ "SigType" SG_ 2566820094 CalibRecordDurationTime 1;
BA_ "SPN" SG_ 2566820094 CalibRecordDurationTime 1253;
BA_ "SigType" SG_ 2566820094 CalibRecordStartYear 1;
BA_ "SPN" SG_ 2566820094 CalibRecordStartYear 1252;
BA_ "SigType" SG_ 2566820094 CalibRecordStartDay 1;
BA_ "GenSigStartValue" SG_ 2566820094 CalibRecordStartDay 1;
BA_ "SPN" SG_ 2566820094 CalibRecordStartDay 1251;
BA_ "SigType" SG_ 2566820094 CalibRecordStartMonth 1;
BA_ "GenSigStartValue" SG_ 2566820094 CalibRecordStartMonth 1;
BA_ "SPN" SG_ 2566820094 CalibRecordStartMonth 1250;
BA_ "SigType" SG_ 2566820094 EngPeakTorque2 1;
BA_ "SPN" SG_ 2566820094 EngPeakTorque2 1249;
BA_ "SigType" SG_ 2566820094 EngPeakTorque1 1;
BA_ "SPN" SG_ 2566820094 EngPeakTorque1 1248;
BA_ "SigType" SG_ 2566820094 EngPower 1;
BA_ "SPN" SG_ 2566820094 EngPower 1247;
BA_ "SigType" SG_ 2566820094 NumberOfEngTorqueHistoryRecords 1;
BA_ "SPN" SG_ 2566820094 NumberOfEngTorqueHistoryRecords 1246;
BA_ "SigType" SG_ 2364542206 TransClutch_ConverterInputSpeed 1;
BA_ "SPN" SG_ 2364542206 TransClutch_ConverterInputSpeed 5052;
BA_ "SigType" SG_ 2364542206 TransTorqueConverterRatio 1;
BA_ "SPN" SG_ 2364542206 TransTorqueConverterRatio 3030;
BA_ "SigType" SG_ 2566802174 TransAutoNeutralSt 5;
BA_ "SPN" SG_ 2566802174 TransAutoNeutralSt 7696;
BA_ "SigType" SG_ 2566802174 TransWarningIndicator 5;
BA_ "SPN" SG_ 2566802174 TransWarningIndicator 5344;
BA_ "SigType" SG_ 2566802174 TrnsRverseGearShiftInhibitStatus 4;
BA_ "SPN" SG_ 2566802174 TrnsRverseGearShiftInhibitStatus 4261;
BA_ "SigType" SG_ 2566802174 TransMode8Indicator 4;
BA_ "SPN" SG_ 2566802174 TransMode8Indicator 4253;
BA_ "SigType" SG_ 2566802174 TransMode7Indicator 4;
BA_ "SPN" SG_ 2566802174 TransMode7Indicator 4252;
BA_ "SigType" SG_ 2566802174 TransMode6Indicator 4;
BA_ "SPN" SG_ 2566802174 TransMode6Indicator 4251;
BA_ "SigType" SG_ 2566802174 TransMode5Indicator 4;
BA_ "SPN" SG_ 2566802174 TransMode5Indicator 4250;
BA_ "SigType" SG_ 2566802174 TransRequestedGearFeedback 1;
BA_ "SPN" SG_ 2566802174 TransRequestedGearFeedback 3289;
BA_ "SigType" SG_ 2566802174 TransMode1Indicator 4;
BA_ "SPN" SG_ 2566802174 TransMode1Indicator 2536;
BA_ "SigType" SG_ 2566802174 TransMode2Indicator 4;
BA_ "SPN" SG_ 2566802174 TransMode2Indicator 2537;
BA_ "SigType" SG_ 2566802174 TransMode3Indicator 4;
BA_ "SPN" SG_ 2566802174 TransMode3Indicator 2538;
BA_ "SigType" SG_ 2566802174 TransMode4Indicator 4;
BA_ "SPN" SG_ 2566802174 TransMode4Indicator 2539;
BA_ "SigType" SG_ 2566802174 TransShiftInhibitIndicator 5;
BA_ "SPN" SG_ 2566802174 TransShiftInhibitIndicator 1851;
BA_ "SigType" SG_ 2566802174 TransEngCrankEnable 5;
BA_ "SPN" SG_ 2566802174 TransEngCrankEnable 2900;
BA_ "SigType" SG_ 2566802174 ActiveShiftConsoleIndicator 5;
BA_ "SPN" SG_ 2566802174 ActiveShiftConsoleIndicator 2945;
BA_ "SigType" SG_ 2566802174 TransReadyForBrakeRelease 5;
BA_ "SPN" SG_ 2566802174 TransReadyForBrakeRelease 3086;
BA_ "SigType" SG_ 2566802174 TrnsRqstedRangeDisplayFlashState 5;
BA_ "SPN" SG_ 2566802174 TrnsRqstedRangeDisplayFlashState 1849;
BA_ "SigType" SG_ 2566802174 TrnsRqstedRangeDisplayBlankState 5;
BA_ "SPN" SG_ 2566802174 TrnsRqstedRangeDisplayBlankState 1850;
BA_ "SigType" SG_ 2566802174 TransServiceIndicator 5;
BA_ "SPN" SG_ 2566802174 TransServiceIndicator 4178;
BA_ "SigType" SG_ 2566802174 TransAirSupplyPressIndicator 4;
BA_ "SPN" SG_ 2566802174 TransAirSupplyPressIndicator 6566;
BA_ "SigType" SG_ 2566802174 TransMode10Indicator 4;
BA_ "SPN" SG_ 2566802174 TransMode10Indicator 6568;
BA_ "SigType" SG_ 2566802174 TransMode9Indicator 4;
BA_ "SPN" SG_ 2566802174 TransMode9Indicator 6567;
BA_ "SigType" SG_ 2566802174 TrnsCrrentRangeDisplayBlankState 5;
BA_ "SPN" SG_ 2566802174 TrnsCrrentRangeDisplayBlankState 4176;
BA_ "SigType" SG_ 2633935870 ClutchLifeRemaining 1;
BA_ "SPN" SG_ 2633935870 ClutchLifeRemaining 2983;
BA_ "SigType" SG_ 2633935870 LowestPossibleGear 1;
BA_ "SPN" SG_ 2633935870 LowestPossibleGear 1114;
BA_ "SigType" SG_ 2633935870 HighestPossibleGear 1;
BA_ "SPN" SG_ 2633935870 HighestPossibleGear 1115;
BA_ "SigType" SG_ 2633935870 RecommendedGear 1;
BA_ "SPN" SG_ 2633935870 RecommendedGear 1113;
BA_ "SigType" SG_ 2633942014 TransForwardDirectionSwitch 5;
BA_ "SPN" SG_ 2633942014 TransForwardDirectionSwitch 903;
BA_ "SigType" SG_ 2633942014 TransNeutralSwitch 5;
BA_ "SPN" SG_ 2633942014 TransNeutralSwitch 604;
BA_ "SigType" SG_ 2633942014 TransReverseDirectionSwitch 5;
BA_ "SPN" SG_ 2633942014 TransReverseDirectionSwitch 767;
BA_ "SigType" SG_ 2633942014 TransLowRangeSenseSwitch 5;
BA_ "SPN" SG_ 2633942014 TransLowRangeSenseSwitch 779;
BA_ "SigType" SG_ 2633942014 TransHighRangeSenseSwitch 5;
BA_ "SPN" SG_ 2633942014 TransHighRangeSenseSwitch 778;
BA_ "SigType" SG_ 2633942526 TransSynchronizerBrakeValue 1;
BA_ "SPN" SG_ 2633942526 TransSynchronizerBrakeValue 54;
BA_ "SigType" SG_ 2633942526 TransSynchronizerClutchValue 1;
BA_ "SPN" SG_ 2633942526 TransSynchronizerClutchValue 53;
BA_ "SigType" SG_ 2633943038 TransInertiaBrakeActuator 5;
BA_ "SPN" SG_ 2633943038 TransInertiaBrakeActuator 787;
BA_ "SigType" SG_ 2633943038 TransDefuelActuator 5;
BA_ "SPN" SG_ 2633943038 TransDefuelActuator 786;
BA_ "SigType" SG_ 2633943038 TransLockupClutchActuator 5;
BA_ "SPN" SG_ 2633943038 TransLockupClutchActuator 740;
BA_ "SigType" SG_ 2633943038 TransClutchActuator 5;
BA_ "SPN" SG_ 2633943038 TransClutchActuator 788;
BA_ "SigType" SG_ 2633943038 TransSplitterIndirectActuator 5;
BA_ "SPN" SG_ 2633943038 TransSplitterIndirectActuator 771;
BA_ "SigType" SG_ 2633943038 TransSplitterDirectActuator 5;
BA_ "SPN" SG_ 2633943038 TransSplitterDirectActuator 770;
BA_ "SigType" SG_ 2633943038 TransRangeLowActuator 5;
BA_ "SPN" SG_ 2633943038 TransRangeLowActuator 769;
BA_ "SigType" SG_ 2633943038 TransRangeHighActuator 5;
BA_ "SPN" SG_ 2633943038 TransRangeHighActuator 768;
BA_ "SigType" SG_ 2633943038 TransShiftFingerGearActuator2 5;
BA_ "SPN" SG_ 2633943038 TransShiftFingerGearActuator2 784;
BA_ "SigType" SG_ 2633943038 TransShiftFingerRailActuator2 5;
BA_ "SPN" SG_ 2633943038 TransShiftFingerRailActuator2 783;
BA_ "SigType" SG_ 2633943038 TransShiftFingerGearActuator1 5;
BA_ "SPN" SG_ 2633943038 TransShiftFingerGearActuator1 773;
BA_ "SigType" SG_ 2633943038 TransShiftFingerRailActuator1 5;
BA_ "SPN" SG_ 2633943038 TransShiftFingerRailActuator1 772;
BA_ "SigType" SG_ 2633943038 TrnsShftFngerCenterRailIndicator 5;
BA_ "SPN" SG_ 2633943038 TrnsShftFngerCenterRailIndicator 782;
BA_ "SigType" SG_ 2633943038 TrnsShftFngerEngagementIndicator 5;
BA_ "SPN" SG_ 2633943038 TrnsShftFngerEngagementIndicator 781;
BA_ "SigType" SG_ 2633943038 TransShiftFingerNeutralIndicator 5;
BA_ "SPN" SG_ 2633943038 TransShiftFingerNeutralIndicator 780;
BA_ "SigType" SG_ 2633943038 TransShiftFingerRailPos 1;
BA_ "SPN" SG_ 2633943038 TransShiftFingerRailPos 60;
BA_ "SigType" SG_ 2633943038 TransShiftFingerGearPos 1;
BA_ "SPN" SG_ 2633943038 TransShiftFingerGearPos 59;
BA_ "SigType" SG_ 2565867006 TransCurrentRange 1;
BA_ "SPN" SG_ 2565867006 TransCurrentRange 163;
BA_ "SigType" SG_ 2565867006 TransRequestedRange 1;
BA_ "SPN" SG_ 2565867006 TransRequestedRange 162;
BA_ "SigType" SG_ 2565867006 TransCurrentGear 1;
BA_ "SPN" SG_ 2565867006 TransCurrentGear 523;
BA_ "SigType" SG_ 2565867006 TransActualGearRatio 1;
BA_ "SPN" SG_ 2565867006 TransActualGearRatio 526;
BA_ "SigType" SG_ 2565867006 TransSelectedGear 1;
BA_ "SPN" SG_ 2565867006 TransSelectedGear 524;
BA_ "SPN" SG_ 2364539646 SrcAddrssOfCntrllngDvcFrTrnsCtrl 1482;
BA_ "SigType" SG_ 2364539646 TransInputShaftSpeed 1;
BA_ "SPN" SG_ 2364539646 TransInputShaftSpeed 161;
BA_ "SigType" SG_ 2364539646 MomentaryEngMaxPowerEnable 5;
BA_ "SPN" SG_ 2364539646 MomentaryEngMaxPowerEnable 5015;
BA_ "SigType" SG_ 2364539646 ProgressiveShiftDisable 5;
BA_ "SPN" SG_ 2364539646 ProgressiveShiftDisable 607;
BA_ "SigType" SG_ 2364539646 EngMomentaryOverspeedEnable 5;
BA_ "SPN" SG_ 2364539646 EngMomentaryOverspeedEnable 606;
BA_ "SigType" SG_ 2364539646 PercentClutchSlip 1;
BA_ "SPN" SG_ 2364539646 PercentClutchSlip 522;
BA_ "SigType" SG_ 2364539646 TransOutputShaftSpeed 1;
BA_ "SPN" SG_ 2364539646 TransOutputShaftSpeed 191;
BA_ "SigType" SG_ 2364539646 TrnsTrqCnvrtrLckpTrnstnInProcess 4;
BA_ "SPN" SG_ 2364539646 TrnsTrqCnvrtrLckpTrnstnInProcess 4816;
BA_ "SigType" SG_ 2364539646 TransShiftInProcess 4;
BA_ "SPN" SG_ 2364539646 TransShiftInProcess 574;
BA_ "SigType" SG_ 2364539646 TrnsTorqueConverterLockupEngaged 5;
BA_ "SPN" SG_ 2364539646 TrnsTorqueConverterLockupEngaged 573;
BA_ "SigType" SG_ 2364539646 TransDrivelineEngaged 4;
BA_ "SPN" SG_ 2364539646 TransDrivelineEngaged 560;
BA_ "SigType" SG_ 2566810110 EngChargeAirCooler1OutletTemp 1;
BA_ "SPN" SG_ 2566810110 EngChargeAirCooler1OutletTemp 2630;
BA_ "SigType" SG_ 2566810110 EngIntkVlvActuationSystemOilTemp 1;
BA_ "SPN" SG_ 2566810110 EngIntkVlvActuationSystemOilTemp 2986;
BA_ "SigType" SG_ 2566810110 EngCoolantTemp 1;
BA_ "SPN" SG_ 2566810110 EngCoolantTemp 1637;
BA_ "SigType" SG_ 2566810110 EngIntakeManifold1AirTemp 1;
BA_ "SPN" SG_ 2566810110 EngIntakeManifold1AirTemp 1636;
BA_ "SigType" SG_ 2566825214 EngExhaustGasRecirculation1Temp 1;
BA_ "SPN" SG_ 2566825214 EngExhaustGasRecirculation1Temp 412;
BA_ "SigType" SG_ 2566825214 EngExhstGsRcirculation1DiffPress 1;
BA_ "SPN" SG_ 2566825214 EngExhstGsRcirculation1DiffPress 411;
BA_ "SigType" SG_ 2566825214 EngECUTemp 1;
BA_ "SPN" SG_ 2566825214 EngECUTemp 1136;
BA_ "SigType" SG_ 2566825214 EngOilTemp2 1;
BA_ "SPN" SG_ 2566825214 EngOilTemp2 1135;
BA_ "SigType" SG_ 2566844158 EngIntercoolerThermostatOpening 1;
BA_ "SPN" SG_ 2566844158 EngIntercoolerThermostatOpening 1134;
BA_ "SigType" SG_ 2566844158 EngIntercoolerTemp 1;
BA_ "SPN" SG_ 2566844158 EngIntercoolerTemp 52;
BA_ "SigType" SG_ 2566844158 EngTurboOilTemp 1;
BA_ "SPN" SG_ 2566844158 EngTurboOilTemp 176;
BA_ "SigType" SG_ 2566844158 EngOilTemp1 1;
BA_ "SPN" SG_ 2566844158 EngOilTemp1 175;
BA_ "SigType" SG_ 2566844158 EngFuelTemp1 1;
BA_ "SPN" SG_ 2566844158 EngFuelTemp1 174;
BA_ "SigType" SG_ 2566844158 EngCoolantTemp 1;
BA_ "SPN" SG_ 2566844158 EngCoolantTemp 110;
BA_ "SigType" SG_ 2566785022 EngExhaustManifoldBank1Temp2 1;
BA_ "SPN" SG_ 2566785022 EngExhaustManifoldBank1Temp2 5970;
BA_ "SigType" SG_ 2566785022 EngExhaustManifoldBank2Temp2 1;
BA_ "SPN" SG_ 2566785022 EngExhaustManifoldBank2Temp2 5969;
BA_ "SigType" SG_ 2566785022 EngExhaustGasTempLeftManifold 1;
BA_ "SPN" SG_ 2566785022 EngExhaustGasTempLeftManifold 2434;
BA_ "SigType" SG_ 2566785022 EngExhaustGasTempRightManifold 1;
BA_ "SPN" SG_ 2566785022 EngExhaustGasTempRightManifold 2433;
BA_ "SPN" SG_ 2565868542 TypeOfSteerTrans 2926;
BA_ "SPN" SG_ 2565868542 TypeOfSteerForces 2925;
BA_ "SPN" SG_ 2565868542 SteerType 2924;
BA_ "SigType" SG_ 2565868542 SteerableLiftAxleLoweringInhibit 5;
BA_ "SPN" SG_ 2565868542 SteerableLiftAxleLoweringInhibit 2922;
BA_ "SPN" SG_ 2565868542 StatusOfSteerAxle 2923;
BA_ "SPN" SG_ 2565868542 AxleLocation 2928;
BA_ "SigType" SG_ 2565868542 ActualInnerWheelSteerAngle 1;
BA_ "SPN" SG_ 2565868542 ActualInnerWheelSteerAngle 2927;
BA_ "SigType" SG_ 2633941758 CrsCtrlRetarderActiveSpeedOffset 1;
BA_ "GenSigStartValue" SG_ 2633941758 CrsCtrlRetarderActiveSpeedOffset 32000;
BA_ "SPN" SG_ 2633941758 CrsCtrlRetarderActiveSpeedOffset 7496;
BA_ "SigType" SG_ 2633941758 TransOutputRetarder 5;
BA_ "SPN" SG_ 2633941758 TransOutputRetarder 748;
BA_ "SigType" SG_ 2565865726 ActlMxAvlblRetarderPercentTorque 1;
BA_ "SPN" SG_ 2565865726 ActlMxAvlblRetarderPercentTorque 1717;
BA_ "SigType" SG_ 2565865726 RetarderSelectionNonengine 1;
BA_ "SPN" SG_ 2565865726 RetarderSelectionNonengine 1716;
BA_ "SigType" SG_ 2565865726 DrvrsDemandRetarderPercentTorque 1;
BA_ "SPN" SG_ 2565865726 DrvrsDemandRetarderPercentTorque 1715;
BA_ "SPN" SG_ 2565865726 SrcAddrssOfCntrllngDvcFrRtrdrCtr 1480;
BA_ "SigType" SG_ 2565865726 RetarderRoadSpeedExceeded 5;
BA_ "SPN" SG_ 2565865726 RetarderRoadSpeedExceeded 4234;
BA_ "SigType" SG_ 2565865726 RetarderRoadSpeedLimitSwitch 4;
BA_ "SPN" SG_ 2565865726 RetarderRoadSpeedLimitSwitch 4233;
BA_ "SigType" SG_ 2565865726 RetarderRequestingBrakeLight 5;
BA_ "SPN" SG_ 2565865726 RetarderRequestingBrakeLight 1667;
BA_ "SigType" SG_ 2565865726 EngCoolantLoadIncrease 5;
BA_ "SPN" SG_ 2565865726 EngCoolantLoadIncrease 1082;
BA_ "SigType" SG_ 2565865726 IntendedRetarderPercentTorque 1;
BA_ "SPN" SG_ 2565865726 IntendedRetarderPercentTorque 1085;
BA_ "SigType" SG_ 2565865726 ActualRetarderPercentTorque 1;
BA_ "SPN" SG_ 2565865726 ActualRetarderPercentTorque 520;
BA_ "SigType" SG_ 2565865726 RetarderEnableShiftAssistSwitch 4;
BA_ "SPN" SG_ 2565865726 RetarderEnableShiftAssistSwitch 572;
BA_ "SigType" SG_ 2565865726 RetarderEnableBrakeAssistSwitch 4;
BA_ "SPN" SG_ 2565865726 RetarderEnableBrakeAssistSwitch 571;
BA_ "SPN" SG_ 2565865726 RetarderTorqueMode 900;
BA_ "SigType" SG_ 2633932798 EngExhaustGasPort20Temp 1;
BA_ "SPN" SG_ 2633932798 EngExhaustGasPort20Temp 1156;
BA_ "SigType" SG_ 2633932798 EngExhaustGasPort19Temp 1;
BA_ "SPN" SG_ 2633932798 EngExhaustGasPort19Temp 1155;
BA_ "SigType" SG_ 2633932798 EngExhaustGasPort18Temp 1;
BA_ "SPN" SG_ 2633932798 EngExhaustGasPort18Temp 1154;
BA_ "SigType" SG_ 2633932798 EngExhaustGasPort17Temp 1;
BA_ "SPN" SG_ 2633932798 EngExhaustGasPort17Temp 1153;
BA_ "SigType" SG_ 2566824190 EngExhaustGasPort16Temp 1;
BA_ "SPN" SG_ 2566824190 EngExhaustGasPort16Temp 1152;
BA_ "SigType" SG_ 2566824190 EngExhaustGasPort15Temp 1;
BA_ "SPN" SG_ 2566824190 EngExhaustGasPort15Temp 1151;
BA_ "SigType" SG_ 2566824190 EngExhaustGasPort14Temp 1;
BA_ "SPN" SG_ 2566824190 EngExhaustGasPort14Temp 1150;
BA_ "SigType" SG_ 2566824190 EngExhaustGasPort13Temp 1;
BA_ "SPN" SG_ 2566824190 EngExhaustGasPort13Temp 1149;
BA_ "SigType" SG_ 2633933310 EngExhaustGasPort12Temp 1;
BA_ "SPN" SG_ 2633933310 EngExhaustGasPort12Temp 1148;
BA_ "SigType" SG_ 2633933310 EngExhaustGasPort11Temp 1;
BA_ "SPN" SG_ 2633933310 EngExhaustGasPort11Temp 1147;
BA_ "SigType" SG_ 2633933310 EngExhaustGasPort10Temp 1;
BA_ "SPN" SG_ 2633933310 EngExhaustGasPort10Temp 1146;
BA_ "SigType" SG_ 2633933310 EngExhaustGasPort9Temp 1;
BA_ "SPN" SG_ 2633933310 EngExhaustGasPort9Temp 1145;
BA_ "SigType" SG_ 2633933566 EngExhaustGasPort8Temp 1;
BA_ "SPN" SG_ 2633933566 EngExhaustGasPort8Temp 1144;
BA_ "SigType" SG_ 2633933566 EngExhaustGasPort7Temp 1;
BA_ "SPN" SG_ 2633933566 EngExhaustGasPort7Temp 1143;
BA_ "SigType" SG_ 2633933566 EngExhaustGasPort6Temp 1;
BA_ "SPN" SG_ 2633933566 EngExhaustGasPort6Temp 1142;
BA_ "SigType" SG_ 2633933566 EngExhaustGasPort5Temp 1;
BA_ "SPN" SG_ 2633933566 EngExhaustGasPort5Temp 1141;
BA_ "SigType" SG_ 2633933822 EngExhaustGasPort4Temp 1;
BA_ "SPN" SG_ 2633933822 EngExhaustGasPort4Temp 1140;
BA_ "SigType" SG_ 2633933822 EngExhaustGasPort3Temp 1;
BA_ "SPN" SG_ 2633933822 EngExhaustGasPort3Temp 1139;
BA_ "SigType" SG_ 2633933822 EngExhaustGasPort2Temp 1;
BA_ "SPN" SG_ 2633933822 EngExhaustGasPort2Temp 1138;
BA_ "SigType" SG_ 2633933822 EngExhaustGasPort1Temp 1;
BA_ "SPN" SG_ 2633933822 EngExhaustGasPort1Temp 1137;
BA_ "SigType" SG_ 2566776062 PayloadCapacityPercentage 1;
BA_ "SPN" SG_ 2566776062 PayloadCapacityPercentage 6854;
BA_ "SigType" SG_ 2566776062 PayloadCarryBackWeight 1;
BA_ "SPN" SG_ 2566776062 PayloadCarryBackWeight 6853;
BA_ "SigType" SG_ 2566776062 PayloadWeightConfidence 1;
BA_ "SPN" SG_ 2566776062 PayloadWeightConfidence 6852;
BA_ "SPN" SG_ 2566776062 PayloadWeight 6851;
BA_ "SigType" SG_ 2566776062 PayloadPercentage 1;
BA_ "SPN" SG_ 2566776062 PayloadPercentage 2600;
BA_ "SigType" SG_ 2566771454 DataMemoryUsage 1;
BA_ "SPN" SG_ 2566771454 DataMemoryUsage 2802;
BA_ "SigType" SG_ 2566771454 KeepAliveBatteryConsumption 1;
BA_ "SPN" SG_ 2566771454 KeepAliveBatteryConsumption 2803;
BA_ "SigType" SG_ 2566775806 TravelVelocityCtrlPos 1;
BA_ "SPN" SG_ 2566775806 TravelVelocityCtrlPos 2601;
BA_ "SigType" SG_ 2633935358 EngExhstGsOxygnSnsrClsdLpOprtion 5;
BA_ "SPN" SG_ 2633935358 EngExhstGsOxygnSnsrClsdLpOprtion 1696;
BA_ "SigType" SG_ 2633935358 EngExhstGsOxygnSnsrFlngCrrection 1;
BA_ "SPN" SG_ 2633935358 EngExhstGsOxygnSnsrFlngCrrection 1695;
BA_ "SigType" SG_ 2633935358 EngActualExhaustOxygen 1;
BA_ "SPN" SG_ 2633935358 EngActualExhaustOxygen 1119;
BA_ "SigType" SG_ 2633935358 EngDesiredExhaustOxygen 1;
BA_ "SPN" SG_ 2633935358 EngDesiredExhaustOxygen 1118;
BA_ "SigType" SG_ 2633935358 EngDesiredRatedExhaustOxygen 1;
BA_ "SPN" SG_ 2633935358 EngDesiredRatedExhaustOxygen 1117;
BA_ "SigType" SG_ 2365447166 Joystick3Button13PressedStatus 4;
BA_ "SPN" SG_ 2365447166 Joystick3Button13PressedStatus 6739;
BA_ "SigType" SG_ 2365447166 Joystick3Button14PressedStatus 4;
BA_ "SPN" SG_ 2365447166 Joystick3Button14PressedStatus 6740;
BA_ "SigType" SG_ 2365447166 Joystick3Button15PressedStatus 4;
BA_ "SPN" SG_ 2365447166 Joystick3Button15PressedStatus 6741;
BA_ "SigType" SG_ 2365447166 Joystick3Button16PressedStatus 4;
BA_ "SPN" SG_ 2365447166 Joystick3Button16PressedStatus 6742;
BA_ "SigType" SG_ 2365447166 Jystick3GripXAxisDetentPosStatus 4;
BA_ "SPN" SG_ 2365447166 Jystick3GripXAxisDetentPosStatus 2756;
BA_ "SigType" SG_ 2365447166 Jystick3GripYAxisDetentPosStatus 4;
BA_ "SPN" SG_ 2365447166 Jystick3GripYAxisDetentPosStatus 2757;
BA_ "SigType" SG_ 2365447166 Jystick3ThetaAxisDetentPosStatus 4;
BA_ "SPN" SG_ 2365447166 Jystick3ThetaAxisDetentPosStatus 2758;
BA_ "SPN" SG_ 2365447166 Joystick3ThetaAxisPos 2738;
BA_ "SigType" SG_ 2365447166 Jystck3ThtAxsClckwsPstvPosStatus 4;
BA_ "SPN" SG_ 2365447166 Jystck3ThtAxsClckwsPstvPosStatus 2743;
BA_ "SigType" SG_ 2365447166 Jystck3ThetaAxisNeutralPosStatus 4;
BA_ "SPN" SG_ 2365447166 Jystck3ThetaAxisNeutralPosStatus 2753;
BA_ "SPN" SG_ 2365447166 Joystick3GripYAxisPos 2737;
BA_ "SigType" SG_ 2365447166 Jystck3GrpYAxsLvrFrwrdPstvPsStts 4;
BA_ "SPN" SG_ 2365447166 Jystck3GrpYAxsLvrFrwrdPstvPsStts 2742;
BA_ "SigType" SG_ 2365447166 Jystck3GrpYAxsLvrBckNgtvPsStatus 4;
BA_ "SPN" SG_ 2365447166 Jystck3GrpYAxsLvrBckNgtvPsStatus 2747;
BA_ "SigType" SG_ 2365447166 Jystck3GripYAxisNeutralPosStatus 4;
BA_ "SPN" SG_ 2365447166 Jystck3GripYAxisNeutralPosStatus 2752;
BA_ "SPN" SG_ 2365447166 Joystick3GripXAxisPos 2736;
BA_ "SigType" SG_ 2365447166 Jystck3GrpXAxsLvrRghtPstvPsSttus 4;
BA_ "SPN" SG_ 2365447166 Jystck3GrpXAxsLvrRghtPstvPsSttus 2741;
BA_ "SigType" SG_ 2365447166 Jystck3GrpXAxsLvrLftNgtvPsStatus 4;
BA_ "SPN" SG_ 2365447166 Jystck3GrpXAxsLvrLftNgtvPsStatus 2746;
BA_ "SigType" SG_ 2365447166 Jystck3GripXAxisNeutralPosStatus 4;
BA_ "SPN" SG_ 2365447166 Jystck3GripXAxisNeutralPosStatus 2751;
BA_ "SigType" SG_ 2365447166 Jystck3ThtAxsCntrClckwsNgtvPsStt 4;
BA_ "SPN" SG_ 2365447166 Jystck3ThtAxsCntrClckwsNgtvPsStt 2748;
BA_ "SigType" SG_ 2365446654 Joystick2Button13PressedStatus 4;
BA_ "SPN" SG_ 2365446654 Joystick2Button13PressedStatus 6735;
BA_ "SigType" SG_ 2365446654 Joystick2Button14PressedStatus 4;
BA_ "SPN" SG_ 2365446654 Joystick2Button14PressedStatus 6736;
BA_ "SigType" SG_ 2365446654 Joystick2Button15PressedStatus 4;
BA_ "SPN" SG_ 2365446654 Joystick2Button15PressedStatus 6737;
BA_ "SigType" SG_ 2365446654 Joystick2Button16PressedStatus 4;
BA_ "SPN" SG_ 2365446654 Joystick2Button16PressedStatus 6738;
BA_ "SigType" SG_ 2365446654 Jystick2GripXAxisDetentPosStatus 4;
BA_ "SPN" SG_ 2365446654 Jystick2GripXAxisDetentPosStatus 2719;
BA_ "SigType" SG_ 2365446654 Jystick2GripYAxisDetentPosStatus 4;
BA_ "SPN" SG_ 2365446654 Jystick2GripYAxisDetentPosStatus 2720;
BA_ "SigType" SG_ 2365446654 Jystick2ThetaAxisDetentPosStatus 4;
BA_ "SPN" SG_ 2365446654 Jystick2ThetaAxisDetentPosStatus 2721;
BA_ "SPN" SG_ 2365446654 Joystick2ThetaAxisPos 2701;
BA_ "SigType" SG_ 2365446654 Jystck2ThtAxsClckwsPstvPosStatus 4;
BA_ "SPN" SG_ 2365446654 Jystck2ThtAxsClckwsPstvPosStatus 2706;
BA_ "SigType" SG_ 2365446654 Jystck2ThetaAxisNeutralPosStatus 4;
BA_ "SPN" SG_ 2365446654 Jystck2ThetaAxisNeutralPosStatus 2716;
BA_ "SPN" SG_ 2365446654 Joystick2GripYAxisPos 2700;
BA_ "SigType" SG_ 2365446654 Jystck2GrpYAxsLvrFrwrdPstvPsStts 4;
BA_ "SPN" SG_ 2365446654 Jystck2GrpYAxsLvrFrwrdPstvPsStts 2705;
BA_ "SigType" SG_ 2365446654 Jystck2GrpYAxsLvrBckNgtvPsStatus 4;
BA_ "SPN" SG_ 2365446654 Jystck2GrpYAxsLvrBckNgtvPsStatus 2710;
BA_ "SigType" SG_ 2365446654 Jystck2GripYAxisNeutralPosStatus 4;
BA_ "SPN" SG_ 2365446654 Jystck2GripYAxisNeutralPosStatus 2715;
BA_ "SPN" SG_ 2365446654 Joystick2GripXAxisPos 2699;
BA_ "SigType" SG_ 2365446654 Jystck2GrpXAxsLvrRghtPstvPsSttus 4;
BA_ "SPN" SG_ 2365446654 Jystck2GrpXAxsLvrRghtPstvPsSttus 2704;
BA_ "SigType" SG_ 2365446654 Jystck2GrpXAxsLvrLftNgtvPsStatus 4;
BA_ "SPN" SG_ 2365446654 Jystck2GrpXAxsLvrLftNgtvPsStatus 2709;
BA_ "SigType" SG_ 2365446654 Jystck2GripXAxisNeutralPosStatus 4;
BA_ "SPN" SG_ 2365446654 Jystck2GripXAxisNeutralPosStatus 2714;
BA_ "SigType" SG_ 2365446654 Jystck2ThtAxsCntrClckwsNgtvPsStt 4;
BA_ "SPN" SG_ 2365446654 Jystck2ThtAxsCntrClckwsNgtvPsStt 2711;
BA_ "SigType" SG_ 2365446142 Joystick1Button13PressedStatus 4;
BA_ "SPN" SG_ 2365446142 Joystick1Button13PressedStatus 6731;
BA_ "SigType" SG_ 2365446142 Joystick1Button14PressedStatus 4;
BA_ "SPN" SG_ 2365446142 Joystick1Button14PressedStatus 6732;
BA_ "SigType" SG_ 2365446142 Joystick1Button15PressedStatus 4;
BA_ "SPN" SG_ 2365446142 Joystick1Button15PressedStatus 6733;
BA_ "SigType" SG_ 2365446142 Joystick1Button16PressedStatus 4;
BA_ "SPN" SG_ 2365446142 Joystick1Button16PressedStatus 6734;
BA_ "SigType" SG_ 2365446142 Jystick1GripXAxisDetentPosStatus 4;
BA_ "SPN" SG_ 2365446142 Jystick1GripXAxisDetentPosStatus 2682;
BA_ "SigType" SG_ 2365446142 Jystick1GripYAxisDetentPosStatus 4;
BA_ "SPN" SG_ 2365446142 Jystick1GripYAxisDetentPosStatus 2683;
BA_ "SigType" SG_ 2365446142 Jystick1ThetaAxisDetentPosStatus 4;
BA_ "SPN" SG_ 2365446142 Jystick1ThetaAxisDetentPosStatus 2684;
BA_ "SPN" SG_ 2365446142 Joystick1ThetaAxisPos 2664;
BA_ "SigType" SG_ 2365446142 Jystck1ThtAxsClckwsPstvPosStatus 4;
BA_ "SPN" SG_ 2365446142 Jystck1ThtAxsClckwsPstvPosStatus 2669;
BA_ "SigType" SG_ 2365446142 Jystck1ThetaAxisNeutralPosStatus 4;
BA_ "SPN" SG_ 2365446142 Jystck1ThetaAxisNeutralPosStatus 2679;
BA_ "SPN" SG_ 2365446142 Joystick1GripYAxisPos 2663;
BA_ "SigType" SG_ 2365446142 Jystck1GrpYAxsLvrFrwrdPstvPsStts 4;
BA_ "SPN" SG_ 2365446142 Jystck1GrpYAxsLvrFrwrdPstvPsStts 2668;
BA_ "SigType" SG_ 2365446142 Jystck1GrpYAxsLvrBckNgtvPsStatus 4;
BA_ "SPN" SG_ 2365446142 Jystck1GrpYAxsLvrBckNgtvPsStatus 2673;
BA_ "SigType" SG_ 2365446142 Aftrtrtmnt1DslExhstFldPrprtsPrlm 4;
BA_ "SPN" SG_ 2365446142 Aftrtrtmnt1DslExhstFldPrprtsPrlm 2678;
BA_ "SPN" SG_ 2365446142 Joystick1GripXAxisPos 2662;
BA_ "SigType" SG_ 2365446142 Jystck1GrpXAxsLvrRghtPstvPsSttus 4;
BA_ "SPN" SG_ 2365446142 Jystck1GrpXAxsLvrRghtPstvPsSttus 2667;
BA_ "SigType" SG_ 2365446142 Jystck1GrpXAxsLvrLftNgtvPsStatus 4;
BA_ "SPN" SG_ 2365446142 Jystck1GrpXAxsLvrLftNgtvPsStatus 2672;
BA_ "SigType" SG_ 2365446142 Jystck1GripXAxisNeutralPosStatus 4;
BA_ "SPN" SG_ 2365446142 Jystck1GripXAxisNeutralPosStatus 2677;
BA_ "SigType" SG_ 2365446142 Jystck1ThtAxsCntrClckwsNgtvPsStt 4;
BA_ "SPN" SG_ 2365446142 Jystck1ThtAxsCntrClckwsNgtvPsStt 2674;
BA_ "SigType" SG_ 2633929470 EngFuelRackPos 1;
BA_ "SPN" SG_ 2633929470 EngFuelRackPos 1210;
BA_ "SigType" SG_ 2633929470 EngGasMassFlowRate1 1;
BA_ "SPN" SG_ 2633929470 EngGasMassFlowRate1 1241;
BA_ "SigType" SG_ 2633929470 InstantaneousEstBrakePower 1;
BA_ "SPN" SG_ 2633929470 InstantaneousEstBrakePower 1242;
BA_ "SigType" SG_ 2633929470 EngExhaustGasPress1 1;
BA_ "SPN" SG_ 2633929470 EngExhaustGasPress1 1209;
BA_ "SigType" SG_ 2633929470 EngPrefilterOilPress 1;
BA_ "SPN" SG_ 2633929470 EngPrefilterOilPress 1208;
BA_ "SigType" SG_ 2633937406 TotalECURunTime 1;
BA_ "SPN" SG_ 2633937406 TotalECURunTime 1033;
BA_ "SigType" SG_ 2633937406 TotalECUDistance 1;
BA_ "SPN" SG_ 2633937406 TotalECUDistance 1032;
BA_ "SigType" SG_ 2364541694 EngExhstGsRcrcltion2MassFlowRate 1;
BA_ "SPN" SG_ 2364541694 EngExhstGsRcrcltion2MassFlowRate 5257;
BA_ "SigType" SG_ 2364541694 EngIntakeAirMassFlowRate 1;
BA_ "SPN" SG_ 2364541694 EngIntakeAirMassFlowRate 132;
BA_ "SigType" SG_ 2364541694 EngExhstGsRcrcltion1MassFlowRate 1;
BA_ "SPN" SG_ 2364541694 EngExhstGsRcrcltion1MassFlowRate 2659;
BA_ "SigType" SG_ 2566810366 EngFuelSupplyPumpIntakePress 1;
BA_ "SPN" SG_ 2566810366 EngFuelSupplyPumpIntakePress 7104;
BA_ "SigType" SG_ 2566810366 FuelPumpPrimerStatus 5;
BA_ "SPN" SG_ 2566810366 FuelPumpPrimerStatus 4083;
BA_ "SPN" SG_ 2566810366 EngVentilationStatus 3554;
BA_ "SigType" SG_ 2566810366 EngCoolantPreheatedState 5;
BA_ "SPN" SG_ 2566810366 EngCoolantPreheatedState 3553;
BA_ "SigType" SG_ 2566810366 EngOilPreHeatedState 5;
BA_ "SPN" SG_ 2566810366 EngOilPreHeatedState 3552;
BA_ "SigType" SG_ 2566810366 EngOilPrimingState 5;
BA_ "SPN" SG_ 2566810366 EngOilPrimingState 3551;
BA_ "SigType" SG_ 2566810366 EngOilPrimingPumpSwitch 4;
BA_ "SPN" SG_ 2566810366 EngOilPrimingPumpSwitch 3550;
BA_ "SigType" SG_ 2566810366 EngOilFilterOutletPress 1;
BA_ "SPN" SG_ 2566810366 EngOilFilterOutletPress 3549;
BA_ "SigType" SG_ 2566810366 EngWasteOilReservoirLevel 1;
BA_ "SPN" SG_ 2566810366 EngWasteOilReservoirLevel 3548;
BA_ "SigType" SG_ 2566810366 EngFuelFilterDiffPress 1;
BA_ "SPN" SG_ 2566810366 EngFuelFilterDiffPress 1382;
BA_ "SigType" SG_ 2566810366 EngFuelSupplyPumpIntakeAbsPress 1;
BA_ "SPN" SG_ 2566810366 EngFuelSupplyPumpIntakeAbsPress 1381;
BA_ "SigType" SG_ 2566810366 EngOilLevelRemoteReservoir 1;
BA_ "SPN" SG_ 2566810366 EngOilLevelRemoteReservoir 1380;
BA_ "SigType" SG_ 2566767102 EngThrottleValve1DiffPress 1;
BA_ "SPN" SG_ 2566767102 EngThrottleValve1DiffPress 5631;
BA_ "SigType" SG_ 2566767102 EngExhstGsRcrclation1OutletPress 1;
BA_ "SPN" SG_ 2566767102 EngExhstGsRcrclation1OutletPress 5019;
BA_ "SigType" SG_ 2566767102 EngExhstVlvActtionSystemOilPress 1;
BA_ "SPN" SG_ 2566767102 EngExhstVlvActtionSystemOilPress 4287;
BA_ "SigType" SG_ 2566767102 EngExhstGsRcrclation1IntakePress 1;
BA_ "SPN" SG_ 2566767102 EngExhstGsRcrclation1IntakePress 3358;
BA_ "SigType" SG_ 2566767102 EngIntkVlvActationSystemOilPress 1;
BA_ "SPN" SG_ 2566767102 EngIntkVlvActationSystemOilPress 2948;
BA_ "SigType" SG_ 2566839294 EngInjectorMeteringRail2Press 1;
BA_ "SPN" SG_ 2566839294 EngInjectorMeteringRail2Press 1349;
BA_ "SigType" SG_ 2566839294 EngInjectorTimingRail1Press 1;
BA_ "SPN" SG_ 2566839294 EngInjectorTimingRail1Press 156;
BA_ "SigType" SG_ 2566839294 EngInjectorMeteringRail1Press 1;
BA_ "SPN" SG_ 2566839294 EngInjectorMeteringRail1Press 157;
BA_ "SigType" SG_ 2566839294 EngInjectionCtrlPress 1;
BA_ "SPN" SG_ 2566839294 EngInjectionCtrlPress 164;
BA_ "SigType" SG_ 2566844414 EngCoolantLevel 1;
BA_ "SPN" SG_ 2566844414 EngCoolantLevel 111;
BA_ "SigType" SG_ 2566844414 EngCoolantPress 1;
BA_ "SPN" SG_ 2566844414 EngCoolantPress 109;
BA_ "SigType" SG_ 2566844414 EngCrankcasePress 1;
BA_ "SPN" SG_ 2566844414 EngCrankcasePress 101;
BA_ "SigType" SG_ 2566844414 EngOilPress 1;
BA_ "SPN" SG_ 2566844414 EngOilPress 100;
BA_ "SigType" SG_ 2566844414 EngOilLevel 1;
BA_ "SPN" SG_ 2566844414 EngOilLevel 98;
BA_ "SigType" SG_ 2566844414 EngExCrankcaseBlowbyPress 1;
BA_ "SPN" SG_ 2566844414 EngExCrankcaseBlowbyPress 22;
BA_ "SigType" SG_ 2566844414 EngFuelDeliveryPress 1;
BA_ "SPN" SG_ 2566844414 EngFuelDeliveryPress 94;
BA_ "SigType" SG_ 2633929726 SafetyWireStatus 5;
BA_ "SPN" SG_ 2633929726 SafetyWireStatus 1205;
BA_ "SigType" SG_ 2633929726 ElectricalLoad 1;
BA_ "SPN" SG_ 2633929726 ElectricalLoad 1204;
BA_ "SigType" SG_ 2566772222 EngVrblGeometryTurbo1ActuatorPos 1;
BA_ "SPN" SG_ 2566772222 EngVrblGeometryTurbo1ActuatorPos 2795;
BA_ "SigType" SG_ 2566772222 EngVriableGeometryTurbo1CtrlMode 5;
BA_ "SPN" SG_ 2566772222 EngVriableGeometryTurbo1CtrlMode 5457;
BA_ "SigType" SG_ 2566772222 EngFuelCtrlCtrlMode 5;
BA_ "SPN" SG_ 2566772222 EngFuelCtrlCtrlMode 5323;
BA_ "SigType" SG_ 2566772222 EngVrblGmtryTrbArCtrlShtoffValve 5;
BA_ "SPN" SG_ 2566772222 EngVrblGmtryTrbArCtrlShtoffValve 2792;
BA_ "SigType" SG_ 2566772222 EngExhstGsRcirculation1ValveCtrl 1;
BA_ "SPN" SG_ 2566772222 EngExhstGsRcirculation1ValveCtrl 2791;
BA_ "SigType" SG_ 2566772222 EngTrb1ClclatedTurbineOutletTemp 1;
BA_ "SPN" SG_ 2566772222 EngTrb1ClclatedTurbineOutletTemp 2790;
BA_ "SigType" SG_ 2566772222 EngTrb1ClclatedTurbineIntakeTemp 1;
BA_ "SPN" SG_ 2566772222 EngTrb1ClclatedTurbineIntakeTemp 2789;
BA_ "SigType" SG_ 2633940734 CrnkAttmptCntOnPrsntStartAttempt 1;
BA_ "SPN" SG_ 2633940734 CrnkAttmptCntOnPrsntStartAttempt 3671;
BA_ "SigType" SG_ 2633940734 EngIntakeManifoldPressCtrlMode 5;
BA_ "SPN" SG_ 2633940734 EngIntakeManifoldPressCtrlMode 5465;
BA_ "SigType" SG_ 2633940734 EngRotationDirection 4;
BA_ "SPN" SG_ 2633940734 EngRotationDirection 3669;
BA_ "SigType" SG_ 2633940734 EngRatedSpeed 1;
BA_ "SPN" SG_ 2633940734 EngRatedSpeed 189;
BA_ "SigType" SG_ 2633940734 EngRatedPower 1;
BA_ "SPN" SG_ 2633940734 EngRatedPower 166;
BA_ "SigType" SG_ 2566840318 AFT2ExhDewPoint 5;
BA_ "SPN" SG_ 2566840318 AFT2ExhDewPoint 3240;
BA_ "SigType" SG_ 2566840318 AFT2InDewPoint 5;
BA_ "SPN" SG_ 2566840318 AFT2InDewPoint 3239;
BA_ "SigType" SG_ 2566840318 AFT1ExhDewPoint 5;
BA_ "SPN" SG_ 2566840318 AFT1ExhDewPoint 3238;
BA_ "SigType" SG_ 2566840318 AFT1InDewPoint 5;
BA_ "SPN" SG_ 2566840318 AFT1InDewPoint 3237;
BA_ "SigType" SG_ 2566840318 AFT1ExhGasMFR 1;
BA_ "SPN" SG_ 2566840318 AFT1ExhGasMFR 3236;
BA_ "SigType" SG_ 2566840318 EstEngPrsiticLossesPercentTorque 1;
BA_ "GenSigStartValue" SG_ 2566840318 EstEngPrsiticLossesPercentTorque 125;
BA_ "SPN" SG_ 2566840318 EstEngPrsiticLossesPercentTorque 2978;
BA_ "SigType" SG_ 2566840318 EngnsDsrdOprtngSpdAsymmtryAdjstm 1;
BA_ "SPN" SG_ 2566840318 EngnsDsrdOprtngSpdAsymmtryAdjstm 519;
BA_ "SigType" SG_ 2566840318 EnginesDesiredOperatingSpeed 1;
BA_ "SPN" SG_ 2566840318 EnginesDesiredOperatingSpeed 515;
BA_ "SigType" SG_ 2566840318 NominalFrictionPercentTorque 1;
BA_ "SPN" SG_ 2566840318 NominalFrictionPercentTorque 514;
BA_ "SigType" SG_ 2364539902 EstPumpingPercentTorque 1;
BA_ "SPN" SG_ 2364539902 EstPumpingPercentTorque 5398;
BA_ "SigType" SG_ 2364539902 ActlMaxAvailableEngPercentTorque 1;
BA_ "SPN" SG_ 2364539902 ActlMaxAvailableEngPercentTorque 3357;
BA_ "SigType" SG_ 2364539902 SCRThermalManagementActive 5;
BA_ "SPN" SG_ 2364539902 SCRThermalManagementActive 5400;
BA_ "SigType" SG_ 2364539902 DPFThermalManagementActive 5;
BA_ "SPN" SG_ 2364539902 DPFThermalManagementActive 5399;
BA_ "SigType" SG_ 2364539902 MmntaryEngMaxPowerEnableFeedback 5;
BA_ "SPN" SG_ 2364539902 MmntaryEngMaxPowerEnableFeedback 5021;
BA_ "SigType" SG_ 2364539902 VhcleAccelerationRateLimitStatus 5;
BA_ "SPN" SG_ 2364539902 VhcleAccelerationRateLimitStatus 2979;
BA_ "SigType" SG_ 2364539902 AccelPedalPos2 1;
BA_ "SPN" SG_ 2364539902 AccelPedalPos2 29;
BA_ "SigType" SG_ 2364539902 RemoteAccelPedalPos 1;
BA_ "SPN" SG_ 2364539902 RemoteAccelPedalPos 974;
BA_ "SigType" SG_ 2364539902 EngPercentLoadAtCurrentSpeed 1;
BA_ "SPN" SG_ 2364539902 EngPercentLoadAtCurrentSpeed 92;
BA_ "SigType" SG_ 2364539902 AccelPedalPos1 1;
BA_ "SPN" SG_ 2364539902 AccelPedalPos1 91;
BA_ "SigType" SG_ 2364539902 AccelPedal2LowIdleSwitch 4;
BA_ "SPN" SG_ 2364539902 AccelPedal2LowIdleSwitch 2970;
BA_ "SigType" SG_ 2364539902 RoadSpeedLimitStatus 5;
BA_ "SPN" SG_ 2364539902 RoadSpeedLimitStatus 1437;
BA_ "SigType" SG_ 2364539902 AccelPedalKickdownSwitch 4;
BA_ "SPN" SG_ 2364539902 AccelPedalKickdownSwitch 559;
BA_ "SigType" SG_ 2364539902 AccelPedal1LowIdleSwitch 4;
BA_ "SPN" SG_ 2364539902 AccelPedal1LowIdleSwitch 558;
BA_ "SigType" SG_ 2364540158 EngDemandPercentTorque 1;
BA_ "SPN" SG_ 2364540158 EngDemandPercentTorque 2432;
BA_ "SPN" SG_ 2364540158 EngStarterMode 1675;
BA_ "SPN" SG_ 2364540158 SrcAddrssOfCntrllngDvcForEngCtrl 1483;
BA_ "SigType" SG_ 2364540158 EngSpeed 1;
BA_ "SPN" SG_ 2364540158 EngSpeed 190;
BA_ "SigType" SG_ 2364540158 ActualEngPercentTorque 1;
BA_ "GenSigStartValue" SG_ 2364540158 ActualEngPercentTorque 125;
BA_ "SPN" SG_ 2364540158 ActualEngPercentTorque 513;
BA_ "SigType" SG_ 2364540158 DriversDemandEngPercentTorque 1;
BA_ "GenSigStartValue" SG_ 2364540158 DriversDemandEngPercentTorque 125;
BA_ "SPN" SG_ 2364540158 DriversDemandEngPercentTorque 512;
BA_ "SPN" SG_ 2364540158 ActlEngPrcntTorqueHighResolution 4154;
BA_ "SPN" SG_ 2364540158 EngTorqueMode 899;
BA_ "SigType" SG_ 2566768126 ECUHardwareID 8;
BA_ "SPN" SG_ 2566768126 ECUHardwareID 6714;
BA_ "SigType" SG_ 2566768126 ECUManufacturerName 8;
BA_ "SPN" SG_ 2566768126 ECUManufacturerName 4304;
BA_ "SigType" SG_ 2566768126 ECUType 8;
BA_ "SPN" SG_ 2566768126 ECUType 2904;
BA_ "SigType" SG_ 2566768126 ECULocation 8;
BA_ "SPN" SG_ 2566768126 ECULocation 2903;
BA_ "SigType" SG_ 2566768126 ECUSerialNumber 8;
BA_ "SPN" SG_ 2566768126 ECUSerialNumber 2902;
BA_ "SigType" SG_ 2566768126 ECUPartNumber 8;
BA_ "SPN" SG_ 2566768126 ECUPartNumber 2901;
BA_ "SigType" SG_ 2566804734 EngMinContinuousTorque 1;
BA_ "SPN" SG_ 2566804734 EngMinContinuousTorque 1775;
BA_ "SigType" SG_ 2566804734 EngMaxContinuousTorque 1;
BA_ "SPN" SG_ 2566804734 EngMaxContinuousTorque 1774;
BA_ "SigType" SG_ 2566804734 EngMinContinuousRPM 1;
BA_ "SPN" SG_ 2566804734 EngMinContinuousRPM 1773;
BA_ "SigType" SG_ 2566804734 EngMaxContinuousRPM 1;
BA_ "SPN" SG_ 2566804734 EngMaxContinuousRPM 1772;
BA_ "SigType" SG_ 2566804734 EngHghLmtThrshldFrMnCntnsTrqFrmE 1;
BA_ "SPN" SG_ 2566804734 EngHghLmtThrshldFrMnCntnsTrqFrmE 1771;
BA_ "SigType" SG_ 2566804734 EngLwLmtThrshldFrMxTorqueFromEng 1;
BA_ "SPN" SG_ 2566804734 EngLwLmtThrshldFrMxTorqueFromEng 1770;
BA_ "SigType" SG_ 2566804734 EngHghLmtThrshldFrMnCntnusEngRPM 1;
BA_ "SPN" SG_ 2566804734 EngHghLmtThrshldFrMnCntnusEngRPM 1769;
BA_ "SigType" SG_ 2566804734 EngLwLmtThrsholdForMaxRPMFromEng 1;
BA_ "SPN" SG_ 2566804734 EngLwLmtThrsholdForMaxRPMFromEng 1768;
BA_ "SPN" SG_ 2566841342 SupportTSC1CtrlPurposeGroup4 3348;
BA_ "SPN" SG_ 2566841342 SupportTSC1CtrlPurposeGroup3 3347;
BA_ "SPN" SG_ 2566841342 SupportTSC1CtrlPurposeGroup2 3346;
BA_ "SPN" SG_ 2566841342 SupportTSC1CtrlPurposeGroup1 3345;
BA_ "SPN" SG_ 2566841342 SupportVariableRateTSC1Message 3344;
BA_ "SigType" SG_ 2566841342 EngDefaultTorqueLimit 1;
BA_ "SPN" SG_ 2566841342 EngDefaultTorqueLimit 1846;
BA_ "SigType" SG_ 2566841342 EngMomentOfInertia 1;
BA_ "SPN" SG_ 2566841342 EngMomentOfInertia 1794;
BA_ "SigType" SG_ 2566841342 EngExRngRqstdSpdCtrlRngUpprLimit 1;
BA_ "SPN" SG_ 2566841342 EngExRngRqstdSpdCtrlRngUpprLimit 1712;
BA_ "SigType" SG_ 2566841342 EngRqstdTrqueCtrlRangeUpperLimit 1;
BA_ "GenSigStartValue" SG_ 2566841342 EngRqstdTrqueCtrlRangeUpperLimit 125;
BA_ "SPN" SG_ 2566841342 EngRqstdTrqueCtrlRangeUpperLimit 538;
BA_ "SigType" SG_ 2566841342 EngRqstdTrqueCtrlRangeLowerLimit 1;
BA_ "GenSigStartValue" SG_ 2566841342 EngRqstdTrqueCtrlRangeLowerLimit 125;
BA_ "SPN" SG_ 2566841342 EngRqstdTrqueCtrlRangeLowerLimit 537;
BA_ "SigType" SG_ 2566841342 EngRqstdSpeedCtrlRangeUpperLimit 1;
BA_ "SPN" SG_ 2566841342 EngRqstdSpeedCtrlRangeUpperLimit 536;
BA_ "SigType" SG_ 2566841342 EngRqstdSpeedCtrlRangeLowerLimit 1;
BA_ "SPN" SG_ 2566841342 EngRqstdSpeedCtrlRangeLowerLimit 535;
BA_ "SigType" SG_ 2566841342 EngMaxMomentaryOverrideTimeLimit 1;
BA_ "SPN" SG_ 2566841342 EngMaxMomentaryOverrideTimeLimit 534;
BA_ "SigType" SG_ 2566841342 EngMxMmentaryOverrideSpeedPoint7 1;
BA_ "SPN" SG_ 2566841342 EngMxMmentaryOverrideSpeedPoint7 533;
BA_ "SigType" SG_ 2566841342 EngReferenceTorque 1;
BA_ "SPN" SG_ 2566841342 EngReferenceTorque 544;
BA_ "SigType" SG_ 2566841342 EngGain 1;
BA_ "SPN" SG_ 2566841342 EngGain 545;
BA_ "SigType" SG_ 2566841342 EngSpeedAtHighIdlePoint6 1;
BA_ "SPN" SG_ 2566841342 EngSpeedAtHighIdlePoint6 532;
BA_ "SigType" SG_ 2566841342 EngPercentTorqueAtPoint5 1;
BA_ "GenSigStartValue" SG_ 2566841342 EngPercentTorqueAtPoint5 125;
BA_ "SPN" SG_ 2566841342 EngPercentTorqueAtPoint5 543;
BA_ "SigType" SG_ 2566841342 EngSpeedAtPoint5 1;
BA_ "SPN" SG_ 2566841342 EngSpeedAtPoint5 531;
BA_ "SigType" SG_ 2566841342 EngPercentTorqueAtPoint4 1;
BA_ "GenSigStartValue" SG_ 2566841342 EngPercentTorqueAtPoint4 125;
BA_ "SPN" SG_ 2566841342 EngPercentTorqueAtPoint4 542;
BA_ "SigType" SG_ 2566841342 EngSpeedAtPoint4 1;
BA_ "SPN" SG_ 2566841342 EngSpeedAtPoint4 530;
BA_ "SigType" SG_ 2566841342 EngPercentTorqueAtPoint3 1;
BA_ "GenSigStartValue" SG_ 2566841342 EngPercentTorqueAtPoint3 125;
BA_ "SPN" SG_ 2566841342 EngPercentTorqueAtPoint3 541;
BA_ "SigType" SG_ 2566841342 EngSpeedAtPoint3 1;
BA_ "SPN" SG_ 2566841342 EngSpeedAtPoint3 529;
BA_ "SigType" SG_ 2566841342 EngPercentTorqueAtPoint2 1;
BA_ "GenSigStartValue" SG_ 2566841342 EngPercentTorqueAtPoint2 125;
BA_ "SPN" SG_ 2566841342 EngPercentTorqueAtPoint2 540;
BA_ "SigType" SG_ 2566841342 EngSpeedAtPoint2 1;
BA_ "SPN" SG_ 2566841342 EngSpeedAtPoint2 528;
BA_ "SigType" SG_ 2566841342 EngPercentTorqueAtIdlePoint1 1;
BA_ "GenSigStartValue" SG_ 2566841342 EngPercentTorqueAtIdlePoint1 125;
BA_ "SPN" SG_ 2566841342 EngPercentTorqueAtIdlePoint1 539;
BA_ "SigType" SG_ 2566841342 EngSpeedAtIdlePoint1 1;
BA_ "SPN" SG_ 2566841342 EngSpeedAtIdlePoint1 188;
BA_ "SigType" SG_ 2566767870 EmergencyBrakingActive 5;
BA_ "SPN" SG_ 2566767870 EmergencyBrakingActive 5847;
BA_ "SigType" SG_ 2566767870 PrkngBrakeActuatorFullyActivated 4;
BA_ "SPN" SG_ 2566767870 PrkngBrakeActuatorFullyActivated 5275;
BA_ "SigType" SG_ 2566767870 XBRAccelerationLimit 1;
BA_ "GenSigStartValue" SG_ 2566767870 XBRAccelerationLimit 25;
BA_ "SPN" SG_ 2566767870 XBRAccelerationLimit 2921;
BA_ "SPN" SG_ 2566767870 XBRActiveCtrlMode 2918;
BA_ "SigType" SG_ 2566767870 XBRSystemState 5;
BA_ "SPN" SG_ 2566767870 XBRSystemState 2917;
BA_ "SigType" SG_ 2566767870 FoundationBrakeUse 5;
BA_ "SPN" SG_ 2566767870 FoundationBrakeUse 2919;
BA_ "SPN" SG_ 2566767870 HillHolderMode 2912;
BA_ "SPN" SG_ 2566767870 HaltBrakeMode 2913;
BA_ "SigType" SG_ 2566767870 BrakeTempWarning 5;
BA_ "SPN" SG_ 2566767870 BrakeTempWarning 3839;
BA_ "SigType" SG_ 2633936126 BrkLnngRmningRearAxle3RightWheel 1;
BA_ "SPN" SG_ 2633936126 BrkLnngRmningRearAxle3RightWheel 1106;
BA_ "SigType" SG_ 2633936126 BrkLnngRminingRearAxle3LeftWheel 1;
BA_ "SPN" SG_ 2633936126 BrkLnngRminingRearAxle3LeftWheel 1105;
BA_ "SigType" SG_ 2633936126 BrkLnngRmningRearAxle2RightWheel 1;
BA_ "SPN" SG_ 2633936126 BrkLnngRmningRearAxle2RightWheel 1104;
BA_ "SigType" SG_ 2633936126 BrkLnngRminingRearAxle2LeftWheel 1;
BA_ "SPN" SG_ 2633936126 BrkLnngRminingRearAxle2LeftWheel 1103;
BA_ "SigType" SG_ 2633936126 BrkLnngRmningRearAxle1RightWheel 1;
BA_ "SPN" SG_ 2633936126 BrkLnngRmningRearAxle1RightWheel 1102;
BA_ "SigType" SG_ 2633936126 BrkLnngRminingRearAxle1LeftWheel 1;
BA_ "SPN" SG_ 2633936126 BrkLnngRminingRearAxle1LeftWheel 1101;
BA_ "SigType" SG_ 2633936126 BrkLnngRmningFrontAxleRightWheel 1;
BA_ "SPN" SG_ 2633936126 BrkLnngRmningFrontAxleRightWheel 1100;
BA_ "SigType" SG_ 2633936126 BrkLnngRminingFrontAxleLeftWheel 1;
BA_ "SPN" SG_ 2633936126 BrkLnngRminingFrontAxleLeftWheel 1099;
VAL_ 2633883646 FrontWheelDriveActuatorStatus 3 "Not Available" 2 "Error" 1 "Front Wheel Drive Actuator engaged" 0 "Front Wheel Drive Actuator not engaged" ;
VAL_ 2633880062 FMSstandardRequestsSupported 3 "Don't care" 2 "Reserved" 1 "On request mode is supported" 0 "On request mode is not supported" ;
VAL_ 2633880062 FMSstandardDiagnosticsSupported 1 "Diagnostics Is Supported" 0 "Diagnostics Is Not Supported" 3 "Don't care" 2 "Reserved" ;
VAL_ 2566806526 DrverAlertnessWarningSystemState 7 "Not Available / Not Installed" 4 "System monitoring driver behavior" 3 "System available" 2 "System temporarily not available" 1 "Initializing" 0 "System installed but disabled" ;
VAL_ 2566806526 LnDpartureIndicationEnableStatus 3 "Not Used" 2 "Reserved" 1 "Lane Departure Indication enabled " 0 "Lane Departure indication disabled" ;
VAL_ 2566806526 LaneTrackingStatusLeftSide 3 "Don't care/Take no action" 2 "Reserved" 1 "Tracking Left side" 0 "Not Tracking Left side" ;
VAL_ 2566806526 LaneTrackingStatusRightSide 3 "Don't Care/take no action" 2 "Reserved" 1 "Tracking Right side" 0 "Not Tracking Right side" ;
VAL_ 2431649790 LaneDepartureImminentLeftSide 3 "Not used" 2 "Reserved" 1 "Imminent" 0 "Not imminent" ;
VAL_ 2431649790 LaneDepartureImminentRightSide 3 "Not Used" 2 "Reserved" 1 "Imminent" 0 "Not imminent" ;
VAL_ 2431649790 LaneDepartureRight 3 "Take no action" 2 "Reserved" 1 "Middle of the vehicle departs the lane to the right side" 0 "Middle of the vehicle does not depart the lane to the right side" ;
VAL_ 2431649790 LaneDepartureLeft 3 "Take no action" 2 "Reserved" 1 "Middle of the vehicle departs the lane to the left side" 0 "Middle of the vehicle does not depart the lane to the left side" ;
VAL_ 2431649790 DriverAlertnessWarning 7 "Not Available" 3 "Level 3" 2 "Level 2" 1 "Level 1" 0 "No distracted driving condition detected" ;
VAL_ 2633929214 EngFuelLeakage2 3 "Not available" 2 "Error" 1 "leakage detected" 0 "no leakage detected" ;
VAL_ 2633929214 EngFuelLeakage1 3 "Not available" 2 "Error" 1 "leakage detected" 0 "no leakage detected" ;
VAL_ 2566831614 FanDriveState 15 "Not available" 14 "Other" 13 "Engine brake" 12 "Timer" 11 "A/C system" 10 "Transmission retarder" 9 "Manual control" 8 "Reverse Operation" 7 "Default Operation" 6 "Excessive hydraulic oil temperature" 5 "Excessive transmission oil temperature" 4 "Excessive engine coolant temperature" 3 "Excessive engine oil temperature" 2 "Excessive engine air temperature" 1 "Engine system-General" 0 "Fan off" ;
VAL_ 2566820094 EngTorqueLimitFeature 7 "Not available" 4 "Current torque rating" 3 "Previous torque rating" 2 "First torque rating" 1 "Highest torque rating" 0 "Reserved" ;
VAL_ 2566820094 TorqueLimitingFeatureStatus 3 "Not available" 2 "Error" 1 "Enabled" 0 "Disabled" ;
VAL_ 2566802174 TransAutoNeutralSt 5 "Reserved" 4 "AutoNeutralReq_stateIsInhibited" 3 "AutoNeutralReq_stateAchieved" 2 "AutoNeutralReq_stateIsPending" 7 "Not Available" 6 "Error" 1 "NoReqAutoNeutrReqWldNotBeHonored" 0 "NoReqAutoNeutrReqWouldBeHonored" ;
VAL_ 2566802174 TransWarningIndicator 3 "Not available" 2 "Transmission Warning Indicator is flashing" 1 "Transmission Warning Indicator is on continuously" 0 "Transmission Warning Indicator is off" ;
VAL_ 2566802174 TrnsRverseGearShiftInhibitStatus 3 "Not Available" 2 "Error" 1 "Reverse gear shifts are currently inhibited" 0 "Reverse gear shifts are currently allowed" ;
VAL_ 2566802174 TransMode8Indicator 3 "Not available" 2 "Error" 1 "Transmission Mode 8 active" 0 "Transmission Mode 8 not active" ;
VAL_ 2566802174 TransMode7Indicator 3 "Not available" 2 "Error" 1 "Transmission Mode 7 active" 0 "Transmission Mode 7 not active" ;
VAL_ 2566802174 TransMode6Indicator 3 "Not available" 2 "Error" 1 "Transmission Mode 6 active" 0 "Transmission Mode 6 not active" ;
VAL_ 2566802174 TransMode5Indicator 3 "Not available" 2 "Error" 1 "Transmission Mode 5 active" 0 "Transmission Mode 5 not active" ;
VAL_ 2566802174 TransMode1Indicator 3 "Not available" 2 "Error" 1 "Transmission Mode 1 Active" 0 "Transmission Mode 1 not active" ;
VAL_ 2566802174 TransMode2Indicator 3 "Not available" 2 "Error" 1 "Transmission Mode 2 Active" 0 "Transmission Mode 2 not active" ;
VAL_ 2566802174 TransMode3Indicator 3 "Not available" 2 "Error" 1 "Transmission Mode 3 Active" 0 "Transmission Mode 3 not active" ;
VAL_ 2566802174 TransMode4Indicator 3 "Not available" 2 "Error" 1 "Transmission Mode 4 Active" 0 "Transmission Mode 4 not active" ;
VAL_ 2566802174 TransShiftInhibitIndicator 3 "Take no action" 2 "Active, flashing)" 1 "Active, on continuously)" 0 "Inactive" ;
VAL_ 2566802174 TransEngCrankEnable 3 "Not available" 2 "Error" 1 "Cranking enabled" 0 "Cranking disabled" ;
VAL_ 2566802174 ActiveShiftConsoleIndicator 3 "Not available" 2 "Reserved" 1 "Secondary shift console is active" 0 "Primary shift console is active" ;
VAL_ 2566802174 TransReadyForBrakeRelease 3 "Not available" 2 "Error" 1 "Transmission Ready for Brake Release" 0 "Transmission Not Ready for Brake Release" ;
VAL_ 2566802174 TrnsRqstedRangeDisplayFlashState 3 "Take no action" 2 "Reserved" 1 "Active" 0 "Inactive" ;
VAL_ 2566802174 TrnsRqstedRangeDisplayBlankState 3 "Take no action" 2 "Reserved" 1 "Active" 0 "Inactive" ;
VAL_ 2566802174 TransServiceIndicator 3 "Not available" 2 "Transmission Service Indicator is flashing" 1 "Transmission Service Indicator is on continuously" 0 "Transmission Service Indicator is off" ;
VAL_ 2566802174 TransAirSupplyPressIndicator 7 "Not available" 6 "Error indicator" 5 "Not defined" 4 "Over pressure" 3 "No pressure" 2 "Very low pressure" 1 "Low pressure" 0 "Normal Pressure Range" ;
VAL_ 2566802174 TransMode10Indicator 3 "Not available" 2 "Error indicator" 1 "Transmission Mode 10 active" 0 "Transmission Mode 10 not active" ;
VAL_ 2566802174 TransMode9Indicator 3 "Not available" 2 "Error indicator" 1 "Transmission Mode 9 active" 0 "Transmission Mode 9 not active" ;
VAL_ 2633942014 TransForwardDirectionSwitch 3 "Not Available" 2 "Error" 1 "On" 0 "Off" ;
VAL_ 2633942014 TransNeutralSwitch 3 "Not Available" 2 "Error" 1 "On" 0 "Off" ;
VAL_ 2633942014 TransReverseDirectionSwitch 3 "Not Available" 2 "Error" 1 "On" 0 "Off" ;
VAL_ 2633942014 TransLowRangeSenseSwitch 3 "Not Available" 2 "Error" 1 "On" 0 "Off" ;
VAL_ 2633942014 TransHighRangeSenseSwitch 3 "Not Available" 2 "Error" 1 "On" 0 "Off" ;
VAL_ 2633943038 TransInertiaBrakeActuator 3 "Not Available" 2 "Error" 1 "On" 0 "Off" ;
VAL_ 2633943038 TransDefuelActuator 3 "Not Available" 2 "Error" 1 "On" 0 "Off" ;
VAL_ 2633943038 TransLockupClutchActuator 3 "Not Available" 2 "Error" 1 "On" 0 "Off" ;
VAL_ 2633943038 TransClutchActuator 3 "Not Available" 2 "Error" 1 "On" 0 "Off" ;
VAL_ 2633943038 TransSplitterIndirectActuator 3 "Not Available" 2 "Error" 1 "On" 0 "Off" ;
VAL_ 2633943038 TransSplitterDirectActuator 3 "Not Available" 2 "Error" 1 "On" 0 "Off" ;
VAL_ 2633943038 TransRangeLowActuator 3 "Not Available" 2 "Error" 1 "On" 0 "Off" ;
VAL_ 2633943038 TransRangeHighActuator 3 "- Not available" 2 "- Error" 1 "-On" 0 "-Off" ;
VAL_ 2633943038 TransShiftFingerGearActuator2 3 "Not Available" 2 "Error" 1 "On" 0 "Off" ;
VAL_ 2633943038 TransShiftFingerRailActuator2 3 "Not Available" 2 "Error" 1 "On" 0 "Off" ;
VAL_ 2633943038 TransShiftFingerGearActuator1 3 "Not Available" 2 "Error" 1 "On" 0 "Off" ;
VAL_ 2633943038 TransShiftFingerRailActuator1 3 "Not Available" 2 "Error" 1 "On" 0 "Off" ;
VAL_ 2633943038 TrnsShftFngerCenterRailIndicator 3 "Not Available" 2 "Error" 1 "On" 0 "Off" ;
VAL_ 2633943038 TrnsShftFngerEngagementIndicator 3 "Not Available" 2 "Error" 1 "On" 0 "Off" ;
VAL_ 2633943038 TransShiftFingerNeutralIndicator 3 "Not Available" 2 "Error" 1 "On" 0 "Off" ;
VAL_ 2364539646 MomentaryEngMaxPowerEnable 3 "not available" 2 "fault" 1 "momentarily requesting maximum power available" 0 "not requesting maximum power available" ;
VAL_ 2364539646 ProgressiveShiftDisable 3 "Take no action" 2 "Reserved" 1 "Progressive shift is disabled" 0 "Progressive shift is not disabled" ;
VAL_ 2364539646 EngMomentaryOverspeedEnable 3 "Take no action" 2 "Reserved" 1 "Momentary engine overspeed is enabled" 0 "Momentary engine overspeed is disabled" ;
VAL_ 2364539646 TrnsTrqCnvrtrLckpTrnstnInProcess 3 "Not available" 2 "Error" 1 "Transition is in process" 0 "Transition is not in process" ;
VAL_ 2364539646 TransShiftInProcess 3 "-  Not available" 2 "-  Error" 1 "-  Shift in process" 0 "-  Shift is not in process " ;
VAL_ 2364539646 TrnsTorqueConverterLockupEngaged 3 "Not available" 2 "Error" 1 "Torque converter lockup engaged" 0 "Torque converter lockup disengaged" ;
VAL_ 2364539646 TransDrivelineEngaged 3 "Not available" 2 "Error" 1 "Driveline engaged" 0 "Driveline disengaged" ;
VAL_ 2565868542 TypeOfSteerTrans 15 "Not available" 3 "Hybrid steering transmission" 2 "Purely electric steering transmission" 1 "Purely hydraulic steering transmission" 0 "Purely mechanical steering transmission" ;
VAL_ 2565868542 TypeOfSteerForces 15 "Not Available" 3 "Self tracking steering equipment" 2 "Full power steering equipment" 1 "Power assisted steering equipment" 0 "Manual steering equipment" ;
VAL_ 2565868542 SteerType 15 "Not Available" 1 "Auxiliary steering equipment" 0 "Main steering system" ;
VAL_ 2565868542 SteerableLiftAxleLoweringInhibit 1 "Lowering inhibited" 0 "Lowering allowed" 3 "Not available" 2 "Reserved" ;
VAL_ 2565868542 StatusOfSteerAxle 15 "Not available" 5 "Axle steering in special mode" 4 "Axle not active because of an error" 3 "Axle centered,  because of an error" 2 "Axle centered" 1 "Axle steering active" 0 "Axle steering not active" ;
VAL_ 2633941758 TransOutputRetarder 3 "Not Available" 2 "Error" 1 "On" 0 "Off" ;
VAL_ 2565865726 RetarderRoadSpeedExceeded 3 "Don't care/Take no action" 2 "Reserved" 1 "AboveThresh_RetIsAllowedAct" 0 "Road speed is below threshold" ;
VAL_ 2565865726 RetarderRoadSpeedLimitSwitch 3 "Not Available" 2 "Error Indicator" 1 "Limiting by retarder is enabled" 0 "Limiting by retarder is disabled" ;
VAL_ 2565865726 RetarderRequestingBrakeLight 0 "notReqThatBrkLightsIlluminated" 3 "Not available/Take no action" 2 "Reserved" 1 "ReqThatBrkLightsIlluminated" ;
VAL_ 2565865726 EngCoolantLoadIncrease 3 "Not available" 2 "Error" 1 "Coolant load increase possible" 0 "No coolant load increase" ;
VAL_ 2565865726 RetarderEnableShiftAssistSwitch 3 "Not available" 2 "Error" 1 "Retarder, shift assist enabled" 0 "Retarder, shift assist disabled" ;
VAL_ 2565865726 RetarderEnableBrakeAssistSwitch 3 "Not available" 2 "Error" 1 "Retarder, brake assist enabled" 0 "Retarder, brake assist disabled" ;
VAL_ 2633935358 EngExhstGsOxygnSnsrClsdLpOprtion 3 "Don't Care/take no action" 2 "Reserved" 1 "Engine using the exhaust oxygen sensor for a closed loop operation" 0 "Engine not using the exhaust oxygen sensor" ;
VAL_ 2365447166 Joystick3Button13PressedStatus 3 "Not Available" 2 "Error Indicator" 1 "Button pressed" 0 "Button not pressed" ;
VAL_ 2365447166 Joystick3Button14PressedStatus 3 "Not Available" 2 "Error Indicator" 1 "Button pressed" 0 "Button not pressed" ;
VAL_ 2365447166 Joystick3Button15PressedStatus 3 "Not Available" 2 "Error Indicator" 1 "Button pressed" 0 "Button not pressed" ;
VAL_ 2365447166 Joystick3Button16PressedStatus 3 "Not Available" 2 "Error Indicator" 1 "Button pressed" 0 "Button not pressed" ;
VAL_ 2365447166 Jystick3GripXAxisDetentPosStatus 3 "Not Available" 2 "Error Indicator" 1 "In the Detent Position" 0 "Not in the Detent Position" ;
VAL_ 2365447166 Jystick3GripYAxisDetentPosStatus 3 "Not Available" 2 "Error Indicator" 1 "In the Detent Position" 0 "Not in the Detent Position" ;
VAL_ 2365447166 Jystick3ThetaAxisDetentPosStatus 3 "Not Available" 2 "Error Indicator" 1 "In the Detent Position" 0 "Not in the Detent Position" ;
VAL_ 2365447166 Jystck3ThtAxsClckwsPstvPosStatus 3 "Not Available" 2 "Error Indicator" 1 "On positive side of Neutral" 0 "Not on Positive side of Neutral" ;
VAL_ 2365447166 Jystck3ThetaAxisNeutralPosStatus 3 "Not Available" 2 "Error Indicator" 1 "In Neutral Position" 0 "Not in Neutral Position" ;
VAL_ 2365447166 Jystck3GrpYAxsLvrFrwrdPstvPsStts 3 "Not Available" 2 "Error Indicator" 1 "On positive side of Neutral" 0 "Not on Positive side of Neutral" ;
VAL_ 2365447166 Jystck3GrpYAxsLvrBckNgtvPsStatus 3 "Not Available" 2 "Error Indicator" 1 "On negative side of Neutral" 0 "Not on negative side of Neutral" ;
VAL_ 2365447166 Jystck3GripYAxisNeutralPosStatus 3 "Not Available" 2 "Error Indicator" 1 "In Neutral Position" 0 "Not in Neutral Position" ;
VAL_ 2365447166 Jystck3GrpXAxsLvrRghtPstvPsSttus 3 "Not Available" 2 "Error Indicator" 1 "On positive side of Neutral" 0 "Not on Positive side of Neutral" ;
VAL_ 2365447166 Jystck3GrpXAxsLvrLftNgtvPsStatus 3 "Not Available" 2 "Error Indicator" 1 "On negative side of Neutral" 0 "Not on negative side of Neutral" ;
VAL_ 2365447166 Jystck3GripXAxisNeutralPosStatus 3 "Not Available" 2 "Error Indicator" 1 "On negative side of Neutral" 0 "Not on negative side of Neutral" ;
VAL_ 2365447166 Jystck3ThtAxsCntrClckwsNgtvPsStt 3 "Not Available" 2 "Error Indicator" 1 "On negative side of Neutral" 0 "Not on negative side of Neutral" ;
VAL_ 2365446654 Joystick2Button13PressedStatus 3 "Not Available" 2 "Error Indicator" 1 "Button pressed" 0 "Button not pressed" ;
VAL_ 2365446654 Joystick2Button14PressedStatus 3 "Not Available" 2 "Error Indicator" 1 "Button pressed" 0 "Button not pressed" ;
VAL_ 2365446654 Joystick2Button15PressedStatus 3 "Not Available" 2 "Error Indicator" 1 "Button pressed" 0 "Button not pressed" ;
VAL_ 2365446654 Joystick2Button16PressedStatus 3 "Not Available" 2 "Error Indicator" 1 "Button pressed" 0 "Button not pressed" ;
VAL_ 2365446654 Jystick2GripXAxisDetentPosStatus 3 "Not Available" 2 "Error Indicator" 1 "In the Detent Position" 0 "Not in the Detent Position" ;
VAL_ 2365446654 Jystick2GripYAxisDetentPosStatus 3 "Not Available" 2 "Error Indicator" 1 "In the Detent Position" 0 "Not in the Detent Position" ;
VAL_ 2365446654 Jystick2ThetaAxisDetentPosStatus 3 "Not Available" 2 "Error Indicator" 1 "In the Detent Position" 0 "Not in the Detent Position" ;
VAL_ 2365446654 Jystck2ThtAxsClckwsPstvPosStatus 3 "Not Available" 2 "Error Indicator" 1 "On positive side of Neutral" 0 "Not on Positive side of Neutral" ;
VAL_ 2365446654 Jystck2ThetaAxisNeutralPosStatus 3 "Not Available" 2 "Error Indicator" 1 "In Neutral Position" 0 "Not in Neutral Position" ;
VAL_ 2365446654 Jystck2GrpYAxsLvrFrwrdPstvPsStts 3 "Not Available" 2 "Error Indicator" 1 "On positive side of Neutral" 0 "Not on Positive side of Neutral" ;
VAL_ 2365446654 Jystck2GrpYAxsLvrBckNgtvPsStatus 3 "Not Available" 2 "Error Indicator" 1 "On negative side of Neutral" 0 "Not on negative side of Neutral" ;
VAL_ 2365446654 Jystck2GripYAxisNeutralPosStatus 3 "Not Available" 2 "Error Indicator" 1 "In Neutral Position" 0 "Not in Neutral Position" ;
VAL_ 2365446654 Jystck2GrpXAxsLvrRghtPstvPsSttus 3 "Not Available" 2 "Error Indicator" 1 "On positive side of Neutral" 0 "Not on Positive side of Neutral" ;
VAL_ 2365446654 Jystck2GrpXAxsLvrLftNgtvPsStatus 3 "Not Available" 2 "Error Indicator" 1 "On negative side of Neutral" 0 "Not on negative side of Neutral" ;
VAL_ 2365446654 Jystck2GripXAxisNeutralPosStatus 3 "Not Available" 2 "Error Indicator" 1 "On negative side of Neutral" 0 "Not on negative side of Neutral" ;
VAL_ 2365446654 Jystck2ThtAxsCntrClckwsNgtvPsStt 3 "Not Available" 2 "Error Indicator" 1 "On negative side of Neutral" 0 "Not on negative side of Neutral" ;
VAL_ 2365446142 Joystick1Button13PressedStatus 3 "Not Available" 2 "Error Indicator" 1 "Button pressed" 0 "Button not pressed" ;
VAL_ 2365446142 Joystick1Button14PressedStatus 3 "Not Available" 2 "Error Indicator" 1 "Button pressed" 0 "Button not pressed" ;
VAL_ 2365446142 Joystick1Button15PressedStatus 3 "Not Available" 2 "Error Indicator" 1 "Button pressed" 0 "Button not pressed" ;
VAL_ 2365446142 Joystick1Button16PressedStatus 3 "Not Available" 2 "Error Indicator" 1 "Button pressed" 0 "Button not pressed" ;
VAL_ 2365446142 Jystick1GripXAxisDetentPosStatus 3 "Not Available" 2 "Error Indicator" 1 "In the Detent Position" 0 "Not in the Detent Position" ;
VAL_ 2365446142 Jystick1GripYAxisDetentPosStatus 3 "Not Available" 2 "Error Indicator" 1 "In the Detent Position" 0 "Not in the Detent Position" ;
VAL_ 2365446142 Jystick1ThetaAxisDetentPosStatus 3 "Not Available" 2 "Error Indicator" 1 "In the Detent Position" 0 "Not in the Detent Position" ;
VAL_ 2365446142 Jystck1ThtAxsClckwsPstvPosStatus 3 "Not Available" 2 "Error Indicator" 1 "On positive side of Neutral" 0 "Not on Positive side of Neutral" ;
VAL_ 2365446142 Jystck1ThetaAxisNeutralPosStatus 3 "Not Available" 2 "Error Indicator" 1 "In Neutral Position" 0 "Not in Neutral Position" ;
VAL_ 2365446142 Jystck1GrpYAxsLvrFrwrdPstvPsStts 3 "Not Available" 2 "Error Indicator" 1 "On positive side of Neutral" 0 "Not on Positive side of Neutral" ;
VAL_ 2365446142 Jystck1GrpYAxsLvrBckNgtvPsStatus 3 "Not Available" 2 "Error Indicator" 1 "On negative side of Neutral" 0 "Not on negative side of Neutral" ;
VAL_ 2365446142 Aftrtrtmnt1DslExhstFldPrprtsPrlm 3 "Not Available" 2 "Error Indicator" 1 "In Neutral Position" 0 "Not in Neutral Position" ;
VAL_ 2365446142 Jystck1GrpXAxsLvrRghtPstvPsSttus 3 "Not Available" 2 "Error Indicator" 1 "On positive side of Neutral" 0 "Not on Positive side of Neutral" ;
VAL_ 2365446142 Jystck1GrpXAxsLvrLftNgtvPsStatus 3 "Not Available" 2 "Error Indicator" 1 "On negative side of Neutral" 0 "Not on negative side of Neutral" ;
VAL_ 2365446142 Jystck1GripXAxisNeutralPosStatus 3 "Not Available" 2 "Error Indicator" 1 "In Neutral Position" 0 "Not in Neutral Position" ;
VAL_ 2365446142 Jystck1ThtAxsCntrClckwsNgtvPsStt 3 "Not Available" 2 "Error Indicator" 1 "On negative side of Neutral" 0 "Not on negative side of Neutral" ;
VAL_ 2566810366 FuelPumpPrimerStatus 3 "Unavailable" 2 "Error" 1 "On" 0 "Off" ;
VAL_ 2566810366 EngVentilationStatus 7 "Not available or not installe" 6 "Not able to determine if sufficiently vented" 5 "Reserved for SAE assignment " 4 "Reserved for SAE assignment" 3 "Currently venting" 2 "Ventilation delay" 1 "Ventilation needed" 0 "Sufficiently vented" ;
VAL_ 2566810366 EngCoolantPreheatedState 3 "Not available or not installed" 2 "Unable to determine  engine coolant pre-heated sufficiently" 1 "Sufficiently pre-heated" 0 "Not sufficiently pre-heated" ;
VAL_ 2566810366 EngOilPreHeatedState 1 "Sufficiently pre-heated" 3 "Not available or not installed" 2 "Unable to determine if engine oil is pre-heated sufficiently" 0 "Not sufficiently pre-heated" ;
VAL_ 2566810366 EngOilPrimingState 3 "Not available or not installed" 2 "Unable to determine if sufficiently lubricated" 1 "Sufficiently lubricated" 0 "Not sufficiently lubricated" ;
VAL_ 2566810366 EngOilPrimingPumpSwitch 3 "Not available or not installed" 2 "Error" 1 "On" 0 "Off" ;
VAL_ 2633929726 SafetyWireStatus 3 "Not available" 2 "Error" 1 "Safety wire has been activated" 0 "Safety wire has not been activated" ;
VAL_ 2566772222 EngVriableGeometryTurbo1CtrlMode 3 "not available" 2 "SAE reserved" 1 "closed loop" 0 "open loop" ;
VAL_ 2566772222 EngFuelCtrlCtrlMode 3 "Not available" 2 "SAE reserved" 1 "Closed loop" 0 "Open loop" ;
VAL_ 2566772222 EngVrblGmtryTrbArCtrlShtoffValve 3 "Not available" 2 "Reserved" 1 "VGT Air Control Shutoff Valve is On" 0 "VGT Air Control Shutoff Valve is Off" ;
VAL_ 2633940734 EngIntakeManifoldPressCtrlMode 3 "Not available" 2 "SAE reserved" 1 "Closed loop " 0 "Open loop " ;
VAL_ 2633940734 EngRotationDirection 3 "Not Available" 2 "Unknown " 1 "ClockWise" 0 "CounterClockWise" ;
VAL_ 2566840318 AFT2ExhDewPoint 3 "Not available" 2 "Error" 1 "Exceeded the dew point" 0 "Not exceeded the dew point" ;
VAL_ 2566840318 AFT2InDewPoint 3 "Not available" 2 "Error" 1 "Exceeded the dew point" 0 "Not exceeded the dew point" ;
VAL_ 2566840318 AFT1ExhDewPoint 3 "Not available" 2 "Error" 1 "Exceeded the dew point" 0 "Not exceeded the dew point" ;
VAL_ 2566840318 AFT1InDewPoint 3 "Not available" 2 "Error" 1 "Exceeded the dew point" 0 "Not exceeded the dew point" ;
VAL_ 2364539902 SCRThermalManagementActive 3 "Don't care" 2 "Reserved" 1 "SCR Thermal Management is active" 0 "SCR Thermal Management is not active" ;
VAL_ 2364539902 DPFThermalManagementActive 3 "Don't care" 2 "Reserved" 1 "DPF Thermal Management is active" 0 "DPF Thermal Management is not active" ;
VAL_ 2364539902 MmntaryEngMaxPowerEnableFeedback 3 "don't care" 2 "reserved" 1 "supported " 0 "disabled" ;
VAL_ 2364539902 VhcleAccelerationRateLimitStatus 3 "Not available" 2 "Reserved" 1 "Limit active" 0 "Limit not active" ;
VAL_ 2364539902 AccelPedal2LowIdleSwitch 3 "Not available" 2 "Error" 1 "Accelerator pedal 2 in low idle condition" 0 "Accelerator pedal 2 not in low idle condition" ;
VAL_ 2364539902 RoadSpeedLimitStatus 3 "Not available" 2 "Error" 1 "Not Active" 0 "Active" ;
VAL_ 2364539902 AccelPedalKickdownSwitch 3 "Not available" 2 "Error" 1 "Kickdown active" 0 "Kickdown passive" ;
VAL_ 2364539902 AccelPedal1LowIdleSwitch 3 "Not available" 2 "Error" 1 "Accelerator pedal 1 in low idle condition" 0 "Accelerator pedal 1 not in low idle condition" ;
VAL_ 2364540158 EngStarterMode 8 "InhibDueToStarterOver-temp" 7 "starterInhDueToActiveImmobilizer" 6 "DrivelineEngagedOrOtherTransInh" 5 "InhibDueToEngNotReadyForStart" 4 "starterInhibDueToEngRunning" 3 "start finished" 2 "starterActiveGearEngaged" 1 "starterActiveGearNotEngaged" 0 "start not requested" 15 "not available" 14 "error" 13 "errorLegacyImplementationOnly" 12 "starter inhibited" 11 "Reserved" 10 "ActiveSCRinducement" 9 "IntakeAirShutoffValveBeingActive" ;
VAL_ 2566767870 EmergencyBrakingActive 3 "not available" 2 "reserved" 1 "active" 0 "inactive" ;
VAL_ 2566767870 PrkngBrakeActuatorFullyActivated 3 "Not available" 2 "Error" 1 "Parking Brake Actuator fully activated" 0 "Parking Brake Actuator not fully activated" ;
VAL_ 2566767870 XBRActiveCtrlMode 15 "Not available" 3 "Maximum mode of XBR acceleration control being executed" 2 "Addition mode of XBR acceleration control being executed" 1 "Driver's brake demand being executed" 0 "No brake demand being executed" ;
VAL_ 2566767870 XBRSystemState 3 "not available" 2 "No external brake demand will be accepted" 1 "Only external brake demand of highest XBR Priority" 0 "Any external brake demand will be accepted" ;
VAL_ 2566767870 FoundationBrakeUse 3 "Not available" 2 "Reserved" 1 "Foundation brakes in use" 0 "Foundation brakes not in use" ;
VAL_ 2566767870 HillHolderMode 7 "Not available" 6 "Hill holder not functional" 3 "Active,  but may activate parking brake if needed." 2 "Active,  but will change to inactive in a short time" 1 "Active" 0 "Inactive" ;
VAL_ 2566767870 HaltBrakeMode 7 "Not available" 6 "Halt brake not functional" 2 "Active,  but not functioning properly" 1 "Active" 0 "Inactive" ;
VAL_ 2566767870 BrakeTempWarning 3 "not available" 2 "Reserved" 1 "Active" 0 "Not Active" ;
